VERSION ""

NS_ :

BS_:

BU_: ATCM_DMSM HCM_HS2 PAM_HS2 GSM TRCM GWM _delete SASM SCCM ATCM SUMA_RLM ATCM_FFSM PCU VDM_HS2 TBM OCS GENERIC TSTR RCM

BO_ 1114 TrailerAid_Data_HS2: 8 GWM
 SG_ TrlBrkInitOut_D_Rq : 60|2@0+ (1,0) [0|3] "SED"  TBM
 SG_ TrailCtlSwtch_B_Stat2 : 16|1@0+ (1,0) [0|1] "SED" Vector__XXX

BO_ 939 ParkAid_Aud_Warn_Stat2_HS2: 8 PAM_HS2
 SG_ PrkAidSnsRlSide_D_Stat : 23|4@0+ (1,0) [0|15] "SED"  GWM
 SG_ ApaBrk_D_Rq : 51|2@0+ (1,0) [0|3] "SED"  GWM,GENERIC
 SG_ SidePrkSnsR4_D_Stat : 55|4@0+ (1,0) [0|15] "SED"  GWM,GENERIC
 SG_ SidePrkSnsR3_D_Stat : 47|4@0+ (1,0) [0|15] "SED"  GWM,GENERIC
 SG_ SidePrkSnsL4_D_Stat : 43|4@0+ (1,0) [0|15] "SED"  GWM,GENERIC
 SG_ SidePrkSnsL3_D_Stat : 37|4@0+ (1,0) [0|15] "SED"  GWM,GENERIC
 SG_ PrkAidChime_D_Stat : 4|2@0+ (1,0) [0|3] "SED"  GWM,GENERIC
 SG_ PrkAidSnsRlCntr_D_Stat : 15|4@0+ (1,0) [0|15] "SED"  GWM
 SG_ PrkAidSnsRrCrnr_D_Stat : 31|4@0+ (1,0) [0|15] "SED"  GWM
 SG_ PrkAidSnsRrCntr_D_Stat : 19|4@0+ (1,0) [0|15] "SED"  GWM
 SG_ PrkAidSnsRlCrnr_D_Stat : 11|4@0+ (1,0) [0|15] "SED"  GWM
 SG_ PrkAidRear_D_Stat : 39|2@0+ (1,0) [0|3] "SED"  GWM,GENERIC
 SG_ PrkAidFront_D_Stat : 2|2@0+ (1,0) [0|3] "SED"  GWM,GENERIC
 SG_ PrkAid_D_Falt : 7|3@0+ (1,0) [0|7] "SED"  GWM,GENERIC
 SG_ PrkAidSnsRrSide_D_Stat : 27|4@0+ (1,0) [0|15] "SED"  GWM
 SG_ PrkAidLamp_D_Rq : 33|2@0+ (1,0) [0|3] "SED"  GWM,ATCM_DMSM,GENERIC
 SG_ ApaLongCtrlEnbl_D_Rq : 0|1@0+ (1,0) [0|1] "SED"  GWM
 SG_ ApaBrk_A_Rq : 63|8@0+ (0.05,-12.75) [-12.75|0] "m/sec^2"  GWM

BO_ 938 ParkAid_Aud_Warn_Stat_HS2: 8 PAM_HS2
 SG_ SidePrkSnsR2_D_Stat : 59|4@0+ (1,0) [0|15] "SED"  GWM
 SG_ SidePrkSnsR1_D_Stat : 63|4@0+ (1,0) [0|15] "SED"  GWM
 SG_ SidePrkSnsL2_D_Stat : 51|4@0+ (1,0) [0|15] "SED"  GWM
 SG_ SidePrkSnsL1_D_Stat : 55|4@0+ (1,0) [0|15] "SED"  GWM
 SG_ ApaMde_D_Stat : 23|3@0+ (1,0) [0|7] "SED"  GWM
 SG_ ApaActvSd_D_Actl : 14|2@0+ (1,0) [0|3] "SED"  GWM
 SG_ PrkAidSwtch_B_Stat : 8|1@0+ (1,0) [0|1] "SED"  GWM
 SG_ ApaMde_D_Avail : 12|4@0+ (1,0) [0|15] "SED"  GWM
 SG_ PrkAidSnsFrSide_D_Stat : 43|4@0+ (1,0) [0|15] "SED"  GWM
 SG_ PrkAidSnsFrCrnr_D_Stat : 47|4@0+ (1,0) [0|15] "SED"  GWM
 SG_ PrkAidSnsFrCntr_D_Stat : 35|4@0+ (1,0) [0|15] "SED"  GWM
 SG_ PrkAidSnsFlSide_D_Stat : 39|4@0+ (1,0) [0|15] "SED"  GWM
 SG_ PrkAidSnsFlCrnr_D_Stat : 27|4@0+ (1,0) [0|15] "SED"  GWM
 SG_ PrkAidSnsFlCntr_D_Stat : 31|4@0+ (1,0) [0|15] "SED"  GWM
 SG_ RpaChime_D_Rq : 7|4@0+ (1,0) [0|15] "SED"  GWM
 SG_ FpaChime_D_Rq : 3|4@0+ (1,0) [0|15] "SED"  GWM
 SG_ PrkAidMsgTxt_D_Rq : 19|4@0+ (1,0) [0|15] "SED"  GWM
 SG_ PrkAidAudioMute_B_Rq : 15|1@0+ (1,0) [0|1] "SED"  GWM
 SG_ PrkBrkEl_B_RqFap : 20|1@0+ (1,0) [0|1] "SED"  GWM

BO_ 863 Steering_Data2: 8 SASM
 SG_ SteWhlHeat_D_Stat : 7|4@0+ (1,0) [0|15] "SED"  GWM

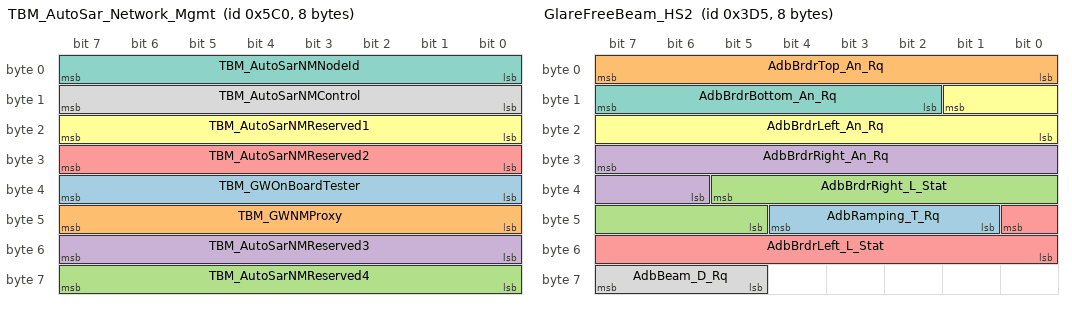
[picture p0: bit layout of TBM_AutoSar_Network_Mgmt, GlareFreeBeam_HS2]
BO_ 1472 TBM_AutoSar_Network_Mgmt: 8 TBM
 SG_ TBM_GWOnBoardTester : 39|8@0+ (1,0) [0|255] "unitless"  GWM
 SG_ TBM_GWNMProxy : 47|8@0+ (1,0) [0|255] "unitless"  GWM
 SG_ TBM_AutoSarNMReserved4 : 63|8@0+ (1,0) [0|255] "unitless"  GWM
 SG_ TBM_AutoSarNMReserved3 : 55|8@0+ (1,0) [0|255] "unitless"  GWM
 SG_ TBM_AutoSarNMReserved2 : 31|8@0+ (1,0) [0|255] "unitless"  GWM
 SG_ TBM_AutoSarNMReserved1 : 23|8@0+ (1,0) [0|255] "unitless"  GWM
 SG_ TBM_AutoSarNMNodeId : 7|8@0+ (1,0) [0|255] "unitless"  GWM
 SG_ TBM_AutoSarNMControl : 15|8@0+ (1,0) [0|255] "unitless"  GWM

BO_ 2612030680 PARSEDPushFcGWM_ECGtoGSM: 8 GWM
 SG_ PARSEDPushFcGWM_ECGtoGSM : 7|29@0+ (1,0) [0|536870911] "unitless"  GSM

BO_ 981 GlareFreeBeam_HS2: 8 GWM
 SG_ AdbRamping_T_Rq : 44|4@0+ (200,0) [0|3000] "millisecond"  HCM_HS2
 SG_ AdbBrdrTop_An_Rq : 7|8@0+ (0.04,-9.54) [-9.54|0.58] "degrees"  HCM_HS2
 SG_ AdbBrdrRight_L_Stat : 37|9@0+ (2,0) [0|1018] "meter"  HCM_HS2
 SG_ AdbBrdrRight_An_Rq : 31|10@0+ (0.04,-20.4) [-20.4|20.44] "degrees"  HCM_HS2
 SG_ AdbBrdrLeft_L_Stat : 40|9@0+ (2,0) [0|1018] "meter"  HCM_HS2
 SG_ AdbBrdrLeft_An_Rq : 9|10@0+ (0.04,-20.4) [-20.4|20.44] "degrees"  HCM_HS2
 SG_ AdbBrdrBottom_An_Rq : 15|6@0+ (0.04,-1.86) [-1.86|0.58] "degrees"  HCM_HS2
 SG_ AdbBeam_D_Rq : 63|3@0+ (1,0) [0|7] "SED"  HCM_HS2

BO_ 2611175451 PARSEDPhysGSMtoGWM_ECG: 8 GSM
 SG_ PARSEDPhysGSMtoGWM_ECG : 7|29@0+ (1,0) [0|536870911] "Unitless"  GWM

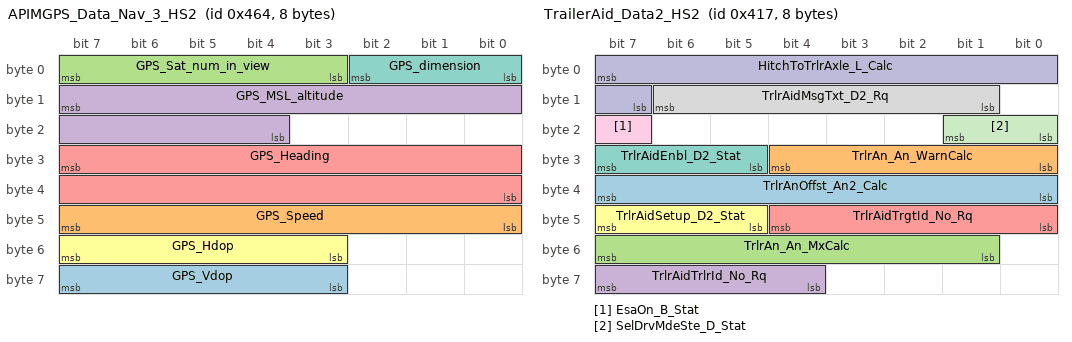
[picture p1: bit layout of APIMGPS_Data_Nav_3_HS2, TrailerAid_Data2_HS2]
BO_ 1124 APIMGPS_Data_Nav_3_HS2: 8 GWM
 SG_ GPS_Vdop : 63|5@0+ (0.2,0) [0|5.8] "unitless"  GENERIC
 SG_ GPS_Speed : 47|8@0+ (1,0) [0|253] "MPH"  GENERIC
 SG_ GPS_Sat_num_in_view : 7|5@0+ (1,0) [0|29] "unitless"  GENERIC
 SG_ GPS_MSL_altitude : 15|12@0+ (10,-20460) [-20460|20470] "feet"  GENERIC
 SG_ GPS_Heading : 31|16@0+ (0.01,0) [0|655.33] "Degrees" Vector__XXX
 SG_ GPS_Hdop : 55|5@0+ (0.2,0) [0|5.8] "unitless"  GENERIC
 SG_ GPS_dimension : 2|3@0+ (1,0) [0|7] "SED"  GENERIC

BO_ 1844 TesterPhysicalReqHCM_HS2: 8 TSTR
 SG_ TesterPhysicalReqHCM : 7|64@0+ (1,0) [0|1.84467E+019] "unitless"  HCM_HS2

BO_ 1852 TesterPhysicalResHCM_HS2: 8 HCM_HS2
 SG_ TesterPhysicalResHCM : 7|64@0+ (1,0) [0|1.84467E+019] "unitless"  TSTR

BO_ 989 Personality_HCM_Data_HS2: 8 HCM_HS2
 SG_ FeatNoHcm_No_Actl : 23|16@0+ (1,0) [0|65535] "Number"  GWM
 SG_ FeatConfigHcmActl : 7|16@0+ (1,0) [0|65535] "Undefined"  GWM

BO_ 2612002008 PARSEDFuncGWM_ECG_HS2: 8 GWM
 SG_ PARSEDFuncGWM_ECG : 7|29@0+ (1,0) [0|536870911] "unitless"  ATCM_DMSM,HCM_HS2,GSM

BO_ 2610953432 OTAFuncGWM_ECG_HS2: 8 GWM
 SG_ OTAFuncGWM_ECG : 7|29@0+ (1,0) [0|536870911] "unitless"  HCM_HS2,GSM,ATCM_DMSM

BO_ 2609933528 OTAPhysGWM_ECGtoGSM: 8 GWM
 SG_ OTAPhysGWM_ECGtoGSM : 7|29@0+ (1,0) [0|536870911] "unitless"  GSM

BO_ 2610126875 OTAPhysGSMtoGWM_ECG: 8 GSM
 SG_ OTAPhysGSMtoGWM_ECG : 7|29@0+ (1,0) [0|536870911] "unitless"  GWM

BO_ 1105 Image_Processing_Data_HS2: 8 GWM
 SG_ TrlrRvrseEnbl_D2_Stat : 18|3@0+ (1,0) [0|7] "SED"  GENERIC,PAM_HS2
 SG_ TrlrRvrseMsgTxt_D2_Rq : 31|6@0+ (1,0) [0|63] "SED"  GENERIC,PAM_HS2
 SG_ RbaMsg_D_Rq : 22|2@0+ (1,0) [0|3] "SED"  GENERIC
 SG_ BrkDecel_B_RqRba : 8|1@0+ (1,0) [0|1] "SED"  GENERIC
 SG_ BrkEnbl_B_RqRba : 23|1@0+ (1,0) [0|1] "SED"  GENERIC
 SG_ Rba_D_Stat : 14|2@0+ (1,0) [0|3] "SED"  GENERIC
 SG_ RbaAlrt_D_Dsply : 12|2@0+ (1,0) [0|3] "SED"  GENERIC
 SG_ RbaMnu_D_Rq : 10|2@0+ (1,0) [0|3] "SED"  GENERIC
 SG_ RbaSys_D_Stat : 20|2@0+ (1,0) [0|3] "SED"  GENERIC
 SG_ CamraFrntStat_D_Stat : 7|2@0+ (1,0) [0|3] "SED"  GENERIC
 SG_ TrlrHitchLamp_D_Rq2 : 15|1@0+ (1,0) [0|1] "SED"  GENERIC
 SG_ ClrExitAsstMsgTxt2_D_Rq : 55|4@0+ (1,0) [0|15] "SED"  GENERIC
 SG_ ClrExitAsstActv_B_Rq : 24|1@0+ (1,0) [0|1] "SED"  GENERIC
 SG_ CamraFrntOffRd_B_Stat : 25|1@0+ (1,0) [0|1] "SED"  GENERIC
 SG_ TrlrAidSwtchLamp_B_Rq : 32|1@0+ (1,0) [0|1] "SED"  ATCM,ATCM_DMSM,ATCM_FFSM
 SG_ TrlrAidEnbl_D_RqAdas : 5|3@0+ (1,0) [0|7] "SED"  GENERIC
 SG_ TrlrHitchMsgTxt_D_Rq : 47|6@0+ (1,0) [0|63] "SED"  GENERIC
 SG_ TrlrHitchIcon_D_Rq : 36|4@0+ (1,0) [0|15] "SED"  GENERIC
 SG_ TrlrHitchChime_D_Rq : 39|3@0+ (1,0) [0|7] "SED"  GENERIC

BO_ 1056 SelectDriveModeData_HS2: 8 GWM
 SG_ SelDrvMdePos12_B_Avail : 54|1@0+ (1,0) [0|1] "SED" Vector__XXX
 SG_ SelDrvMdePos11_B_Avail : 55|1@0+ (1,0) [0|1] "SED" Vector__XXX
 SG_ SelDrvMdePos10_B_Avail : 40|1@0+ (1,0) [0|1] "SED" Vector__XXX
 SG_ SelDrvMdePos09_B_Avail : 41|1@0+ (1,0) [0|1] "SED" Vector__XXX
 SG_ SelDrvMdePos08_B_Avail : 42|1@0+ (1,0) [0|1] "SED" Vector__XXX
 SG_ SelDrvMdePos07_B_Avail : 43|1@0+ (1,0) [0|1] "SED" Vector__XXX
 SG_ SelDrvMdePos06_B_Avail : 44|1@0+ (1,0) [0|1] "SED" Vector__XXX
 SG_ SelDrvMdePos05_B_Avail : 45|1@0+ (1,0) [0|1] "SED" Vector__XXX
 SG_ SelDrvMdePos04_B_Avail : 46|1@0+ (1,0) [0|1] "SED" Vector__XXX
 SG_ SelDrvMdePos03_B_Avail : 47|1@0+ (1,0) [0|1] "SED" Vector__XXX
 SG_ SelDrvMdePos02_B_Avail : 32|1@0+ (1,0) [0|1] "SED" Vector__XXX
 SG_ SelDrvMdePos01_B_Avail : 24|1@0+ (1,0) [0|1] "SED" Vector__XXX
 SG_ ActvDrvMde_D2_Stat : 53|5@0+ (1,0) [0|31] "SED" Vector__XXX
 SG_ SelDrvMde_D2_Rq : 63|5@0+ (1,0) [0|31] "SED"  ATCM_DMSM
 SG_ AwdMde_D_RqBrk : 35|3@0+ (1,0) [0|7] "SED" Vector__XXX
 SG_ SelDrvMdePt_D_Rq : 31|5@0+ (1,0) [0|31] "SED" Vector__XXX
 SG_ SelDrvMdeMsgTxt_D_Rq : 19|4@0+ (1,0) [0|15] "SED"  ATCM_DMSM
 SG_ SelDrvMde_D_Stat : 26|2@0+ (1,0) [0|3] "SED" Vector__XXX
 SG_ AutoEpbButtnOn_B_Stat : 48|1@0+ (1,0) [0|1] "SED"  GENERIC
 SG_ AutoEpbMsgTxt_D_Rq : 58|3@0+ (1,0) [0|7] "SED"  GENERIC
 SG_ AutoEpbDsply_D_Stat : 37|2@0+ (1,0) [0|3] "SED"  GENERIC
 SG_ SelDrvMdeHmi03_D_Rq : 12|5@0+ (1,0) [0|31] "SED"  GENERIC
 SG_ SelDrvMdeMsgTxt2_D_Rq : 23|4@0+ (1,0) [0|15] "SED"  GENERIC

BO_ 1047 TrailerAid_Data2_HS2: 8 GWM
 SG_ TrlrAnOffst_An2_Calc : 39|8@0+ (0.5,-64) [-64|63.5] "degrees" Vector__XXX
 SG_ TrlrAn_An_WarnCalc : 28|5@0+ (1,0) [0|31] "degrees" Vector__XXX
 SG_ TrlrAn_An_MxCalc : 55|7@0+ (1,0) [0|127] "degrees" Vector__XXX
 SG_ TrlrAidTrlrId_No_Rq : 63|4@0+ (1,0) [0|15] "unitless" Vector__XXX
 SG_ TrlrAidTrgtId_No_Rq : 44|5@0+ (1,0) [0|31] "unitless" Vector__XXX
 SG_ TrlrAidSetup_D2_Stat : 47|3@0+ (1,0) [0|7] "SED" Vector__XXX
 SG_ TrlrAidEnbl_D2_Stat : 31|3@0+ (1,0) [0|7] "SED"  ATCM_DMSM,PAM_HS2
 SG_ TrlrAidMsgTxt_D2_Rq : 14|6@0+ (1,0) [0|63] "SED"  ATCM_DMSM,PAM_HS2
 SG_ EsaOn_B_Stat : 23|1@0+ (1,0) [0|1] "SED" Vector__XXX
 SG_ HitchToTrlrAxle_L_Calc : 7|9@0+ (0.0254,0) [0|12.9794] "meter" Vector__XXX
 SG_ SelDrvMdeSte_D_Stat : 17|2@0+ (1,0) [0|3] "SED" Vector__XXX

BO_ 1892 TesterPhysicalReqCCM_HS2: 8 TSTR
 SG_ TesterPhysicalReqCCM : 7|64@0+ (1,0) [0|1.84467E+019] "unitless" Vector__XXX

BO_ 1969 TesterPhysicalReqIPMB_HS2: 8 TSTR
 SG_ TesterPhysicalReqIPMB : 7|64@0+ (1,0) [0|1.84467E+019] "unitless" Vector__XXX

BO_ 1798 TesterPhysicalReqIPMA_HS2: 8 TSTR
 SG_ TesterPhysicalReqIPMA : 7|64@0+ (1,0) [0|1.84467E+019] "unitless" Vector__XXX

BO_ 1900 TesterPhysicalResCCM_HS2: 8 Vector__XXX
 SG_ TesterPhysicalResCCM : 7|64@0+ (1,0) [0|1.84467E+019] "unitless"  TSTR

BO_ 1806 TesterPhysicalResIPMA_HS2: 8 Vector__XXX
 SG_ TesterPhysicalResIPMA : 7|64@0+ (1,0) [0|1.84467E+019] "unitless"  TSTR

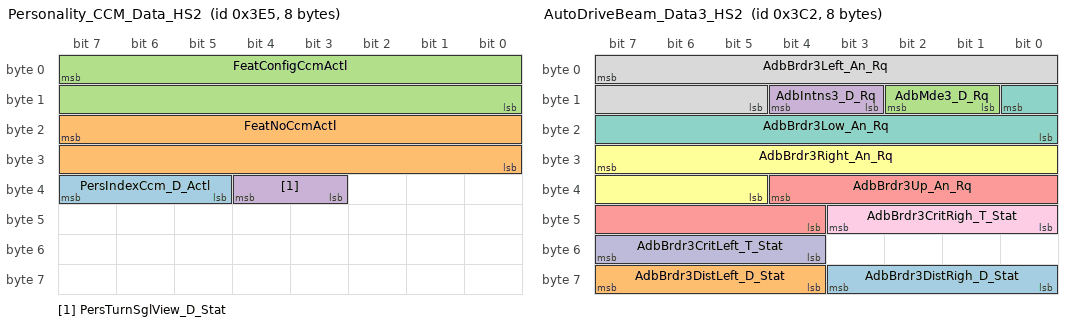
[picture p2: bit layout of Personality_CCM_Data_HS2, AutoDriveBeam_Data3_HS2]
BO_ 997 Personality_CCM_Data_HS2: 8 Vector__XXX
 SG_ PersIndexCcm_D_Actl : 39|3@0+ (1,0) [0|7] "SED"  GWM
 SG_ FeatNoCcmActl : 23|16@0+ (1,0) [0|65535] "Number"  GWM
 SG_ FeatConfigCcmActl : 7|16@0+ (1,0) [0|65535] "Undefined"  GWM
 SG_ PersTurnSglView_D_Stat : 36|2@0+ (1,0) [0|3] "SED"  GWM,GENERIC

BO_ 962 AutoDriveBeam_Data3_HS2: 8 GWM
 SG_ AdbBrdr3DistRigh_D_Stat : 59|4@0+ (1,0) [0|15] "SED"  GWM,HCM_HS2
 SG_ AdbBrdr3DistLeft_D_Stat : 63|4@0+ (1,0) [0|15] "SED"  GWM,HCM_HS2
 SG_ AdbMde3_D_Rq : 10|2@0+ (1,0) [0|3] "SED"  GWM,HCM_HS2
 SG_ AdbIntns3_D_Rq : 12|2@0+ (1,0) [0|3] "SED"  GWM,HCM_HS2
 SG_ AdbBrdr3Up_An_Rq : 36|9@0+ (0.02,-8) [-8|2.18] "degrees"  GWM,HCM_HS2
 SG_ AdbBrdr3Right_An_Rq : 31|11@0+ (0.02,-20) [-20|20.9] "degrees"  GWM,HCM_HS2
 SG_ AdbBrdr3Low_An_Rq : 8|9@0+ (0.02,-8) [-8|2.18] "degrees"  GWM,HCM_HS2
 SG_ AdbBrdr3Left_An_Rq : 7|11@0+ (0.02,-20) [-20|20.9] "degrees"  GWM,HCM_HS2
 SG_ AdbBrdr3CritRigh_T_Stat : 43|4@0+ (100,0) [0|1500] "millisecond"  GWM,HCM_HS2
 SG_ AdbBrdr3CritLeft_T_Stat : 55|4@0+ (100,0) [0|1500] "millisecond"  GWM,HCM_HS2

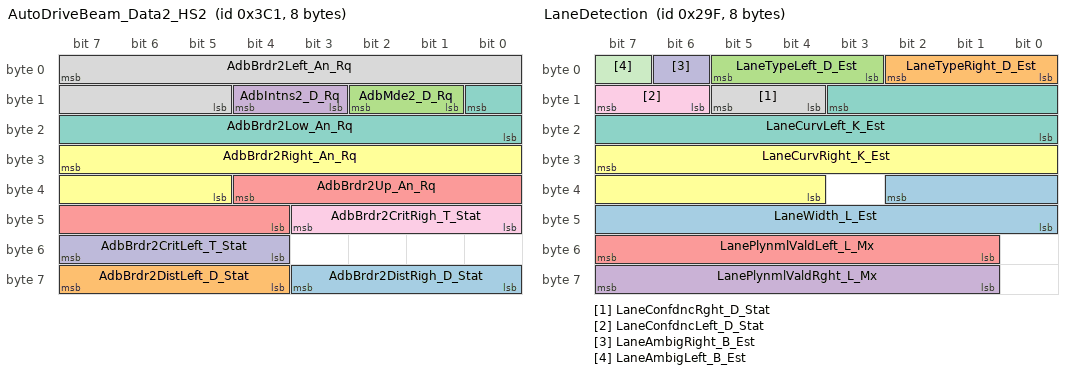
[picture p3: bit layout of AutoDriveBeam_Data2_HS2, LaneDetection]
BO_ 961 AutoDriveBeam_Data2_HS2: 8 GWM
 SG_ AdbBrdr2DistRigh_D_Stat : 59|4@0+ (1,0) [0|15] "SED"  GWM,HCM_HS2
 SG_ AdbBrdr2DistLeft_D_Stat : 63|4@0+ (1,0) [0|15] "SED"  GWM,HCM_HS2
 SG_ AdbMde2_D_Rq : 10|2@0+ (1,0) [0|3] "SED"  GWM,HCM_HS2
 SG_ AdbIntns2_D_Rq : 12|2@0+ (1,0) [0|3] "SED"  GWM,HCM_HS2
 SG_ AdbBrdr2Up_An_Rq : 36|9@0+ (0.02,-8) [-8|2.18] "degrees"  GWM,HCM_HS2
 SG_ AdbBrdr2Right_An_Rq : 31|11@0+ (0.02,-20) [-20|20.9] "degrees"  GWM,HCM_HS2
 SG_ AdbBrdr2Low_An_Rq : 8|9@0+ (0.02,-8) [-8|2.18] "degrees"  GWM,HCM_HS2
 SG_ AdbBrdr2Left_An_Rq : 7|11@0+ (0.02,-20) [-20|20.9] "degrees"  GWM,HCM_HS2
 SG_ AdbBrdr2CritRigh_T_Stat : 43|4@0+ (100,0) [0|1500] "millisecond"  GWM,HCM_HS2
 SG_ AdbBrdr2CritLeft_T_Stat : 55|4@0+ (100,0) [0|1500] "millisecond"  GWM,HCM_HS2

BO_ 394 ACCDATA_3_HS2: 8 Vector__XXX
 SG_ AccTrgDist2_D_Dsply : 27|4@0+ (1,0) [0|15] "SED"  GWM
 SG_ AccStopRes_B_Dsply : 54|1@0+ (1,0) [0|1] "SED"  GWM
 SG_ TjaWarn_D_Rq : 50|3@0+ (1,0) [0|7] "SED"  GWM
 SG_ Tja_D_Stat : 44|3@0+ (1,0) [0|7] "SED"  GWM
 SG_ IaccLamp_D_Rq : 46|2@0+ (1,0) [0|3] "SED"  GWM
 SG_ AccMsgTxt_D2_Rq : 31|4@0+ (1,0) [0|15] "SED"  GWM
 SG_ TjaMsgTxt_D_Dsply : 53|3@0+ (1,0) [0|7] "SED"  GWM
 SG_ FcwDeny_B_Dsply : 10|1@0+ (1,0) [0|1] "SED"  GWM
 SG_ FcwMemStat_B_Actl : 13|1@0+ (1,0) [0|1] "SED"  GWM
 SG_ AccTGap_B_Dsply : 35|1@0+ (1,0) [0|1] "SED"  GWM
 SG_ CadsAlignIncplt_B_Actl : 11|1@0+ (1,0) [0|1] "SED"  GWM
 SG_ AccFllwMde_B_Dsply : 17|1@0+ (1,0) [0|1] "SED"  GWM
 SG_ CadsRadrBlck_B_Actl : 22|1@0+ (1,0) [0|1] "SED"  GWM
 SG_ CmbbPostEvnt_B_Dsply : 15|1@0+ (1,0) [0|1] "SED"  GWM
 SG_ AccStopMde_B_Dsply : 0|1@0+ (1,0) [0|1] "SED"  GWM
 SG_ FcwMemSens_D_Actl : 20|2@0+ (1,0) [0|3] "SED"  GWM
 SG_ FcwMsgTxt_D_Rq : 7|3@0+ (1,0) [0|7] "SED"  GWM
 SG_ AccTGap_D_Dsply : 34|3@0+ (1,0) [0|7] "SED"  GWM
 SG_ AccMemEnbl_B_RqDrv : 36|1@0+ (1,0) [0|1] "SED"  GWM
 SG_ AccWarn_D_Dsply : 39|2@0+ (1,0) [0|3] "SED"  GWM
 SG_ FcwVisblWarn_B_Rq : 47|1@0+ (1,0) [0|1] "SED"  GWM
 SG_ FcwAudioWarn_B_Rq : 8|1@0+ (1,0) [0|1] "SED"  GWM
 SG_ AccStopStat_D_Dsply : 41|2@0+ (1,0) [0|3] "SED"  GENERIC,GWM

BO_ 671 LaneDetection: 8 Vector__XXX
 SG_ LaneWidth_L_Est : 34|11@0+ (0.005,0) [0|10.235] "meter"  GWM
 SG_ LaneTypeRight_D_Est : 2|3@0+ (1,0) [0|7] "SED"  GWM
 SG_ LaneTypeLeft_D_Est : 5|3@0+ (1,0) [0|7] "SED"  GWM
 SG_ LanePlynmlValdRght_L_Mx : 63|7@0+ (1,0) [0|127] "meter"  GWM
 SG_ LanePlynmlValdLeft_L_Mx : 55|7@0+ (1,0) [0|127] "meter"  GWM
 SG_ LaneCurvRight_K_Est : 31|12@0+ (5E-006,-0.01024) [-0.01024|0.01023] "1/meter"  GWM
 SG_ LaneCurvLeft_K_Est : 11|12@0+ (5E-006,-0.01024) [-0.01024|0.01023] "1/meter"  GWM
 SG_ LaneConfdncRght_D_Stat : 13|2@0+ (1,0) [0|3] "SED"  GWM
 SG_ LaneConfdncLeft_D_Stat : 15|2@0+ (1,0) [0|3] "SED"  GWM
 SG_ LaneAmbigRight_B_Est : 6|1@0+ (1,0) [0|1] "SED"  GWM
 SG_ LaneAmbigLeft_B_Est : 7|1@0+ (1,0) [0|1] "SED"  GWM

BO_ 1854 TesterPhysicalResPAM_HS2: 8 PAM_HS2
 SG_ TesterPhysicalResPAM : 7|64@0+ (1,0) [0|1.84467E+019] "unitless"  TSTR

BO_ 942 ParkAid_Data_3_HS2: 8 PAM_HS2
 SG_ PrkBrkElRleas_B_RqApa : 50|1@0+ (1,0) [0|1] "SED"  GWM
 SG_ PrkAidAcsyRear_D_Stat : 18|2@0+ (1,0) [0|3] "SED"  GWM
 SG_ PrkAidAcsyFront_D_Stat : 20|2@0+ (1,0) [0|3] "SED"  GWM
 SG_ ApaSys_D2_Stat : 35|4@0+ (1,0) [0|15] "SED"  GWM
 SG_ ApaSlotTrgt_D_Stat : 39|4@0+ (1,0) [0|15] "SED"  GWM
 SG_ ApaSlotOption_B_Avail : 43|1@0+ (1,0) [0|1] "SED"  GWM
 SG_ ApaSlotAlrtSet_B_Stat : 44|1@0+ (1,0) [0|1] "SED"  GWM
 SG_ ApaSlotAlrt_B_Rq : 45|1@0+ (1,0) [0|1] "SED"  GWM
 SG_ ApaRmtFeatSel_B_Avail : 46|1@0+ (1,0) [0|1] "SED"  GWM
 SG_ ApaParkOutSel_B_Avail : 47|1@0+ (1,0) [0|1] "SED"  GWM
 SG_ ApaParkInSel_B_Avail : 24|1@0+ (1,0) [0|1] "SED"  GWM
 SG_ ApaMsgTxt_D2_Stat : 28|4@0+ (1,0) [0|15] "SED"  GWM
 SG_ ApaDynmcSlot_B_Stat : 29|1@0+ (1,0) [0|1] "SED"  GWM
 SG_ ApaDisplayMode_D_Stat : 31|2@0+ (1,0) [0|3] "SED"  GWM
 SG_ ApaControlMode_D_Stat : 16|1@0+ (1,0) [0|1] "SED"  GWM
 SG_ PrkAidRdiusRight_L_Dsply : 15|8@0+ (1,0) [0|255] "unitless"  GWM
 SG_ PrkAidRdiusLeft_L_Dsply : 7|8@0+ (1,0) [0|255] "unitless"  GWM
 SG_ PrkAidDrvDir_D_Stat : 23|3@0+ (1,0) [0|7] "SED"  GWM

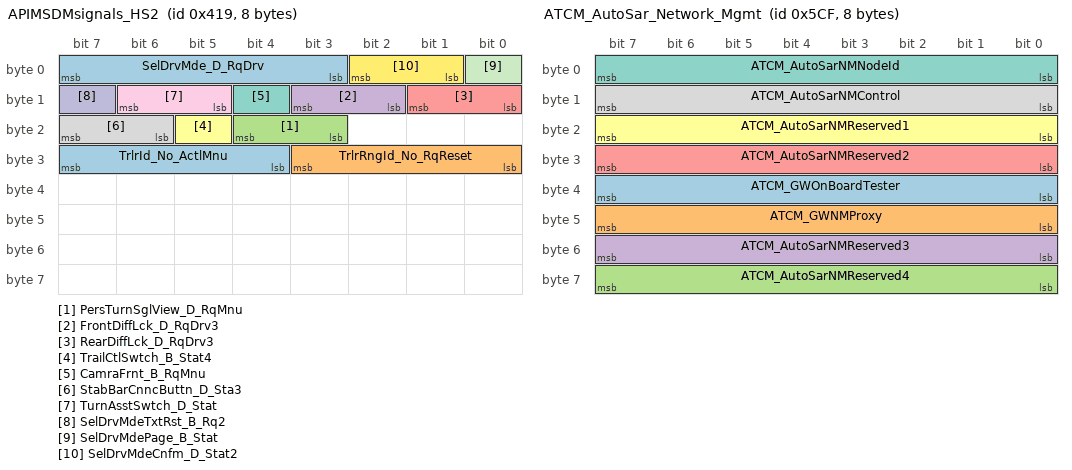
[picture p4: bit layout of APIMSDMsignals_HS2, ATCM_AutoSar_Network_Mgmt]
BO_ 1049 APIMSDMsignals_HS2: 8 GWM
 SG_ TrlrId_No_ActlMnu : 31|4@0+ (1,0) [0|15] "unitless"  GENERIC
 SG_ TrlrRngId_No_RqReset : 27|4@0+ (1,0) [0|15] "unitless"  GENERIC
 SG_ PersTurnSglView_D_RqMnu : 20|2@0+ (1,0) [0|3] "SED"  GENERIC
 SG_ FrontDiffLck_D_RqDrv3 : 11|2@0+ (1,0) [0|3] "SED"  ATCM_DMSM
 SG_ RearDiffLck_D_RqDrv3 : 9|2@0+ (1,0) [0|3] "SED"  ATCM_DMSM
 SG_ TrailCtlSwtch_B_Stat4 : 21|1@0+ (1,0) [0|1] "SED"  GENERIC
 SG_ CamraFrnt_B_RqMnu : 12|1@0+ (1,0) [0|1] "SED"  GENERIC
 SG_ StabBarCnncButtn_D_Sta3 : 23|2@0+ (1,0) [0|3] "SED"  ATCM_DMSM
 SG_ TurnAsstSwtch_D_Stat : 14|2@0+ (1,0) [0|3] "SED"  GENERIC
 SG_ SelDrvMdeTxtRst_B_Rq2 : 15|1@0+ (1,0) [0|1] "SED"  GENERIC
 SG_ SelDrvMdePage_B_Stat : 0|1@0+ (1,0) [0|1] "SED"  GENERIC
 SG_ SelDrvMdeCnfm_D_Stat2 : 2|2@0+ (1,0) [0|3] "SED" Vector__XXX
 SG_ SelDrvMde_D_RqDrv : 7|5@0+ (1,0) [0|31] "SED"  GENERIC

BO_ 1487 ATCM_AutoSar_Network_Mgmt: 8 ATCM_FFSM
 SG_ ATCM_GWOnBoardTester : 39|8@0+ (1,0) [0|255] "unitless"  GWM
 SG_ ATCM_GWNMProxy : 47|8@0+ (1,0) [0|255] "unitless"  GWM
 SG_ ATCM_AutoSarNMReserved4 : 63|8@0+ (1,0) [0|255] "unitless"  GWM
 SG_ ATCM_AutoSarNMReserved3 : 55|8@0+ (1,0) [0|255] "unitless"  GWM
 SG_ ATCM_AutoSarNMReserved2 : 31|8@0+ (1,0) [0|255] "unitless"  GWM
 SG_ ATCM_AutoSarNMReserved1 : 23|8@0+ (1,0) [0|255] "unitless"  GWM
 SG_ ATCM_AutoSarNMNodeId : 7|8@0+ (1,0) [0|255] "unitless"  GWM
 SG_ ATCM_AutoSarNMControl : 15|8@0+ (1,0) [0|255] "unitless"  GWM

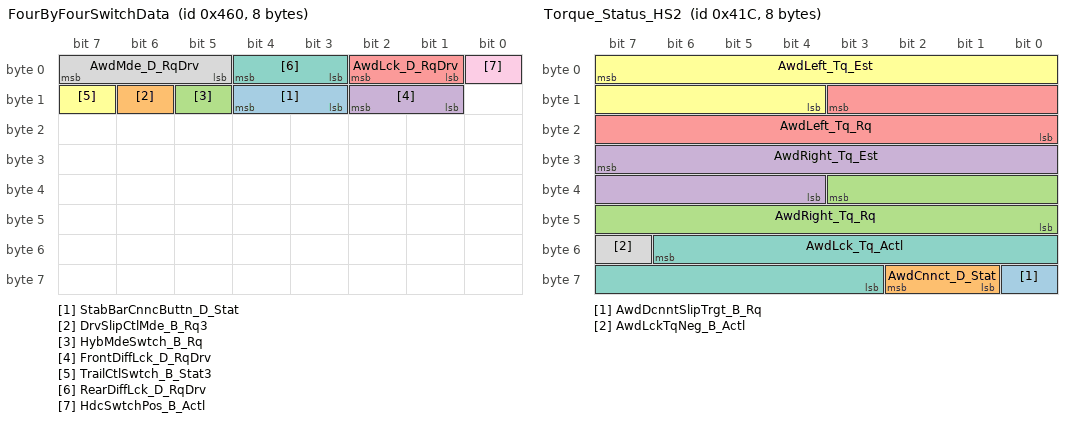
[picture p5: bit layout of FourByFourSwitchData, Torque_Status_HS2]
BO_ 1120 FourByFourSwitchData: 8 ATCM_DMSM
 SG_ StabBarCnncButtn_D_Stat : 12|2@0+ (1,0) [0|3] "SED"  GWM
 SG_ DrvSlipCtlMde_B_Rq3 : 14|1@0+ (1,0) [0|1] "SED"  GWM
 SG_ HybMdeSwtch_B_Rq : 13|1@0+ (1,0) [0|1] "SED"  GWM
 SG_ FrontDiffLck_D_RqDrv : 10|2@0+ (1,0) [0|3] "SED"  GWM
 SG_ AwdLck_D_RqDrv : 2|2@0+ (1,0) [0|3] "SED"  GWM
 SG_ TrailCtlSwtch_B_Stat3 : 15|1@0+ (1,0) [0|1] "SED"  GWM
 SG_ RearDiffLck_D_RqDrv : 4|2@0+ (1,0) [0|3] "SED"  GWM
 SG_ AwdMde_D_RqDrv : 7|3@0+ (1,0) [0|7] "SED"  GWM
 SG_ HdcSwtchPos_B_Actl : 0|1@0+ (1,0) [0|1] "SED" Vector__XXX

BO_ 1997 TesterPhysicalResSECM_AFSM: 8 SASM
 SG_ TesterPhysicalResSECM_AFSM : 7|64@0+ (1,0) [0|1.84467E+019] "unitless"  TSTR

BO_ 1989 TesterPhysicalReqSECM_AFSM: 8 TSTR
 SG_ TesterPhysicalReqSECM_AFSM : 7|64@0+ (1,0) [0|1.84467E+019] "unitless"  SASM

BO_ 1052 Torque_Status_HS2: 8 GWM
 SG_ AwdDcnntSlipTrgt_B_Rq : 56|1@0+ (1,0) [0|1] "SED" Vector__XXX
 SG_ AwdCnnct_D_Stat : 58|2@0+ (1,0) [0|3] "SED" Vector__XXX
 SG_ AwdRight_Tq_Rq : 35|12@0+ (1,0) [0|4093] "Nm" Vector__XXX
 SG_ AwdRight_Tq_Est : 31|12@0+ (1,0) [0|4093] "Nm" Vector__XXX
 SG_ AwdLeft_Tq_Rq : 11|12@0+ (1,0) [0|4093] "Nm" Vector__XXX
 SG_ AwdLeft_Tq_Est : 7|12@0+ (1,0) [0|4093] "Nm" Vector__XXX
 SG_ AwdLck_Tq_Actl : 54|12@0+ (1,0) [0|4093] "Nm"  GENERIC
 SG_ AwdLckTqNeg_B_Actl : 55|1@0+ (1,0) [0|1] "SED"  GENERIC

BO_ 139 CruiseCtrl_Steering_Data: 8 SASM
 SG_ AccButtnGpTogglePress2 : 25|1@0+ (1,0) [0|1] "SED"  GWM,SCCM
 SG_ TjaButtnOnOffPress2 : 26|1@0+ (1,0) [0|1] "SED"  GWM,SCCM
 SG_ ActvFrontSteMsgTxt_D_Rq : 31|3@0+ (1,0) [0|7] "SED"  GWM
 SG_ ActvFrontSteLck_D_Stat : 17|2@0+ (1,0) [0|3] "SED"  GWM
 SG_ SelDrvMdeAdptSte_D_Stat : 28|2@0+ (1,0) [0|3] "SED"  GWM
 SG_ AslButtnOnOffPress2 : 4|1@0+ (1,0) [0|1] "SED"  GWM,SCCM
 SG_ AslButtnOnOffCnclPres2 : 5|1@0+ (1,0) [0|1] "SED"  GWM,SCCM
 SG_ CcButtnOnPress2 : 18|1@0+ (1,0) [0|1] "SED"  GWM,SCCM
 SG_ CcButtnOnOffPress2 : 19|1@0+ (1,0) [0|1] "SED"  GWM,SCCM
 SG_ CcButtnOnOffCnclPress2 : 20|1@0+ (1,0) [0|1] "SED"  GWM,SCCM
 SG_ CcButtnOffPress2 : 21|1@0+ (1,0) [0|1] "SED"  GWM,SCCM
 SG_ CcAsllButtnResPress2 : 22|1@0+ (1,0) [0|1] "SED"  GWM,SCCM
 SG_ CcAslButtnSetPress2 : 23|1@0+ (1,0) [0|1] "SED"  GWM,SCCM
 SG_ CcAslButtnSetIncPress2 : 8|1@0+ (1,0) [0|1] "SED"  GWM,SCCM
 SG_ CcAslButtnSetDecPress2 : 9|1@0+ (1,0) [0|1] "SED"  GWM,SCCM
 SG_ CcAslButtnResIncPress2 : 10|1@0+ (1,0) [0|1] "SED"  GWM,SCCM
 SG_ CcAslButtnResDecPress2 : 11|1@0+ (1,0) [0|1] "SED"  GWM,SCCM
 SG_ CcAslButtnOnPress2 : 12|1@0+ (1,0) [0|1] "SED"  GWM,SCCM
 SG_ CcAslButtnOnOffCncl2 : 13|1@0+ (1,0) [0|1] "SED"  GWM,SCCM
 SG_ CcAslButtnOffCnclPres2 : 14|1@0+ (1,0) [0|1] "SED"  GWM,SCCM
 SG_ CcAslButtnIndxIncPres2 : 15|1@0+ (1,0) [0|1] "SED"  GWM,SCCM
 SG_ CcAslButtnIndxDecPres2 : 0|1@0+ (1,0) [0|1] "SED"  GWM,SCCM
 SG_ CcAslButtnDeny_B_Actl2 : 1|1@0+ (1,0) [0|1] "SED"  GWM,SCCM
 SG_ CcAslButtnCnclResPres2 : 2|1@0+ (1,0) [0|1] "SED"  GWM,SCCM
 SG_ CcAslButtnCnclPress2 : 3|1@0+ (1,0) [0|1] "SED"  GWM,SCCM
 SG_ AccButtnGapIncPress2 : 6|1@0+ (1,0) [0|1] "SED"  GWM,SCCM
 SG_ AccButtnGapDecPress2 : 7|1@0+ (1,0) [0|1] "SED"  GWM,SCCM
 SG_ AfsPw_B_Rq : 24|1@0+ (1,0) [0|1] "SED"  GWM

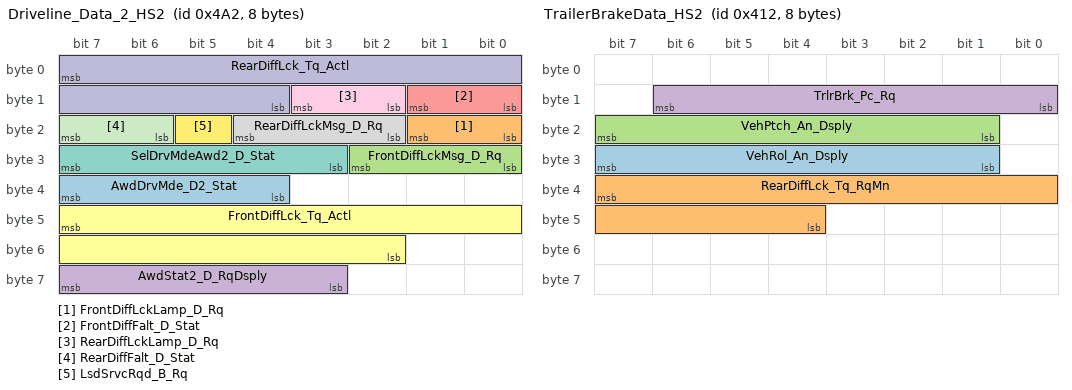
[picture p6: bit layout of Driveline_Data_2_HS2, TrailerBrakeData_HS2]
BO_ 1186 Driveline_Data_2_HS2: 8 GWM
 SG_ AwdDrvMde_D2_Stat : 39|4@0+ (1,0) [0|15] "SED" Vector__XXX
 SG_ FrontDiffLckLamp_D_Rq : 17|2@0+ (1,0) [0|3] "SED"  ATCM_DMSM
 SG_ FrontDiffLckMsg_D_Rq : 26|3@0+ (1,0) [0|7] "SED"  GENERIC
 SG_ AwdStat2_D_RqDsply : 63|5@0+ (1,0) [0|31] "SED"  GENERIC
 SG_ FrontDiffFalt_D_Stat : 9|2@0+ (1,0) [0|3] "SED"  GENERIC
 SG_ FrontDiffLck_Tq_Actl : 47|14@0+ (1,0) [0|16381] "Nm"  GENERIC
 SG_ SelDrvMdeAwd2_D_Stat : 31|5@0+ (1,0) [0|31] "SED"  GENERIC
 SG_ RearDiffLckMsg_D_Rq : 20|3@0+ (1,0) [0|7] "SED" Vector__XXX
 SG_ RearDiffLckLamp_D_Rq : 11|2@0+ (1,0) [0|3] "SED"  ATCM_FFSM,ATCM_DMSM
 SG_ RearDiffLck_Tq_Actl : 7|12@0+ (1,0) [0|4093] "Nm" Vector__XXX
 SG_ RearDiffFalt_D_Stat : 23|2@0+ (1,0) [0|3] "SED" Vector__XXX
 SG_ LsdSrvcRqd_B_Rq : 21|1@0+ (1,0) [0|1] "SED" Vector__XXX

BO_ 1042 TrailerBrakeData_HS2: 8 GWM
 SG_ VehRol_An_Dsply : 31|7@0+ (1,-64) [-64|61] "degrees" Vector__XXX
 SG_ RearDiffLck_Tq_RqMn : 39|12@0+ (4,0) [0|16376] "Nm" Vector__XXX
 SG_ VehPtch_An_Dsply : 23|7@0+ (1,-64) [-64|61] "degrees" Vector__XXX
 SG_ TrlrBrk_Pc_Rq : 14|7@0+ (1,0) [0|127] "percent"  TBM

BO_ 138 ActiveFrontSteering_Stat2: 8 SASM
 SG_ SteWhlRelCalib_T_Actl : 7|8@0+ (1,0) [0|255] "ms"  GWM
 SG_ SteWhlRelCalib_An_Sns : 15|15@0+ (0.1,-1600) [-1600|1676.5] "deg"  GWM,RCM

BO_ 1878 TesterPhysicalReqPBM: 8 TSTR
 SG_ TesterPhysicalReqPBM : 7|64@0+ (1,0) [0|1.84467E+019] "unitless" Vector__XXX

BO_ 1951 TesterPhysicalResSASM: 8 SASM
 SG_ TesterPhysicalResSASM : 7|64@0+ (1,0) [0|1.84467E+019] "unitless"  TSTR

BO_ 1943 TesterPhysicalReqSASM: 8 TSTR
 SG_ TesterPhysicalReqSASM : 7|64@0+ (1,0) [0|1.84467E+019] "unitless"  SASM

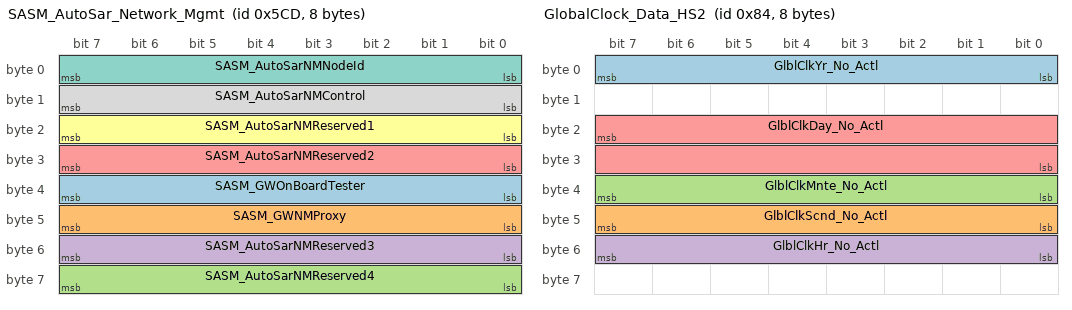
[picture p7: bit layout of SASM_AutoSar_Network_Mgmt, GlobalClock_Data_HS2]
BO_ 1485 SASM_AutoSar_Network_Mgmt: 8 SASM
 SG_ SASM_GWOnBoardTester : 39|8@0+ (1,0) [0|255] "unitless"  GWM
 SG_ SASM_GWNMProxy : 47|8@0+ (1,0) [0|255] "unitless"  GWM
 SG_ SASM_AutoSarNMReserved4 : 63|8@0+ (1,0) [0|255] "unitless"  GWM
 SG_ SASM_AutoSarNMReserved3 : 55|8@0+ (1,0) [0|255] "unitless"  GWM
 SG_ SASM_AutoSarNMReserved2 : 31|8@0+ (1,0) [0|255] "unitless"  GWM
 SG_ SASM_AutoSarNMReserved1 : 23|8@0+ (1,0) [0|255] "unitless"  GWM
 SG_ SASM_AutoSarNMNodeId : 7|8@0+ (1,0) [0|255] "unitless"  GWM
 SG_ SASM_AutoSarNMControl : 15|8@0+ (1,0) [0|255] "unitless"  GWM

BO_ 132 GlobalClock_Data_HS2: 8 GWM
 SG_ GlblClkYr_No_Actl : 7|8@0+ (1,2000) [2000|2255] "year"  RCM
 SG_ GlblClkScnd_No_Actl : 47|8@0+ (1,0) [0|255] "second"  RCM
 SG_ GlblClkMnte_No_Actl : 39|8@0+ (1,0) [0|255] "minute"  RCM
 SG_ GlblClkHr_No_Actl : 55|8@0+ (1,0) [0|255] "hour"  RCM
 SG_ GlblClkDay_No_Actl : 23|16@0+ (1,0) [0|65535] "julian day"  RCM

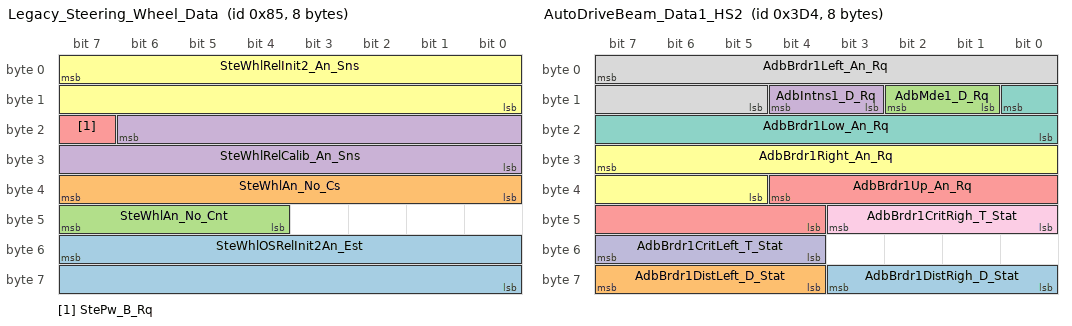
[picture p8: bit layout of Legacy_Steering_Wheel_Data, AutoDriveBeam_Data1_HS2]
BO_ 133 Legacy_Steering_Wheel_Data: 8 GENERIC
 SG_ SteWhlOSRelInit2An_Est : 55|16@0+ (0.1,-3200) [-3200|3353.3] "deg"  GENERIC
 SG_ SteWhlAn_No_Cs : 39|8@0+ (1,0) [0|255] "Unitless"  GENERIC
 SG_ SteWhlAn_No_Cnt : 47|4@0+ (1,0) [0|15] "Counts"  GENERIC
 SG_ SteWhlRelCalib_An_Sns : 22|15@0+ (0.1,-1600) [-1600|1676.5] "deg"  GENERIC
 SG_ StePw_B_Rq : 23|1@0+ (1,0) [0|1] "SED"  GENERIC
 SG_ SteWhlRelInit2_An_Sns : 7|16@0+ (0.1,-3200) [-3200|3353.3] "degrees"  GENERIC

BO_ 980 AutoDriveBeam_Data1_HS2: 8 Vector__XXX
 SG_ AdbBrdr1DistRigh_D_Stat : 59|4@0+ (1,0) [0|15] "SED"  GWM,HCM_HS2
 SG_ AdbBrdr1DistLeft_D_Stat : 63|4@0+ (1,0) [0|15] "SED"  HCM_HS2
 SG_ AdbMde1_D_Rq : 10|2@0+ (1,0) [0|3] "SED"  GWM,HCM_HS2
 SG_ AdbIntns1_D_Rq : 12|2@0+ (1,0) [0|3] "SED"  GWM,HCM_HS2
 SG_ AdbBrdr1Up_An_Rq : 36|9@0+ (0.02,-8) [-8|2.18] "degrees"  GWM,HCM_HS2
 SG_ AdbBrdr1Right_An_Rq : 31|11@0+ (0.02,-20) [-20|20.9] "degrees"  GWM,HCM_HS2
 SG_ AdbBrdr1Low_An_Rq : 8|9@0+ (0.02,-8) [-8|2.18] "degrees"  GWM,HCM_HS2
 SG_ AdbBrdr1Left_An_Rq : 7|11@0+ (0.02,-20) [-20|20.9] "degrees"  HCM_HS2
 SG_ AdbBrdr1CritRigh_T_Stat : 43|4@0+ (100,0) [0|1500] "millisecond"  GWM,HCM_HS2
 SG_ AdbBrdr1CritLeft_T_Stat : 55|4@0+ (100,0) [0|1500] "millisecond"  GWM,HCM_HS2

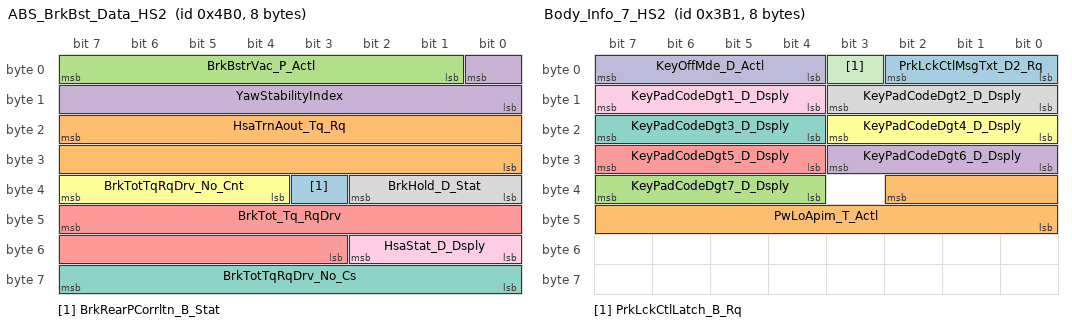
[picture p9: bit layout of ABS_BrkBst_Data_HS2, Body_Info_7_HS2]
BO_ 1200 ABS_BrkBst_Data_HS2: 8 GWM
 SG_ BrkRearPCorrltn_B_Stat : 35|1@0+ (1,0) [0|1] "SED" Vector__XXX
 SG_ HsaTrnAout_Tq_Rq : 23|16@0+ (4,-131072) [-131072|131060] "Nm" Vector__XXX
 SG_ BrkBstrVac_P_Actl : 7|7@0+ (8,0) [0|1008] "Millibar" Vector__XXX
 SG_ YawStabilityIndex : 0|9@0+ (1,-256) [-256|255] "%"  SASM,VDM_HS2
 SG_ BrkTot_Tq_RqDrv : 47|13@0+ (4,0) [0|32760] "Nm" Vector__XXX
 SG_ BrkTotTqRqDrv_No_Cnt : 39|4@0+ (1,0) [0|15] "unitless" Vector__XXX
 SG_ BrkTotTqRqDrv_No_Cs : 63|8@0+ (1,0) [0|255] "unitless" Vector__XXX
 SG_ BrkHold_D_Stat : 34|3@0+ (1,0) [0|7] "SED"  PAM_HS2
 SG_ HsaStat_D_Dsply : 50|3@0+ (1,0) [0|7] "SED" Vector__XXX

BO_ 1106 TrailerAid_Stat1: 8 RCM
 SG_ TrlrSnsId_No_Actl : 7|48@0+ (1,0) [0|281474976710653] "unitless"  GWM

BO_ 945 Body_Info_7_HS2: 8 GWM
 SG_ PrkLckCtlMsgTxt_D2_Rq : 2|3@0+ (1,0) [0|7] "SED"  GENERIC
 SG_ PwLoApim_T_Actl : 34|11@0+ (1,0) [0|2047] "minute"  GENERIC
 SG_ KeyPadCodeDgt7_D_Dsply : 39|4@0+ (1,0) [0|15] "SED"  GENERIC
 SG_ KeyPadCodeDgt6_D_Dsply : 27|4@0+ (1,0) [0|15] "SED"  GENERIC
 SG_ KeyPadCodeDgt5_D_Dsply : 31|4@0+ (1,0) [0|15] "SED"  GENERIC
 SG_ KeyPadCodeDgt4_D_Dsply : 19|4@0+ (1,0) [0|15] "SED"  GENERIC
 SG_ KeyPadCodeDgt3_D_Dsply : 23|4@0+ (1,0) [0|15] "SED"  GENERIC
 SG_ KeyPadCodeDgt2_D_Dsply : 11|4@0+ (1,0) [0|15] "SED"  GENERIC
 SG_ KeyPadCodeDgt1_D_Dsply : 15|4@0+ (1,0) [0|15] "SED"  GENERIC
 SG_ KeyOffMde_D_Actl : 7|4@0+ (1,0) [0|15] "SED"  VDM_HS2
 SG_ PrkLckCtlLatch_B_Rq : 3|1@0+ (1,0) [0|1] "SED"  GENERIC

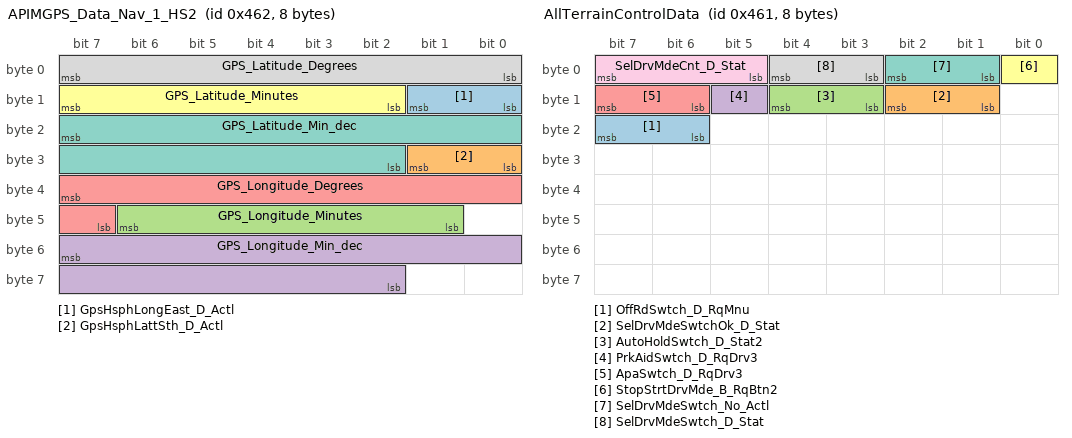
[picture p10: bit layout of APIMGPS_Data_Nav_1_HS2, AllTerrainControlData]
BO_ 1122 APIMGPS_Data_Nav_1_HS2: 8 GWM
 SG_ GpsHsphLongEast_D_Actl : 9|2@0+ (1,0) [0|3] "SED" Vector__XXX
 SG_ GpsHsphLattSth_D_Actl : 25|2@0+ (1,0) [0|3] "SED" Vector__XXX
 SG_ GPS_Longitude_Minutes : 46|6@0+ (1,0) [0|61] "Minutes" Vector__XXX
 SG_ GPS_Longitude_Min_dec : 55|14@0+ (0.0001,0) [0|1.6381] "Minutes" Vector__XXX
 SG_ GPS_Longitude_Degrees : 39|9@0+ (1,-179) [-179|330] "Degrees" Vector__XXX
 SG_ GPS_Latitude_Minutes : 15|6@0+ (1,0) [0|61] "Minutes" Vector__XXX
 SG_ GPS_Latitude_Min_dec : 23|14@0+ (0.0001,0) [0|1.6381] "Minutes" Vector__XXX
 SG_ GPS_Latitude_Degrees : 7|8@0+ (1,-89) [-89|164] "Degrees" Vector__XXX

BO_ 1080 GatewayData3_HS2: 8 GWM
 SG_ TrlrAidMde_D_Rq_UB : 56|1@0+ (1,0) [0|1] "SED" Vector__XXX
 SG_ TrlrAidMde_D_Rq : 58|2@0+ (1,0) [0|3] "SED" Vector__XXX
 SG_ Rba_D_Rq_UB : 59|1@0+ (1,0) [0|1] "SED" Vector__XXX
 SG_ Rba_D_Rq : 61|2@0+ (1,0) [0|3] "SED" Vector__XXX
 SG_ TrailCtlSwtch_B_Stat_UB : 62|1@0+ (1,0) [0|1] "SED" Vector__XXX
 SG_ TrailCtlSwtch_B_Stat : 63|1@0+ (1,0) [0|1] "SED" Vector__XXX
 SG_ TrailCtlPt_B_Falt_UB : 0|1@0+ (1,0) [0|1] "SED" Vector__XXX
 SG_ TrailCtlPt_B_Falt : 49|2@0+ (1,0) [0|3] "SED" Vector__XXX
 SG_ AutoTowActv_B_Stat_UB : 50|1@0+ (1,0) [0|1] "SED" Vector__XXX
 SG_ AutoTowActv_B_Stat : 51|1@0+ (1,0) [0|1] "SED" Vector__XXX
 SG_ DrLatchLckRr_B_Stat_UB : 44|1@0+ (1,0) [0|1] "SED"  GSM
 SG_ DrLatchLckRl_B_Stat_UB : 46|1@0+ (1,0) [0|1] "SED"  GSM
 SG_ DrLatchLckFr_B_Stat_UB : 32|1@0+ (1,0) [0|1] "SED"  GSM
 SG_ DrLatchLckFl_B_Stat_UB : 34|1@0+ (1,0) [0|1] "SED"  GSM
 SG_ DrLatchRr_B_Falt_UB : 40|1@0+ (1,0) [0|1] "SED"  GSM
 SG_ DrLatchRl_B_Falt_UB : 42|1@0+ (1,0) [0|1] "SED"  GSM
 SG_ DrLatchFr_B_Falt_UB : 36|1@0+ (1,0) [0|1] "SED"  GSM
 SG_ DrLatchFl_B_Falt_UB : 38|1@0+ (1,0) [0|1] "SED"  GSM
 SG_ DrLatchCntRr_No_Actl_UB : 24|1@0+ (1,0) [0|1] "SED"  GSM
 SG_ DrLatchCntRl_No_Actl_UB : 25|1@0+ (1,0) [0|1] "SED"  GSM
 SG_ DrLatchCntFr_No_Actl_UB : 26|1@0+ (1,0) [0|1] "SED"  GSM
 SG_ DrLatchCntFl_No_Actl_UB : 27|1@0+ (1,0) [0|1] "SED"  GSM
 SG_ DrLatchRr_B_Falt : 41|1@0+ (1,0) [0|1] "SED"  GSM
 SG_ DrLatchRl_B_Falt : 43|1@0+ (1,0) [0|1] "SED"  GSM
 SG_ DrLatchLckRr_B_Stat : 45|1@0+ (1,0) [0|1] "SED"  GSM
 SG_ DrLatchLckRl_B_Stat : 47|1@0+ (1,0) [0|1] "SED"  GSM
 SG_ DrLatchLckFr_B_Stat : 33|1@0+ (1,0) [0|1] "SED"  GSM
 SG_ DrLatchLckFl_B_Stat : 35|1@0+ (1,0) [0|1] "SED"  GSM
 SG_ DrLatchFr_B_Falt : 37|1@0+ (1,0) [0|1] "SED"  GSM
 SG_ DrLatchFl_B_Falt : 39|1@0+ (1,0) [0|1] "SED"  GSM
 SG_ DrLatchCntRr_No_Actl : 31|4@0+ (1,0) [0|15] "unitless"  GSM
 SG_ DrLatchCntRl_No_Actl : 19|4@0+ (1,0) [0|15] "unitless"  GSM
 SG_ DrLatchCntFr_No_Actl : 23|4@0+ (1,0) [0|15] "unitless"  GSM
 SG_ DrLatchCntFl_No_Actl : 55|4@0+ (1,0) [0|15] "unitless"  GSM
 SG_ TurnLghtSwtch_D_Stat2_UB : 1|1@0+ (1,0) [0|1] "SED"  RCM,PAM_HS2
 SG_ TurnLghtSwtch_D_Stat2 : 3|2@0+ (1,0) [0|3] "SED"  RCM,PAM_HS2
 SG_ CabnAmb_Te_Actl_UB : 4|1@0+ (1,0) [0|1] "SED"  SCCM
 SG_ CabnAmb_Te_Actl : 15|8@0+ (0.5,-57) [-57|70] "degreesC"  SCCM
 SG_ HeadLghtHiPrmsn_D_Stat_UB : 5|1@0+ (1,0) [0|1] "SED"  HCM_HS2,SCCM
 SG_ HeadLghtHiPrmsn_D_Stat : 7|2@0+ (1,0) [0|3] "SED"  HCM_HS2,SCCM

BO_ 1121 AllTerrainControlData: 8 ATCM_DMSM
 SG_ OffRdSwtch_D_RqMnu : 23|2@0+ (1,0) [0|3] "SED"  GWM
 SG_ SelDrvMdeSwtchOk_D_Stat : 10|2@0+ (1,0) [0|3] "SED"  GWM
 SG_ AutoHoldSwtch_D_Stat2 : 12|2@0+ (1,0) [0|3] "SED"  GWM
 SG_ PrkAidSwtch_D_RqDrv3 : 13|1@0+ (1,0) [0|1] "SED"  PAM_HS2,GWM
 SG_ ApaSwtch_D_RqDrv3 : 15|2@0+ (1,0) [0|3] "SED"  PAM_HS2,GWM
 SG_ StopStrtDrvMde_B_RqBtn2 : 0|1@0+ (1,0) [0|1] "SED"  GWM
 SG_ SelDrvMdeSwtch_No_Actl : 2|2@0+ (1,0) [0|3] "unitless"  GWM
 SG_ SelDrvMdeSwtch_D_Stat : 4|2@0+ (1,0) [0|3] "SED"  GWM
 SG_ SelDrvMdeCnt_D_Stat : 7|3@0+ (1,0) [0|7] "Counts"  GWM

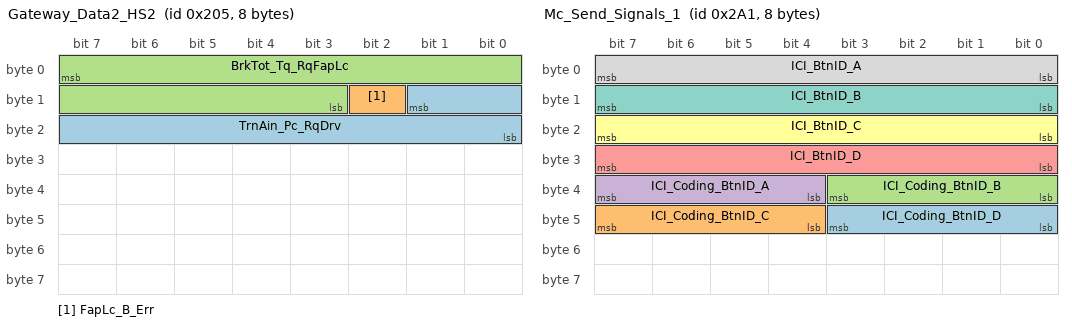
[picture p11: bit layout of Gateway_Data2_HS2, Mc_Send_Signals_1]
BO_ 517 Gateway_Data2_HS2: 8 GWM
 SG_ TrnAin_Pc_RqDrv : 9|10@0+ (0.1,0) [0|102.3] "percent" Vector__XXX
 SG_ FapLc_B_Err : 10|1@0+ (1,0) [0|1] "SED"  PAM_HS2
 SG_ BrkTot_Tq_RqFapLc : 7|13@0+ (4,0) [0|32764] "Nm" Vector__XXX

BO_ 1215 ElecHorizon_Data2_HS2: 8 GWM
 SG_ EhData2_No_Actl : 7|64@0+ (1,0) [0|1.84467440737096E+019] "unitless"  HCM_HS2

BO_ 1214 ElecHorizon_Data1_HS2: 8 GWM
 SG_ EhData1_No_Actl : 7|64@0+ (1,0) [0|1.84467440737096E+019] "unitless"  HCM_HS2

BO_ 673 Mc_Send_Signals_1: 8 SCCM
 SG_ ICI_Coding_BtnID_D : 43|4@0+ (1,0) [0|15] "SED"  GWM
 SG_ ICI_Coding_BtnID_C : 47|4@0+ (1,0) [0|15] "SED"  GWM
 SG_ ICI_Coding_BtnID_B : 35|4@0+ (1,0) [0|15] "SED"  GWM
 SG_ ICI_Coding_BtnID_A : 39|4@0+ (1,0) [0|15] "SED"  GWM
 SG_ ICI_BtnID_D : 31|8@0+ (1,0) [0|255] "unitless"  GWM
 SG_ ICI_BtnID_C : 23|8@0+ (1,0) [0|255] "unitless"  GWM
 SG_ ICI_BtnID_B : 15|8@0+ (1,0) [0|255] "unitless"  GWM
 SG_ ICI_BtnID_A : 7|8@0+ (1,0) [0|255] "unitless"  GWM

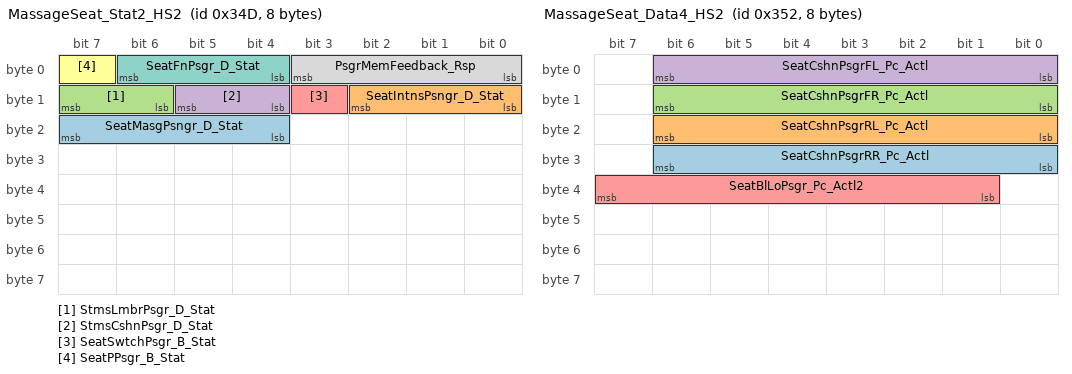
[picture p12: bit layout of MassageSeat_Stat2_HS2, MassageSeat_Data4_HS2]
BO_ 845 MassageSeat_Stat2_HS2: 8 GWM
 SG_ SeatMasgPsngr_D_Stat : 23|4@0+ (1,0) [0|15] "SED"  OCS,GENERIC
 SG_ SeatIntnsPsngr_D_Stat : 10|3@0+ (1,0) [0|7] "SED"  OCS,GENERIC
 SG_ StmsLmbrPsgr_D_Stat : 15|2@0+ (1,0) [0|3] "SED"  OCS
 SG_ StmsCshnPsgr_D_Stat : 13|2@0+ (1,0) [0|3] "SED"  OCS
 SG_ SeatSwtchPsgr_B_Stat : 11|1@0+ (1,0) [0|1] "SED"  OCS
 SG_ SeatPPsgr_B_Stat : 7|1@0+ (1,0) [0|1] "SED"  OCS
 SG_ SeatFnPsgr_D_Stat : 6|3@0+ (1,0) [0|7] "SED"  OCS
 SG_ PsgrMemFeedback_Rsp : 3|4@0+ (1,0) [0|15] "SED"  GENERIC

BO_ 850 MassageSeat_Data4_HS2: 8 GWM
 SG_ SeatCshnPsgrRR_Pc_Actl : 30|7@0+ (1,0) [0|126] "Percent"  OCS
 SG_ SeatCshnPsgrRL_Pc_Actl : 22|7@0+ (1,0) [0|126] "Percent"  OCS
 SG_ SeatCshnPsgrFR_Pc_Actl : 14|7@0+ (1,0) [0|126] "Percent"  OCS
 SG_ SeatCshnPsgrFL_Pc_Actl : 6|7@0+ (1,0) [0|126] "Percent"  OCS
 SG_ SeatBlLoPsgr_Pc_Actl2 : 39|7@0+ (1,0) [0|126] "Percent"  OCS

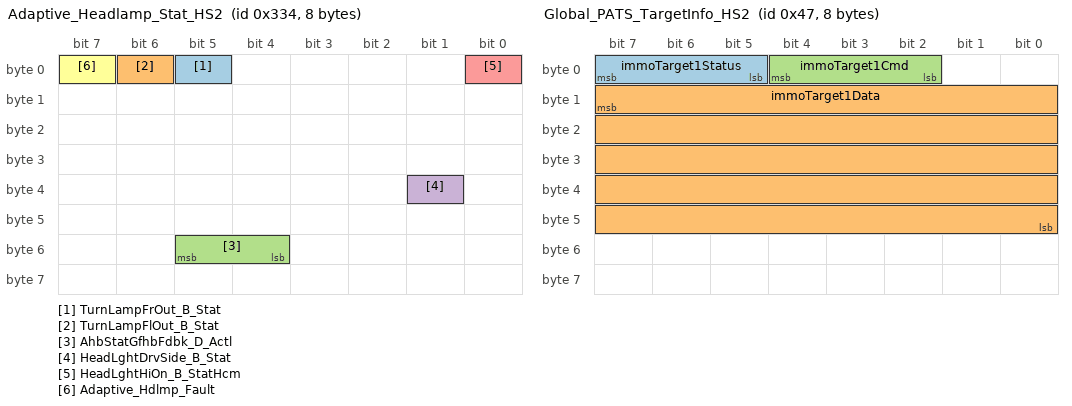
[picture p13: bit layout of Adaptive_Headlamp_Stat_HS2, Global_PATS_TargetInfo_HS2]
BO_ 820 Adaptive_Headlamp_Stat_HS2: 8 GWM
 SG_ TurnLampFrOut_B_Stat : 5|1@0+ (1,0) [0|1] "SED"  GWM
 SG_ TurnLampFlOut_B_Stat : 6|1@0+ (1,0) [0|1] "SED"  GWM
 SG_ AhbStatGfhbFdbk_D_Actl : 53|2@0+ (1,0) [0|3] "SED"  GWM,SCCM
 SG_ HeadLghtDrvSide_B_Stat : 33|1@0+ (1,0) [0|1] "SED"  GWM
 SG_ HeadLghtHiOn_B_StatHcm : 0|1@0+ (1,0) [0|1] "SED"  GWM,GENERIC
 SG_ Adaptive_Hdlmp_Fault : 7|1@0+ (1,0) [0|1] "SED"  GWM,GENERIC

BO_ 935 Side_Detect_R_Stat_HS2: 8 GWM
 SG_ SodInnrRight_D_Stat : 20|2@0+ (1,0) [0|3] "SED"  GENERIC
 SG_ RbaCtaRight_D_Stat : 55|3@0+ (1,0) [0|7] "SED" Vector__XXX
 SG_ LcwaRight_D_Stat : 52|3@0+ (1,0) [0|7] "SED" Vector__XXX
 SG_ LcwaDetctRight2_B_Stat : 40|1@0+ (1,0) [0|1] "SED" Vector__XXX
 SG_ LcwaDetctRight1_B_Stat : 41|1@0+ (1,0) [0|1] "SED" Vector__XXX
 SG_ CtaInnrRight_D_Stat : 27|2@0+ (1,0) [0|3] "SED"  GENERIC
 SG_ CtaAlrtRight2_D_Stat : 30|3@0+ (1,0) [0|7] "SED"  GENERIC
 SG_ BttRight_D_Stat : 45|3@0+ (1,0) [0|7] "SED"  GENERIC
 SG_ BttRight_D_RqDrv : 47|2@0+ (1,0) [0|3] "SED"  GENERIC
 SG_ CtaBrkRightMsgTxt_B_Rq : 42|1@0+ (1,0) [0|1] "SED"  GENERIC
 SG_ CtaRightBrkEnbl_B_Rq : 31|1@0+ (1,0) [0|1] "SED" Vector__XXX
 SG_ Side_Detect_R_Illum : 39|8@0+ (1,0) [0|255] "Percent"  GENERIC
 SG_ CtaSnsRight_D_Stat : 25|2@0+ (1,0) [0|3] "SED"  GENERIC
 SG_ CtaAlrtRight_D_Stat : 8|1@0+ (1,0) [0|1] "SED"  GENERIC
 SG_ CtaRight_D_Stat : 18|3@0+ (1,0) [0|7] "SED"  PAM_HS2
 SG_ SodRight_D_Stat : 15|3@0+ (1,0) [0|7] "SED"  GENERIC
 SG_ SodSnsRight_D_Stat : 12|2@0+ (1,0) [0|3] "SED"  PAM_HS2
 SG_ SodAlrtRight_D_Stat : 10|2@0+ (1,0) [0|3] "SED"  GENERIC
 SG_ SodDetctRight_D_Stat : 23|3@0+ (1,0) [0|7] "SED" Vector__XXX
 SG_ SodWarnRight_Prd_Rq : 6|7@0+ (1,0) [0|127] "millisecond"  GENERIC
 SG_ CtaRightBrkDecel_B_Rq : 7|1@0+ (1,0) [0|1] "SED" Vector__XXX

BO_ 934 Side_Detect_L_Stat_HS2: 8 GWM
 SG_ SodInnrLeft_D_Stat : 20|2@0+ (1,0) [0|3] "SED"  GENERIC
 SG_ RbaCtaLeft_D_Stat : 55|3@0+ (1,0) [0|7] "SED" Vector__XXX
 SG_ LcwaLeft_D_Stat : 52|3@0+ (1,0) [0|7] "SED" Vector__XXX
 SG_ LcwaDetctLeft2_B_Stat : 40|1@0+ (1,0) [0|1] "SED" Vector__XXX
 SG_ LcwaDetctLeft1_B_Stat : 41|1@0+ (1,0) [0|1] "SED" Vector__XXX
 SG_ CtaInnrLeft_D_Stat : 27|2@0+ (1,0) [0|3] "SED"  GENERIC
 SG_ CtaAlrtLeft2_D_Stat : 30|3@0+ (1,0) [0|7] "SED"  GENERIC
 SG_ BttLeft_D_Stat : 45|3@0+ (1,0) [0|7] "SED"  GENERIC
 SG_ BttLeft_D_RqDrv : 47|2@0+ (1,0) [0|3] "SED"  GENERIC
 SG_ CtaBrkLeftMsgTxt_B_Rq : 42|1@0+ (1,0) [0|1] "SED"  GENERIC
 SG_ CtaLeftBrkDecel_B_Rq : 7|1@0+ (1,0) [0|1] "SED" Vector__XXX
 SG_ CtaLeftBrkEnbl_B_Rq : 31|1@0+ (1,0) [0|1] "SED" Vector__XXX
 SG_ Side_Detect_L_Illum : 39|8@0+ (1,0) [0|255] "Percent"  GENERIC
 SG_ CtaSnsLeft_D_Stat : 25|2@0+ (1,0) [0|3] "SED"  GENERIC
 SG_ SodDetctLeft_D_Stat : 23|3@0+ (1,0) [0|7] "SED" Vector__XXX
 SG_ CtaLeft_D_Stat : 18|3@0+ (1,0) [0|7] "SED"  PAM_HS2
 SG_ CtaAlrtLeft_D_Stat : 8|1@0+ (1,0) [0|1] "SED"  GENERIC
 SG_ SodLeft_D_Stat : 15|3@0+ (1,0) [0|7] "SED"  GENERIC
 SG_ SodSnsLeft_D_Stat : 12|2@0+ (1,0) [0|3] "SED"  PAM_HS2
 SG_ SodAlrtLeft_D_Stat : 10|2@0+ (1,0) [0|3] "SED"  GENERIC
 SG_ SodWarnLeft_Prd_Rq : 6|7@0+ (1,0) [0|127] "millisecond"  GENERIC

BO_ 1073 BodyEngGateway_2_HS2: 8 GWM
 SG_ CamraFrntBttn_D_Stat : 48|1@0+ (1,0) [0|1] "SED" Vector__XXX
 SG_ CamraFrntBttn_D_Stat_UB : 60|1@0+ (1,0) [0|1] "SED" Vector__XXX
 SG_ BrkDrvMde_D_Rq_UB : 49|1@0+ (1,0) [0|1] "SED" Vector__XXX
 SG_ BrkDrvMde_D_Rq : 63|3@0+ (1,0) [0|7] "SED" Vector__XXX
 SG_ SteEffort_D_Rq : 52|3@0+ (1,0) [0|7] "SED" Vector__XXX
 SG_ SteEffort_D_Rq_UB : 40|1@0+ (1,0) [0|1] "SED" Vector__XXX
 SG_ AutoHoldSwtch_D_Stat_UB : 57|1@0+ (1,0) [0|1] "SED" Vector__XXX
 SG_ AutoHoldSwtch_D_Stat : 59|2@0+ (1,0) [0|3] "SED" Vector__XXX
 SG_ HMI_HMIMode_St_UB : 41|1@0+ (1,0) [0|1] "SED"  SASM,SCCM
 SG_ HMI_HMIMode_St : 55|3@0+ (1,0) [0|7] "SED"  SASM,SCCM
 SG_ Veh_Lock_Requestor_UB : 47|1@0+ (1,0) [0|1] "SED"  GSM
 SG_ Veh_Lock_EvNum_UB : 32|1@0+ (1,0) [0|1] "SED"  SUMA_RLM,GSM
 SG_ Veh_Lock_Sub_Id_UB : 33|1@0+ (1,0) [0|1] "SED" Vector__XXX
 SG_ Tire_Press_System_Stat_UB : 34|1@0+ (1,0) [0|1] "SED" Vector__XXX
 SG_ Veh_Lock_Status_UB : 8|1@0+ (1,0) [0|1] "SED"  GSM
 SG_ Veh_Lock_Sub_Id : 19|4@0+ (1,0) [0|15] "SED" Vector__XXX
 SG_ Veh_Lock_Status : 10|2@0+ (1,0) [0|3] "SED"  GSM
 SG_ Veh_Lock_Requestor : 39|5@0+ (1,0) [0|31] "SED"  GSM
 SG_ Veh_Lock_EvNum : 31|8@0+ (1,0) [0|255] "unitless"  SUMA_RLM,GSM
 SG_ Tire_Press_System_Stat : 23|4@0+ (1,0) [0|15] "SED" Vector__XXX
 SG_ DISPLAY_SPEED_OFFSET_UB : 0|1@0+ (1,0) [0|1] "SED" Vector__XXX
 SG_ DISPLAY_SPEED_OFFSET : 3|3@0+ (0.5,0) [0|3.5] "kph" Vector__XXX
 SG_ DISPLAY_SPEED_SCALING_UB : 11|1@0+ (1,0) [0|1] "SED" Vector__XXX
 SG_ DISPLAY_SPEED_SCALING : 15|4@0+ (0.5,100) [100|107.5] "%" Vector__XXX
 SG_ Foh_D_Stat : 7|3@0+ (1,0) [0|7] "SED"  SASM,SCCM
 SG_ Foh_D_Stat_UB : 4|1@0+ (1,0) [0|1] "SED"  SASM,SCCM
 SG_ SteWhlHeat_D_Rq_UB : 42|1@0+ (1,0) [0|1] "SED"  SCCM,SASM
 SG_ SteWhlHeat_D_Rq : 46|4@0+ (1,0) [0|15] "SED"  SCCM,SASM

BO_ 1876 TesterPhysicalReqTCU_TBS: 8 TSTR
 SG_ TesterPhysicalReqTCU : 7|64@0+ (1,0) [0|1.84467E+019] "unitless" Vector__XXX

BO_ 71 Global_PATS_TargetInfo_HS2: 8 GWM
 SG_ immoTarget1Status : 7|3@0+ (1,0) [0|7] "SED" Vector__XXX
 SG_ immoTarget1Data : 15|40@0+ (1,0) [0|1099511627775] "Encrypted" Vector__XXX
 SG_ immoTarget1Cmd : 4|3@0+ (1,0) [0|7] "SED" Vector__XXX

BO_ 973 Traffic_RecognitionData: 8 Vector__XXX
 SG_ PersCtaSplitView_D_Stat : 12|2@0+ (1,0) [0|3] "SED"  GWM
 SG_ LaSysOffStat_D_Dsply : 58|2@0+ (1,0) [0|3] "SED"  GWM
 SG_ TsrVl2PrmntMsgTxt_D_Rq : 60|2@0+ (1,0) [0|3] "SED"  GWM
 SG_ TsrVl1PrmntMsgTxt_D_Rq : 41|2@0+ (1,0) [0|3] "SED"  GWM
 SG_ TsrVl2RstrcMsgTxt2_D_Rq : 63|3@0+ (1,0) [0|7] "SED"  GWM
 SG_ TsrVl1RstrcMsgTxt2_D_Rq : 51|3@0+ (1,0) [0|7] "SED"  GWM
 SG_ TsrOvtkMsgTxt2_D_Rq : 55|4@0+ (1,0) [0|15] "SED"  GWM
 SG_ WwaWarn_B_Rq : 48|1@0+ (1,0) [0|1] "SED"  GWM
 SG_ TsrVlUnitMsgTxt_D_Rq : 43|2@0+ (1,0) [0|3] "SED"  GWM
 SG_ TsrVLim2MsgTxt_D_Rq : 39|8@0+ (1,0) [0|255] "SED"  GWM
 SG_ TsrVLim1MsgTxt_D_Rq : 31|8@0+ (1,0) [0|255] "SED"  GWM
 SG_ TsrVl2StatMsgTxt_D_Rq : 47|2@0+ (1,0) [0|3] "SED"  GWM
 SG_ TsrVl2RstrcMsgTxt_D_Rq : 17|2@0+ (1,0) [0|3] "SED"  GWM
 SG_ TsrVl1StatMsgTxt_D_Rq : 21|2@0+ (1,0) [0|3] "SED"  GWM
 SG_ TsrVl1RstrcMsgTxt_D_Rq : 23|2@0+ (1,0) [0|3] "SED"  GWM
 SG_ TsrStatMsgTxt_D_Rq : 10|3@0+ (1,0) [0|7] "SED"  GWM
 SG_ TsrOvtkStatMsgTxt_D_Rq : 1|2@0+ (1,0) [0|3] "SED"  GWM
 SG_ TsrOvtkMsgTxt_D_Rq : 15|3@0+ (1,0) [0|7] "SED"  GWM
 SG_ TsrOswWarnMsgTxt_D_Rq : 3|2@0+ (1,0) [0|3] "SED"  GWM
 SG_ TsrMsgTxt_D_Rq : 7|4@0+ (1,0) [0|15] "SED"  GWM

BO_ 837 VeyDynamics_Data_HS2: 8 VDM_HS2
 SG_ SuspVLimBRq_No_Cs : 39|8@0+ (1,0) [0|255] "Unitless"  GENERIC
 SG_ SuspVLimBRq_No_Cnt : 47|4@0+ (1,0) [0|15] "Unitless"  GENERIC
 SG_ VdmSustnActv_B_Rq : 12|1@0+ (1,0) [0|1] "SED"  GWM
 SG_ VehCurb_M_Actl : 43|10@0+ (5,0) [0|5105] "kilogram"  GWM
 SG_ Ccd_B_Falt : 24|1@0+ (1,0) [0|1] "SED"  GWM
 SG_ SuspVLim_B_Rq : 18|1@0+ (1,0) [0|1] "SED"  GWM
 SG_ SelDrvMdeSusp_D_Stat : 20|2@0+ (1,0) [0|3] "SED" Vector__XXX
 SG_ AdptDrvMdePt_D_Rq : 23|3@0+ (1,0) [0|7] "SED" Vector__XXX
 SG_ AdptDrvMdeChassis_D_Rq : 10|3@0+ (1,0) [0|7] "SED" Vector__XXX
 SG_ AirSprngRateRr_D_Rq : 27|2@0+ (1,0) [0|3] "SED"  SUMA_RLM
 SG_ AirSprngRateRl_D_Rq : 29|2@0+ (1,0) [0|3] "SED"  SUMA_RLM
 SG_ SuspType_B_Stat : 25|1@0+ (1,0) [0|1] "SED"  GWM
 SG_ AirSprngRateFr_D_Rq : 31|2@0+ (1,0) [0|3] "SED"  SUMA_RLM
 SG_ AirSprngRateFl_D_Rq : 17|2@0+ (1,0) [0|3] "SED"  SUMA_RLM
 SG_ VehGvwr_M_Actl : 49|10@0+ (10,0) [0|10210] "kilogram"  GWM
 SG_ AirSusp_D_Stat : 1|2@0+ (1,0) [0|3] "SED"  GWM
 SG_ AirSuspMsgTxt_D_Rq : 3|2@0+ (1,0) [0|3] "SED"  GWM
 SG_ SuspDrvMde_D_Stat : 15|3@0+ (1,0) [0|7] "SED"  GWM
 SG_ CcdMsgTxt_D_RqDsply : 7|4@0+ (1,0) [0|15] "SED"  SASM,GWM

CM_ BO_ 1124 "HS3 APIM Sync Gen3 Tx 0x464.  FrameGateway to 0x467 on HS1, HS2, HS3 and MS1.";
CM_ SG_ 942 PrkAidRdiusRight_L_Dsply "MSGDCR 679, set all signals to OnChange";
CM_ SG_ 942 PrkAidRdiusLeft_L_Dsply "MSGDCR 679, set all signals to OnChange";
CM_ SG_ 942 PrkAidDrvDir_D_Stat "MSGDCR 679, set all signals to OnChange";
CM_ SG_ 138 SteWhlRelCalib_An_Sns "Signal is not transmitted on vehicles where PSCM is transmitting the message that contains this signal.
Signal data set to 0x0 for ABS only vehicle option content";
CM_ SG_ 133 SteWhlOSRelInit2An_Est "Legacy signal not supported, reserving bit location for commodity IPMA dbc file.  No valid data. ";
CM_ SG_ 133 SteWhlAn_No_Cs "Legacy signal not supported, reserving bit location for commodity IPMA dbc file.  No valid data. ";
CM_ SG_ 133 SteWhlAn_No_Cnt "Legacy signal not supported, reserving bit location for commodity IPMA dbc file.  No valid data. ";
CM_ SG_ 133 SteWhlRelCalib_An_Sns "Signal is not transmitted on vehicles where PSCM is transmitting the message that contains this signal.
Signal data set to 0x0 for ABS only vehicle option content";
CM_ SG_ 133 SteWhlRelInit2_An_Sns "Legacy signal not supported, reserving bit location for commodity IPMA dbc file.  No valid data. ";
CM_ SG_ 1200 BrkTot_Tq_RqDrv "DCR 1836 to update Tx from GWM to EP100ms rejected due MPS6 TCM requires BrkTot_Tq_RqDrv at 20ms (bshu1).";
CM_ BO_ 1106 " new RCM Serial Trailer Aid (TrailerAid_Stat1) 48 bits";
CM_ BO_ 1122 "HS3 APIM Sync Gen3 Tx 0x462.  FrameGateway to 0x465 on HS1, HS2, HS3 and MS1.";
CM_ SG_ 1080 DrLatchCntRr_No_Actl "Rolling counts indicate fresh data (DrLatchCntxx) are updated each time new data is sent from a latch to BCM thru the GW. UBs not required.";
CM_ SG_ 1080 DrLatchCntRl_No_Actl "Rolling counts indicate fresh data (DrLatchCntxx) are updated each time new data is sent from a latch to BCM thru the GW. UBs not required.";
CM_ SG_ 1080 DrLatchCntFr_No_Actl "Rolling counts indicate fresh data (DrLatchCntxx) are updated each time new data is sent from a latch to BCM thru the GW. UBs not required.";
CM_ SG_ 1080 DrLatchCntFl_No_Actl "Rolling counts indicate fresh data (DrLatchCntxx) are updated each time new data is sent from a latch to BCM thru the GW. UBs not required.";
CM_ BO_ 673 "Do not use this Frame for other Cluster Interaction";
CM_ SG_ 673 ICI_Coding_BtnID_D "Object InputControlInterface ICI ButtonCoding_D
(Parameter2)";
CM_ SG_ 673 ICI_Coding_BtnID_C "Object InputControlInterface ICI ButtonCoding_C
(Parameter2)";
CM_ SG_ 673 ICI_Coding_BtnID_B "Object InputControlInterface ICI ButtonCoding_B
(Parameter2)";
CM_ SG_ 673 ICI_Coding_BtnID_A "Object InputControlInterface ICI ButtonCoding_A
(Parameter2)";
CM_ SG_ 673 ICI_BtnID_D "Object InputControlInterface ICI ButtonID_D
(Parameter1)
for detailed Information refer to ICI Reference document";
CM_ SG_ 673 ICI_BtnID_C "Object InputControlInterface ICI ButtonID_C
(Parameter1)
for detailed Information refer to ICI Reference document";
CM_ SG_ 673 ICI_BtnID_B "Object InputControlInterface ICI ButtonID_B
(Parameter1)
for detailed Information refer to ICI Reference document";
CM_ SG_ 673 ICI_BtnID_A "Object InputControlInterface ICI ButtonID_A
(Parameter1)
for detailed Information refer to ICI Reference document";
CM_ SG_ 1073 HMI_HMIMode_St "Object ACU System Master.HMIMode
OR
Object NAV System Master.HMIMode

Refer Method HMIAudioMode in the SPSS";
CM_ SG_ 1073 Foh_D_Stat "Signal not transmitted on vehicles that do not have the Fuel operated heater feature.";
CM_ BO_ 71 "Provide target function info. to control function of PATS";
BA_DEF_ BO_  "FrameRouting" STRING ;
BA_DEF_ BO_  "FrameGatewayNetwork" STRING ;
BA_DEF_ BO_  "NetworkInitialization" ENUM  "No","Yes";
BA_DEF_ BO_  "FrameGatewayId" HEX 0 1407;
BA_DEF_ BO_  "EventRateOfChange" INT 10 10000;
BA_DEF_ BO_  "GenMsgNrOfRepetition" INT 0 100;
BA_DEF_ BO_  "GenMsgDelayTime" INT 0 1000;
BA_DEF_ BO_  "GenMsgCycleTime" INT 0 100000;
BA_DEF_ BO_  "GenMsgSendType" ENUM  "FixedPeriodic","Event","EnabledPeriodic","NotUsed","NotUsed","EventPeriodic","NotUsed","NotUsed","NoMsgSendType";
BA_DEF_ SG_  "U_CD764_MY2022_Tx" ENUM  "No","Yes";
BA_DEF_ SG_  "U_U55X_MY2022_Tx" ENUM  "No","Yes";
BA_DEF_ SG_  "U_CD542_MY2021_Tx" ENUM  "No","Yes";
BA_DEF_ SG_  "ECGUsedTxSignal" ENUM  "No","Yes";
BA_DEF_ SG_  "U_T6_MCA_MY2020_Tx" ENUM  "No","Yes";
BA_DEF_ SG_  "U_P702_MY2021_Tx" ENUM  "No","Yes";
BA_DEF_ SG_  "U_CX727_MY2021_Tx" ENUM  "No","Yes";
BA_DEF_ SG_  "U_CD764_MY2022_Rx" ENUM  "No","Yes";
BA_DEF_ SG_  "U_U55X_MY2022_Rx" ENUM  "No","Yes";
BA_DEF_ SG_  "U_CD542_MY2021_Rx" ENUM  "No","Yes";
BA_DEF_ SG_  "ECGUsedRxSignal" ENUM  "No","Yes";
BA_DEF_ SG_  "U_T6_MCA_MY2020_Rx" ENUM  "No","Yes";
BA_DEF_ SG_  "U_P702_MY2021_Rx" ENUM  "No","Yes";
BA_DEF_ SG_  "U_CX727_MY2021_Rx" ENUM  "No","Yes";
BA_DEF_ SG_  "GenSigStartValue" HEX 0 268435455;
BA_DEF_ SG_  "MetaData" ENUM  "No","Yes";
BA_DEF_ SG_  "ContentDependant" ENUM  "No","Yes";
BA_DEF_ SG_  "GenSigStartValueInteger" INT 0 1000000000;
BA_DEF_ SG_  "UsedOnPgmDBC" ENUM  "No","Yes";
BA_DEF_ SG_  "WakeupSignal" ENUM  "No","Yes";
BA_DEF_ SG_  "GenSigInactiveValue" INT 0 100000;
BA_DEF_ SG_  "GenSigSendType" ENUM  "Cyclic","OnWrite","vector_leerstring","OnChange","vector_leerstring","IfActive","vector_leerstring","NoSigSendType";
BA_DEF_ BO_  "OvtpPushApplication" ENUM  "FALSE","TRUE";
BA_DEF_ BO_  "SCP_FreshnessValueLength" INT 0 512;
BA_DEF_ BO_  "SCP_FreshnessValueTxLength" INT 0 512;
BA_DEF_ BO_  "SCP_AuthInfoTxLength" INT 0 512;
BA_DEF_ BO_  "GenMsgRoutingTimeoutTime" INT 0 5000;
BA_DEF_ BO_  "MessageGateway" ENUM  "No","Yes";
BA_DEF_ BO_  "NmAsrMessage" ENUM  "No","Yes";
BA_DEF_ BO_  "TpApplType" STRING ;
BA_DEF_ BO_  "DiagState" ENUM  "No","Yes";
BA_DEF_ BO_  "TpTxIndex" INT 0 536870911;
BA_DEF_ BO_  "DiagRequest" ENUM  "No","Yes";
BA_DEF_ BO_  "DiagResponse" ENUM  "No","Yes";
BA_DEF_ BO_  "GenMsgILSupport" ENUM  "No","Yes";
BA_DEF_DEF_  "FrameRouting" "";
BA_DEF_DEF_  "FrameGatewayNetwork" "NONE";
BA_DEF_DEF_  "NetworkInitialization" "Yes";
BA_DEF_DEF_  "FrameGatewayId" 0;
BA_DEF_DEF_  "EventRateOfChange" 10000;
BA_DEF_DEF_  "GenMsgNrOfRepetition" 1;
BA_DEF_DEF_  "GenMsgDelayTime" 20;
BA_DEF_DEF_  "GenMsgCycleTime" 0;
BA_DEF_DEF_  "GenMsgSendType" "NoMsgSendType";
BA_DEF_DEF_  "U_CD764_MY2022_Tx" "No";
BA_DEF_DEF_  "U_U55X_MY2022_Tx" "No";
BA_DEF_DEF_  "U_CD542_MY2021_Tx" "No";
BA_DEF_DEF_  "ECGUsedTxSignal" "No";
BA_DEF_DEF_  "U_T6_MCA_MY2020_Tx" "No";
BA_DEF_DEF_  "U_P702_MY2021_Tx" "No";
BA_DEF_DEF_  "U_CX727_MY2021_Tx" "No";
BA_DEF_DEF_  "U_CD764_MY2022_Rx" "No";
BA_DEF_DEF_  "U_U55X_MY2022_Rx" "No";
BA_DEF_DEF_  "U_CD542_MY2021_Rx" "No";
BA_DEF_DEF_  "ECGUsedRxSignal" "No";
BA_DEF_DEF_  "U_T6_MCA_MY2020_Rx" "No";
BA_DEF_DEF_  "U_P702_MY2021_Rx" "No";
BA_DEF_DEF_  "U_CX727_MY2021_Rx" "No";
BA_DEF_DEF_  "GenSigStartValue" 0;
BA_DEF_DEF_  "MetaData" "No";
BA_DEF_DEF_  "ContentDependant" "No";
BA_DEF_DEF_  "GenSigStartValueInteger" 0;
BA_DEF_DEF_  "UsedOnPgmDBC" "Yes";
BA_DEF_DEF_  "WakeupSignal" "No";
BA_DEF_DEF_  "GenSigInactiveValue" 0;
BA_DEF_DEF_  "GenSigSendType" "NoSigSendType";
BA_DEF_DEF_  "OvtpPushApplication" "FALSE";
BA_DEF_DEF_  "SCP_FreshnessValueLength" 64;
BA_DEF_DEF_  "SCP_FreshnessValueTxLength" 11;
BA_DEF_DEF_  "SCP_AuthInfoTxLength" 53;
BA_DEF_DEF_  "GenMsgRoutingTimeoutTime" 0;
BA_DEF_DEF_  "MessageGateway" "No";
BA_DEF_DEF_  "NmAsrMessage" "No";
BA_DEF_DEF_  "TpApplType" "";
BA_DEF_DEF_  "DiagState" "No";
BA_DEF_DEF_  "TpTxIndex" 0;
BA_DEF_DEF_  "DiagRequest" "No";
BA_DEF_DEF_  "DiagResponse" "No";
BA_DEF_DEF_  "GenMsgILSupport" "Yes";
BA_ "FrameRouting" BO_ 1114 "HS3_CAN,0x45A;";
BA_ "FrameGatewayNetwork" BO_ 1114 "HS3_CAN";
BA_ "FrameGatewayId" BO_ 1114 1114;
BA_ "GenMsgCycleTime" BO_ 939 200;
BA_ "GenMsgSendType" BO_ 939 5;
BA_ "GenMsgCycleTime" BO_ 938 200;
BA_ "GenMsgSendType" BO_ 938 5;
BA_ "GenMsgCycleTime" BO_ 863 1000;
BA_ "GenMsgSendType" BO_ 863 5;
BA_ "NetworkInitialization" BO_ 1472 0;
BA_ "GenMsgCycleTime" BO_ 1472 1000;
BA_ "GenMsgSendType" BO_ 1472 0;
BA_ "NmAsrMessage" BO_ 1472 1;
BA_ "GenMsgILSupport" BO_ 1472 0;
BA_ "NetworkInitialization" BO_ 2612030680 0;
BA_ "GenMsgDelayTime" BO_ 2612030680 0;
BA_ "GenMsgSendType" BO_ 2612030680 1;
BA_ "OvtpPushApplication" BO_ 2612030680 1;
BA_ "TpTxIndex" BO_ 2612030680 464547032;
BA_ "FrameRouting" BO_ 981 "FD1_CAN,0x3D5;";
BA_ "FrameGatewayNetwork" BO_ 981 "FD1_CAN";
BA_ "FrameGatewayId" BO_ 981 981;
BA_ "NetworkInitialization" BO_ 2611175451 0;
BA_ "TpTxIndex" BO_ 2611175451 463498456;
BA_ "FrameRouting" BO_ 1124 "HS3_CAN,0x464;";
BA_ "FrameGatewayNetwork" BO_ 1124 "HS3_CAN";
BA_ "FrameGatewayId" BO_ 1124 1124;
BA_ "NetworkInitialization" BO_ 1844 0;
BA_ "GenMsgDelayTime" BO_ 1844 0;
BA_ "GenMsgSendType" BO_ 1844 1;
BA_ "DiagRequest" BO_ 1844 1;
BA_ "GenMsgILSupport" BO_ 1844 0;
BA_ "NetworkInitialization" BO_ 1852 0;
BA_ "GenMsgDelayTime" BO_ 1852 0;
BA_ "GenMsgSendType" BO_ 1852 1;
BA_ "DiagResponse" BO_ 1852 1;
BA_ "GenMsgILSupport" BO_ 1852 0;
BA_ "FrameRouting" BO_ 989 "FD1_CAN,0x3DD;HS2_CAN,0x3DD";
BA_ "GenMsgCycleTime" BO_ 989 1000;
BA_ "GenMsgSendType" BO_ 989 5;
BA_ "NetworkInitialization" BO_ 2612002008 0;
BA_ "GenMsgDelayTime" BO_ 2612002008 0;
BA_ "GenMsgSendType" BO_ 2612002008 1;
BA_ "TpTxIndex" BO_ 2612002008 464518360;
BA_ "NetworkInitialization" BO_ 2610953432 0;
BA_ "GenMsgDelayTime" BO_ 2610953432 0;
BA_ "GenMsgSendType" BO_ 2610953432 1;
BA_ "TpTxIndex" BO_ 2610953432 463469784;
BA_ "NetworkInitialization" BO_ 2609933528 0;
BA_ "GenMsgDelayTime" BO_ 2609933528 0;
BA_ "GenMsgSendType" BO_ 2609933528 1;
BA_ "TpTxIndex" BO_ 2609933528 462449880;
BA_ "NetworkInitialization" BO_ 2610126875 0;
BA_ "GenMsgDelayTime" BO_ 2610126875 0;
BA_ "GenMsgSendType" BO_ 2610126875 1;
BA_ "TpTxIndex" BO_ 2610126875 462449880;
BA_ "FrameRouting" BO_ 1105 "FD1_CAN,0x451;";
BA_ "FrameGatewayNetwork" BO_ 1105 "FD1_CAN";
BA_ "FrameGatewayId" BO_ 1105 1105;
BA_ "FrameRouting" BO_ 1056 "FD1_CAN,0x420;";
BA_ "FrameGatewayNetwork" BO_ 1056 "FD1_CAN";
BA_ "FrameGatewayId" BO_ 1056 1056;
BA_ "FrameRouting" BO_ 1047 "FD1_CAN,0x417;";
BA_ "FrameGatewayNetwork" BO_ 1047 "FD1_CAN";
BA_ "FrameGatewayId" BO_ 1047 1047;
BA_ "NetworkInitialization" BO_ 1892 0;
BA_ "GenMsgDelayTime" BO_ 1892 0;
BA_ "GenMsgSendType" BO_ 1892 1;
BA_ "DiagRequest" BO_ 1892 1;
BA_ "GenMsgILSupport" BO_ 1892 0;
BA_ "NetworkInitialization" BO_ 1969 0;
BA_ "GenMsgDelayTime" BO_ 1969 0;
BA_ "GenMsgSendType" BO_ 1969 1;
BA_ "DiagRequest" BO_ 1969 1;
BA_ "GenMsgILSupport" BO_ 1969 0;
BA_ "NetworkInitialization" BO_ 1798 0;
BA_ "GenMsgDelayTime" BO_ 1798 0;
BA_ "GenMsgSendType" BO_ 1798 1;
BA_ "DiagRequest" BO_ 1798 1;
BA_ "GenMsgILSupport" BO_ 1798 0;
BA_ "DiagResponse" BO_ 1900 1;
BA_ "GenMsgILSupport" BO_ 1900 0;
BA_ "DiagResponse" BO_ 1806 1;
BA_ "GenMsgILSupport" BO_ 1806 0;
BA_ "FrameRouting" BO_ 962 "FD1_CAN,0x3C2;";
BA_ "FrameGatewayNetwork" BO_ 962 "FD1_CAN";
BA_ "FrameGatewayId" BO_ 962 962;
BA_ "FrameRouting" BO_ 961 "FD1_CAN,0x3C1;";
BA_ "FrameGatewayNetwork" BO_ 961 "FD1_CAN";
BA_ "FrameGatewayId" BO_ 961 961;
BA_ "NetworkInitialization" BO_ 1854 0;
BA_ "GenMsgDelayTime" BO_ 1854 0;
BA_ "GenMsgSendType" BO_ 1854 1;
BA_ "DiagResponse" BO_ 1854 1;
BA_ "GenMsgILSupport" BO_ 1854 0;
BA_ "GenMsgCycleTime" BO_ 942 1000;
BA_ "GenMsgSendType" BO_ 942 5;
BA_ "FrameRouting" BO_ 1049 "HS3_CAN,0x419;";
BA_ "FrameGatewayNetwork" BO_ 1049 "HS3_CAN";
BA_ "FrameGatewayId" BO_ 1049 1049;
BA_ "NetworkInitialization" BO_ 1487 0;
BA_ "GenMsgCycleTime" BO_ 1487 1000;
BA_ "GenMsgSendType" BO_ 1487 0;
BA_ "NmAsrMessage" BO_ 1487 1;
BA_ "GenMsgILSupport" BO_ 1487 0;
BA_ "GenMsgCycleTime" BO_ 1120 1000;
BA_ "GenMsgSendType" BO_ 1120 5;
BA_ "NetworkInitialization" BO_ 1997 0;
BA_ "GenMsgSendType" BO_ 1997 1;
BA_ "DiagResponse" BO_ 1997 1;
BA_ "GenMsgILSupport" BO_ 1997 0;
BA_ "NetworkInitialization" BO_ 1989 0;
BA_ "GenMsgDelayTime" BO_ 1989 0;
BA_ "GenMsgSendType" BO_ 1989 1;
BA_ "DiagRequest" BO_ 1989 1;
BA_ "GenMsgILSupport" BO_ 1989 0;
BA_ "FrameRouting" BO_ 1052 "HS1_CAN,0x41C;";
BA_ "FrameGatewayNetwork" BO_ 1052 "HS1_CAN";
BA_ "FrameGatewayId" BO_ 1052 1052;
BA_ "GenMsgCycleTime" BO_ 139 100;
BA_ "GenMsgSendType" BO_ 139 5;
BA_ "FrameRouting" BO_ 1186 "FD1_CAN,0x4A2;";
BA_ "FrameGatewayNetwork" BO_ 1186 "FD1_CAN";
BA_ "FrameGatewayId" BO_ 1186 1186;
BA_ "FrameRouting" BO_ 1042 "FD1_CAN,0x412;";
BA_ "FrameGatewayNetwork" BO_ 1042 "FD1_CAN";
BA_ "FrameGatewayId" BO_ 1042 1042;
BA_ "GenMsgDelayTime" BO_ 138 0;
BA_ "GenMsgCycleTime" BO_ 138 10;
BA_ "GenMsgSendType" BO_ 138 0;
BA_ "NetworkInitialization" BO_ 1878 0;
BA_ "GenMsgDelayTime" BO_ 1878 0;
BA_ "GenMsgSendType" BO_ 1878 1;
BA_ "DiagRequest" BO_ 1878 1;
BA_ "GenMsgILSupport" BO_ 1878 0;
BA_ "NetworkInitialization" BO_ 1951 0;
BA_ "GenMsgDelayTime" BO_ 1951 0;
BA_ "GenMsgSendType" BO_ 1951 1;
BA_ "DiagResponse" BO_ 1951 1;
BA_ "GenMsgILSupport" BO_ 1951 0;
BA_ "NetworkInitialization" BO_ 1943 0;
BA_ "GenMsgDelayTime" BO_ 1943 0;
BA_ "GenMsgSendType" BO_ 1943 1;
BA_ "DiagRequest" BO_ 1943 1;
BA_ "GenMsgILSupport" BO_ 1943 0;
BA_ "NetworkInitialization" BO_ 1485 0;
BA_ "GenMsgCycleTime" BO_ 1485 1000;
BA_ "GenMsgSendType" BO_ 1485 0;
BA_ "NmAsrMessage" BO_ 1485 1;
BA_ "GenMsgILSupport" BO_ 1485 0;
BA_ "FrameRouting" BO_ 132 "HS1_CAN,0x84;";
BA_ "FrameGatewayNetwork" BO_ 132 "HS1_CAN";
BA_ "FrameGatewayId" BO_ 132 132;
BA_ "GenMsgDelayTime" BO_ 133 0;
BA_ "GenMsgCycleTime" BO_ 133 10;
BA_ "GenMsgSendType" BO_ 133 0;
BA_ "FrameRouting" BO_ 1200 "FD1_CAN,0x4B0;";
BA_ "FrameGatewayNetwork" BO_ 1200 "FD1_CAN";
BA_ "FrameGatewayId" BO_ 1200 1200;
BA_ "GenMsgCycleTime" BO_ 1106 1000;
BA_ "GenMsgSendType" BO_ 1106 5;
BA_ "FrameRouting" BO_ 945 "HS1_CAN,0x3B1;";
BA_ "FrameGatewayNetwork" BO_ 945 "HS1_CAN";
BA_ "FrameGatewayId" BO_ 945 945;
BA_ "FrameRouting" BO_ 1122 "HS3_CAN,0x462;";
BA_ "FrameGatewayNetwork" BO_ 1122 "HS3_CAN";
BA_ "FrameGatewayId" BO_ 1122 1122;
BA_ "GenMsgCycleTime" BO_ 1080 1000;
BA_ "GenMsgSendType" BO_ 1080 5;
BA_ "GenMsgCycleTime" BO_ 1121 1000;
BA_ "GenMsgSendType" BO_ 1121 5;
BA_ "FrameRouting" BO_ 517 "FD1_CAN,0x205;";
BA_ "FrameGatewayNetwork" BO_ 517 "FD1_CAN";
BA_ "FrameGatewayId" BO_ 517 517;
BA_ "GenMsgDelayTime" BO_ 517 10;
BA_ "FrameRouting" BO_ 1215 "HS3_CAN,0x22F;";
BA_ "FrameGatewayNetwork" BO_ 1215 "HS3_CAN";
BA_ "FrameGatewayId" BO_ 1215 559;
BA_ "FrameRouting" BO_ 1214 "HS3_CAN,0x22E;";
BA_ "FrameGatewayNetwork" BO_ 1214 "HS3_CAN";
BA_ "FrameGatewayId" BO_ 1214 558;
BA_ "GenMsgCycleTime" BO_ 673 100;
BA_ "GenMsgSendType" BO_ 673 5;
BA_ "FrameRouting" BO_ 845 "MS1_CAN,0x34D;";
BA_ "FrameGatewayNetwork" BO_ 845 "MS1_CAN";
BA_ "FrameGatewayId" BO_ 845 845;
BA_ "FrameRouting" BO_ 850 "MS1_CAN,0x352;";
BA_ "FrameGatewayNetwork" BO_ 850 "MS1_CAN";
BA_ "FrameGatewayId" BO_ 850 850;
BA_ "FrameRouting" BO_ 820 "FD1_CAN,0x334;";
BA_ "FrameGatewayNetwork" BO_ 820 "FD1_CAN";
BA_ "FrameGatewayId" BO_ 820 820;
BA_ "FrameRouting" BO_ 935 "FD1_CAN,0x3A7;MS1_CAN,0x3A7";
BA_ "FrameRouting" BO_ 934 "FD1_CAN,0x3A6;MS1_CAN,0x3A6";
BA_ "GenMsgCycleTime" BO_ 1073 1000;
BA_ "GenMsgSendType" BO_ 1073 5;
BA_ "NetworkInitialization" BO_ 1876 0;
BA_ "GenMsgDelayTime" BO_ 1876 0;
BA_ "GenMsgSendType" BO_ 1876 1;
BA_ "DiagRequest" BO_ 1876 1;
BA_ "GenMsgILSupport" BO_ 1876 0;
BA_ "FrameRouting" BO_ 71 "FD1_CAN,0x47;";
BA_ "FrameGatewayNetwork" BO_ 71 "FD1_CAN";
BA_ "FrameGatewayId" BO_ 71 71;
BA_ "GenMsgDelayTime" BO_ 71 10;
BA_ "GenMsgCycleTime" BO_ 837 1000;
BA_ "GenMsgSendType" BO_ 837 5;
BA_ "U_P702_MY2021_Rx" SG_ 1114 TrlBrkInitOut_D_Rq 1;
BA_ "U_T6_MCA_MY2020_Tx" SG_ 939 PrkAidSnsRlSide_D_Stat 1;
BA_ "U_T6_MCA_MY2020_Tx" SG_ 939 SidePrkSnsR4_D_Stat 1;
BA_ "GenSigSendType" SG_ 939 SidePrkSnsR4_D_Stat 3;
BA_ "U_T6_MCA_MY2020_Tx" SG_ 939 SidePrkSnsR3_D_Stat 1;
BA_ "GenSigSendType" SG_ 939 SidePrkSnsR3_D_Stat 3;
BA_ "U_T6_MCA_MY2020_Tx" SG_ 939 SidePrkSnsL4_D_Stat 1;
BA_ "GenSigSendType" SG_ 939 SidePrkSnsL4_D_Stat 3;
BA_ "U_T6_MCA_MY2020_Tx" SG_ 939 SidePrkSnsL3_D_Stat 1;
BA_ "GenSigSendType" SG_ 939 SidePrkSnsL3_D_Stat 3;
BA_ "U_CD764_MY2022_Tx" SG_ 939 PrkAidChime_D_Stat 1;
BA_ "U_T6_MCA_MY2020_Tx" SG_ 939 PrkAidChime_D_Stat 1;
BA_ "GenSigSendType" SG_ 939 PrkAidChime_D_Stat 3;
BA_ "U_CD764_MY2022_Tx" SG_ 939 PrkAidSnsRlCntr_D_Stat 1;
BA_ "U_T6_MCA_MY2020_Tx" SG_ 939 PrkAidSnsRlCntr_D_Stat 1;
BA_ "GenSigSendType" SG_ 939 PrkAidSnsRlCntr_D_Stat 3;
BA_ "U_CD764_MY2022_Tx" SG_ 939 PrkAidSnsRrCrnr_D_Stat 1;
BA_ "U_T6_MCA_MY2020_Tx" SG_ 939 PrkAidSnsRrCrnr_D_Stat 1;
BA_ "GenSigSendType" SG_ 939 PrkAidSnsRrCrnr_D_Stat 3;
BA_ "U_CD764_MY2022_Tx" SG_ 939 PrkAidSnsRrCntr_D_Stat 1;
BA_ "U_T6_MCA_MY2020_Tx" SG_ 939 PrkAidSnsRrCntr_D_Stat 1;
BA_ "GenSigSendType" SG_ 939 PrkAidSnsRrCntr_D_Stat 3;
BA_ "U_CD764_MY2022_Tx" SG_ 939 PrkAidSnsRlCrnr_D_Stat 1;
BA_ "U_T6_MCA_MY2020_Tx" SG_ 939 PrkAidSnsRlCrnr_D_Stat 1;
BA_ "GenSigSendType" SG_ 939 PrkAidSnsRlCrnr_D_Stat 3;
BA_ "U_CD764_MY2022_Tx" SG_ 939 PrkAidRear_D_Stat 1;
BA_ "U_T6_MCA_MY2020_Tx" SG_ 939 PrkAidRear_D_Stat 1;
BA_ "GenSigSendType" SG_ 939 PrkAidRear_D_Stat 3;
BA_ "U_CD764_MY2022_Tx" SG_ 939 PrkAidFront_D_Stat 1;
BA_ "U_T6_MCA_MY2020_Tx" SG_ 939 PrkAidFront_D_Stat 1;
BA_ "GenSigSendType" SG_ 939 PrkAidFront_D_Stat 3;
BA_ "U_CD764_MY2022_Tx" SG_ 939 PrkAid_D_Falt 1;
BA_ "U_T6_MCA_MY2020_Tx" SG_ 939 PrkAid_D_Falt 1;
BA_ "GenSigSendType" SG_ 939 PrkAid_D_Falt 3;
BA_ "U_T6_MCA_MY2020_Tx" SG_ 939 PrkAidSnsRrSide_D_Stat 1;
BA_ "U_CD764_MY2022_Tx" SG_ 939 PrkAidLamp_D_Rq 1;
BA_ "U_T6_MCA_MY2020_Tx" SG_ 939 PrkAidLamp_D_Rq 1;
BA_ "U_U55X_MY2022_Rx" SG_ 939 PrkAidLamp_D_Rq 1;
BA_ "U_T6_MCA_MY2020_Rx" SG_ 939 PrkAidLamp_D_Rq 1;
BA_ "GenSigSendType" SG_ 939 PrkAidLamp_D_Rq 3;
BA_ "U_T6_MCA_MY2020_Tx" SG_ 939 ApaLongCtrlEnbl_D_Rq 1;
BA_ "GenSigSendType" SG_ 939 ApaLongCtrlEnbl_D_Rq 3;
BA_ "U_T6_MCA_MY2020_Tx" SG_ 939 ApaBrk_A_Rq 1;
BA_ "GenSigStartValue" SG_ 939 ApaBrk_A_Rq 255;
BA_ "GenSigStartValueInteger" SG_ 939 ApaBrk_A_Rq 255;
BA_ "U_T6_MCA_MY2020_Tx" SG_ 938 SidePrkSnsR2_D_Stat 1;
BA_ "GenSigSendType" SG_ 938 SidePrkSnsR2_D_Stat 3;
BA_ "U_T6_MCA_MY2020_Tx" SG_ 938 SidePrkSnsR1_D_Stat 1;
BA_ "GenSigSendType" SG_ 938 SidePrkSnsR1_D_Stat 3;
BA_ "U_T6_MCA_MY2020_Tx" SG_ 938 SidePrkSnsL2_D_Stat 1;
BA_ "GenSigSendType" SG_ 938 SidePrkSnsL2_D_Stat 3;
BA_ "U_T6_MCA_MY2020_Tx" SG_ 938 SidePrkSnsL1_D_Stat 1;
BA_ "GenSigSendType" SG_ 938 SidePrkSnsL1_D_Stat 3;
BA_ "U_T6_MCA_MY2020_Tx" SG_ 938 ApaMde_D_Stat 1;
BA_ "GenSigSendType" SG_ 938 ApaMde_D_Stat 3;
BA_ "U_T6_MCA_MY2020_Tx" SG_ 938 ApaActvSd_D_Actl 1;
BA_ "GenSigSendType" SG_ 938 ApaActvSd_D_Actl 3;
BA_ "GenSigStartValue" SG_ 938 ApaActvSd_D_Actl 1;
BA_ "GenSigStartValueInteger" SG_ 938 ApaActvSd_D_Actl 1;
BA_ "U_CD764_MY2022_Tx" SG_ 938 PrkAidSwtch_B_Stat 1;
BA_ "U_T6_MCA_MY2020_Tx" SG_ 938 PrkAidSwtch_B_Stat 1;
BA_ "GenSigSendType" SG_ 938 PrkAidSwtch_B_Stat 3;
BA_ "U_T6_MCA_MY2020_Tx" SG_ 938 ApaMde_D_Avail 1;
BA_ "GenSigSendType" SG_ 938 ApaMde_D_Avail 3;
BA_ "U_CD764_MY2022_Tx" SG_ 938 PrkAidSnsFrSide_D_Stat 1;
BA_ "U_T6_MCA_MY2020_Tx" SG_ 938 PrkAidSnsFrSide_D_Stat 1;
BA_ "GenSigSendType" SG_ 938 PrkAidSnsFrSide_D_Stat 3;
BA_ "U_CD764_MY2022_Tx" SG_ 938 PrkAidSnsFrCrnr_D_Stat 1;
BA_ "U_T6_MCA_MY2020_Tx" SG_ 938 PrkAidSnsFrCrnr_D_Stat 1;
BA_ "GenSigSendType" SG_ 938 PrkAidSnsFrCrnr_D_Stat 3;
BA_ "U_CD764_MY2022_Tx" SG_ 938 PrkAidSnsFrCntr_D_Stat 1;
BA_ "U_T6_MCA_MY2020_Tx" SG_ 938 PrkAidSnsFrCntr_D_Stat 1;
BA_ "GenSigSendType" SG_ 938 PrkAidSnsFrCntr_D_Stat 3;
BA_ "U_CD764_MY2022_Tx" SG_ 938 PrkAidSnsFlSide_D_Stat 1;
BA_ "U_T6_MCA_MY2020_Tx" SG_ 938 PrkAidSnsFlSide_D_Stat 1;
BA_ "GenSigSendType" SG_ 938 PrkAidSnsFlSide_D_Stat 3;
BA_ "U_CD764_MY2022_Tx" SG_ 938 PrkAidSnsFlCrnr_D_Stat 1;
BA_ "U_T6_MCA_MY2020_Tx" SG_ 938 PrkAidSnsFlCrnr_D_Stat 1;
BA_ "GenSigSendType" SG_ 938 PrkAidSnsFlCrnr_D_Stat 3;
BA_ "U_CD764_MY2022_Tx" SG_ 938 PrkAidSnsFlCntr_D_Stat 1;
BA_ "U_T6_MCA_MY2020_Tx" SG_ 938 PrkAidSnsFlCntr_D_Stat 1;
BA_ "GenSigSendType" SG_ 938 PrkAidSnsFlCntr_D_Stat 3;
BA_ "U_CD764_MY2022_Tx" SG_ 938 RpaChime_D_Rq 1;
BA_ "U_T6_MCA_MY2020_Tx" SG_ 938 RpaChime_D_Rq 1;
BA_ "GenSigSendType" SG_ 938 RpaChime_D_Rq 3;
BA_ "U_CD764_MY2022_Tx" SG_ 938 FpaChime_D_Rq 1;
BA_ "U_T6_MCA_MY2020_Tx" SG_ 938 FpaChime_D_Rq 1;
BA_ "GenSigSendType" SG_ 938 FpaChime_D_Rq 3;
BA_ "U_CD764_MY2022_Tx" SG_ 938 PrkAidMsgTxt_D_Rq 1;
BA_ "U_T6_MCA_MY2020_Tx" SG_ 938 PrkAidMsgTxt_D_Rq 1;
BA_ "GenSigSendType" SG_ 938 PrkAidMsgTxt_D_Rq 3;
BA_ "U_CD764_MY2022_Tx" SG_ 938 PrkAidAudioMute_B_Rq 1;
BA_ "U_T6_MCA_MY2020_Tx" SG_ 938 PrkAidAudioMute_B_Rq 1;
BA_ "GenSigSendType" SG_ 938 PrkAidAudioMute_B_Rq 3;
BA_ "U_T6_MCA_MY2020_Tx" SG_ 938 PrkBrkEl_B_RqFap 1;
BA_ "GenSigSendType" SG_ 938 PrkBrkEl_B_RqFap 3;
BA_ "U_CD764_MY2022_Tx" SG_ 863 SteWhlHeat_D_Stat 1;
BA_ "U_U55X_MY2022_Tx" SG_ 863 SteWhlHeat_D_Stat 1;
BA_ "U_CD542_MY2021_Tx" SG_ 863 SteWhlHeat_D_Stat 1;
BA_ "U_T6_MCA_MY2020_Tx" SG_ 863 SteWhlHeat_D_Stat 1;
BA_ "U_P702_MY2021_Tx" SG_ 863 SteWhlHeat_D_Stat 1;
BA_ "U_CX727_MY2021_Tx" SG_ 863 SteWhlHeat_D_Stat 1;
BA_ "GenSigSendType" SG_ 863 SteWhlHeat_D_Stat 3;
BA_ "GenSigStartValue" SG_ 1472 TBM_GWOnBoardTester 255;
BA_ "ContentDependant" SG_ 1472 TBM_GWOnBoardTester 1;
BA_ "GenSigStartValueInteger" SG_ 1472 TBM_GWOnBoardTester 255;
BA_ "GenSigStartValue" SG_ 1472 TBM_GWNMProxy 255;
BA_ "ContentDependant" SG_ 1472 TBM_GWNMProxy 1;
BA_ "GenSigStartValueInteger" SG_ 1472 TBM_GWNMProxy 255;
BA_ "GenSigStartValue" SG_ 1472 TBM_AutoSarNMReserved4 255;
BA_ "ContentDependant" SG_ 1472 TBM_AutoSarNMReserved4 1;
BA_ "GenSigStartValueInteger" SG_ 1472 TBM_AutoSarNMReserved4 255;
BA_ "GenSigStartValue" SG_ 1472 TBM_AutoSarNMReserved3 255;
BA_ "ContentDependant" SG_ 1472 TBM_AutoSarNMReserved3 1;
BA_ "GenSigStartValueInteger" SG_ 1472 TBM_AutoSarNMReserved3 255;
BA_ "GenSigStartValue" SG_ 1472 TBM_AutoSarNMReserved2 255;
BA_ "ContentDependant" SG_ 1472 TBM_AutoSarNMReserved2 1;
BA_ "GenSigStartValueInteger" SG_ 1472 TBM_AutoSarNMReserved2 255;
BA_ "GenSigStartValue" SG_ 1472 TBM_AutoSarNMReserved1 255;
BA_ "ContentDependant" SG_ 1472 TBM_AutoSarNMReserved1 1;
BA_ "GenSigStartValueInteger" SG_ 1472 TBM_AutoSarNMReserved1 255;
BA_ "GenSigStartValue" SG_ 1472 TBM_AutoSarNMNodeId 192;
BA_ "ContentDependant" SG_ 1472 TBM_AutoSarNMNodeId 1;
BA_ "GenSigStartValueInteger" SG_ 1472 TBM_AutoSarNMNodeId 192;
BA_ "U_P702_MY2021_Tx" SG_ 1472 TBM_AutoSarNMControl 1;
BA_ "ContentDependant" SG_ 1472 TBM_AutoSarNMControl 1;
BA_ "U_CD764_MY2022_Tx" SG_ 2612030680 PARSEDPushFcGWM_ECGtoGSM 1;
BA_ "U_U55X_MY2022_Tx" SG_ 2612030680 PARSEDPushFcGWM_ECGtoGSM 1;
BA_ "U_CD542_MY2021_Tx" SG_ 2612030680 PARSEDPushFcGWM_ECGtoGSM 1;
BA_ "ECGUsedTxSignal" SG_ 2612030680 PARSEDPushFcGWM_ECGtoGSM 1;
BA_ "GenSigSendType" SG_ 2612030680 PARSEDPushFcGWM_ECGtoGSM 3;
BA_ "U_CD542_MY2021_Rx" SG_ 981 AdbRamping_T_Rq 1;
BA_ "U_T6_MCA_MY2020_Rx" SG_ 981 AdbRamping_T_Rq 1;
BA_ "U_CD542_MY2021_Rx" SG_ 981 AdbBrdrTop_An_Rq 1;
BA_ "U_T6_MCA_MY2020_Rx" SG_ 981 AdbBrdrTop_An_Rq 1;
BA_ "GenSigStartValue" SG_ 981 AdbBrdrTop_An_Rq 254;
BA_ "U_CD542_MY2021_Rx" SG_ 981 AdbBrdrRight_L_Stat 1;
BA_ "U_T6_MCA_MY2020_Rx" SG_ 981 AdbBrdrRight_L_Stat 1;
BA_ "GenSigStartValue" SG_ 981 AdbBrdrRight_L_Stat 510;
BA_ "U_CD542_MY2021_Rx" SG_ 981 AdbBrdrRight_An_Rq 1;
BA_ "U_T6_MCA_MY2020_Rx" SG_ 981 AdbBrdrRight_An_Rq 1;
BA_ "GenSigStartValue" SG_ 981 AdbBrdrRight_An_Rq 1022;
BA_ "U_CD542_MY2021_Rx" SG_ 981 AdbBrdrLeft_L_Stat 1;
BA_ "U_T6_MCA_MY2020_Rx" SG_ 981 AdbBrdrLeft_L_Stat 1;
BA_ "GenSigStartValue" SG_ 981 AdbBrdrLeft_L_Stat 510;
BA_ "U_CD542_MY2021_Rx" SG_ 981 AdbBrdrLeft_An_Rq 1;
BA_ "U_T6_MCA_MY2020_Rx" SG_ 981 AdbBrdrLeft_An_Rq 1;
BA_ "GenSigStartValue" SG_ 981 AdbBrdrLeft_An_Rq 1022;
BA_ "U_CD542_MY2021_Rx" SG_ 981 AdbBrdrBottom_An_Rq 1;
BA_ "U_T6_MCA_MY2020_Rx" SG_ 981 AdbBrdrBottom_An_Rq 1;
BA_ "GenSigStartValue" SG_ 981 AdbBrdrBottom_An_Rq 62;
BA_ "U_CD542_MY2021_Rx" SG_ 981 AdbBeam_D_Rq 1;
BA_ "U_T6_MCA_MY2020_Rx" SG_ 981 AdbBeam_D_Rq 1;
BA_ "U_CD764_MY2022_Rx" SG_ 2611175451 PARSEDPhysGSMtoGWM_ECG 1;
BA_ "U_U55X_MY2022_Rx" SG_ 2611175451 PARSEDPhysGSMtoGWM_ECG 1;
BA_ "U_CD542_MY2021_Rx" SG_ 2611175451 PARSEDPhysGSMtoGWM_ECG 1;
BA_ "ECGUsedRxSignal" SG_ 2611175451 PARSEDPhysGSMtoGWM_ECG 1;
BA_ "GenSigSendType" SG_ 2611175451 PARSEDPhysGSMtoGWM_ECG 3;
BA_ "U_CD542_MY2021_Rx" SG_ 1844 TesterPhysicalReqHCM 1;
BA_ "U_T6_MCA_MY2020_Rx" SG_ 1844 TesterPhysicalReqHCM 1;
BA_ "U_P702_MY2021_Rx" SG_ 1844 TesterPhysicalReqHCM 1;
BA_ "U_CX727_MY2021_Rx" SG_ 1844 TesterPhysicalReqHCM 1;
BA_ "GenSigSendType" SG_ 1844 TesterPhysicalReqHCM 3;
BA_ "U_CD542_MY2021_Tx" SG_ 1852 TesterPhysicalResHCM 1;
BA_ "U_T6_MCA_MY2020_Tx" SG_ 1852 TesterPhysicalResHCM 1;
BA_ "U_P702_MY2021_Tx" SG_ 1852 TesterPhysicalResHCM 1;
BA_ "U_CX727_MY2021_Tx" SG_ 1852 TesterPhysicalResHCM 1;
BA_ "GenSigSendType" SG_ 1852 TesterPhysicalResHCM 3;
BA_ "U_CD542_MY2021_Tx" SG_ 989 FeatNoHcm_No_Actl 1;
BA_ "U_T6_MCA_MY2020_Tx" SG_ 989 FeatNoHcm_No_Actl 1;
BA_ "U_P702_MY2021_Tx" SG_ 989 FeatNoHcm_No_Actl 1;
BA_ "U_CX727_MY2021_Tx" SG_ 989 FeatNoHcm_No_Actl 1;
BA_ "GenSigSendType" SG_ 989 FeatNoHcm_No_Actl 3;
BA_ "U_CD542_MY2021_Tx" SG_ 989 FeatConfigHcmActl 1;
BA_ "U_T6_MCA_MY2020_Tx" SG_ 989 FeatConfigHcmActl 1;
BA_ "U_P702_MY2021_Tx" SG_ 989 FeatConfigHcmActl 1;
BA_ "U_CX727_MY2021_Tx" SG_ 989 FeatConfigHcmActl 1;
BA_ "GenSigSendType" SG_ 989 FeatConfigHcmActl 3;
BA_ "U_CD764_MY2022_Tx" SG_ 2612002008 PARSEDFuncGWM_ECG 1;
BA_ "U_U55X_MY2022_Tx" SG_ 2612002008 PARSEDFuncGWM_ECG 1;
BA_ "U_CD542_MY2021_Tx" SG_ 2612002008 PARSEDFuncGWM_ECG 1;
BA_ "ECGUsedTxSignal" SG_ 2612002008 PARSEDFuncGWM_ECG 1;
BA_ "U_T6_MCA_MY2020_Tx" SG_ 2612002008 PARSEDFuncGWM_ECG 1;
BA_ "GenSigSendType" SG_ 2612002008 PARSEDFuncGWM_ECG 3;
BA_ "U_CD764_MY2022_Tx" SG_ 2610953432 OTAFuncGWM_ECG 1;
BA_ "U_U55X_MY2022_Tx" SG_ 2610953432 OTAFuncGWM_ECG 1;
BA_ "U_CD542_MY2021_Tx" SG_ 2610953432 OTAFuncGWM_ECG 1;
BA_ "ECGUsedTxSignal" SG_ 2610953432 OTAFuncGWM_ECG 1;
BA_ "U_T6_MCA_MY2020_Tx" SG_ 2610953432 OTAFuncGWM_ECG 1;
BA_ "U_P702_MY2021_Rx" SG_ 2610953432 OTAFuncGWM_ECG 1;
BA_ "U_CX727_MY2021_Rx" SG_ 2610953432 OTAFuncGWM_ECG 1;
BA_ "U_CD764_MY2022_Rx" SG_ 2610953432 OTAFuncGWM_ECG 1;
BA_ "U_CD542_MY2021_Rx" SG_ 2610953432 OTAFuncGWM_ECG 1;
BA_ "U_T6_MCA_MY2020_Rx" SG_ 2610953432 OTAFuncGWM_ECG 1;
BA_ "GenSigSendType" SG_ 2610953432 OTAFuncGWM_ECG 3;
BA_ "U_CD764_MY2022_Tx" SG_ 2609933528 OTAPhysGWM_ECGtoGSM 1;
BA_ "U_U55X_MY2022_Tx" SG_ 2609933528 OTAPhysGWM_ECGtoGSM 1;
BA_ "U_CD542_MY2021_Tx" SG_ 2609933528 OTAPhysGWM_ECGtoGSM 1;
BA_ "ECGUsedTxSignal" SG_ 2609933528 OTAPhysGWM_ECGtoGSM 1;
BA_ "U_T6_MCA_MY2020_Tx" SG_ 2609933528 OTAPhysGWM_ECGtoGSM 1;
BA_ "U_CD764_MY2022_Rx" SG_ 2609933528 OTAPhysGWM_ECGtoGSM 1;
BA_ "U_CD542_MY2021_Rx" SG_ 2609933528 OTAPhysGWM_ECGtoGSM 1;
BA_ "U_T6_MCA_MY2020_Rx" SG_ 2609933528 OTAPhysGWM_ECGtoGSM 1;
BA_ "GenSigSendType" SG_ 2609933528 OTAPhysGWM_ECGtoGSM 3;
BA_ "U_CD764_MY2022_Tx" SG_ 2610126875 OTAPhysGSMtoGWM_ECG 1;
BA_ "U_CD542_MY2021_Tx" SG_ 2610126875 OTAPhysGSMtoGWM_ECG 1;
BA_ "U_T6_MCA_MY2020_Tx" SG_ 2610126875 OTAPhysGSMtoGWM_ECG 1;
BA_ "U_CD764_MY2022_Rx" SG_ 2610126875 OTAPhysGSMtoGWM_ECG 1;
BA_ "U_U55X_MY2022_Rx" SG_ 2610126875 OTAPhysGSMtoGWM_ECG 1;
BA_ "U_CD542_MY2021_Rx" SG_ 2610126875 OTAPhysGSMtoGWM_ECG 1;
BA_ "ECGUsedRxSignal" SG_ 2610126875 OTAPhysGSMtoGWM_ECG 1;
BA_ "U_T6_MCA_MY2020_Rx" SG_ 2610126875 OTAPhysGSMtoGWM_ECG 1;
BA_ "GenSigSendType" SG_ 2610126875 OTAPhysGSMtoGWM_ECG 3;
BA_ "GenSigSendType" SG_ 1105 TrlrRvrseEnbl_D2_Stat 3;
BA_ "GenSigSendType" SG_ 1105 TrlrRvrseMsgTxt_D2_Rq 3;
BA_ "GenSigSendType" SG_ 1105 RbaMsg_D_Rq 3;
BA_ "GenSigSendType" SG_ 1105 BrkDecel_B_RqRba 3;
BA_ "WakeupSignal" SG_ 1105 BrkDecel_B_RqRba 1;
BA_ "GenSigSendType" SG_ 1105 BrkEnbl_B_RqRba 3;
BA_ "WakeupSignal" SG_ 1105 BrkEnbl_B_RqRba 1;
BA_ "GenSigSendType" SG_ 1105 Rba_D_Stat 3;
BA_ "GenSigStartValue" SG_ 1105 Rba_D_Stat 1;
BA_ "GenSigStartValueInteger" SG_ 1105 Rba_D_Stat 1;
BA_ "GenSigSendType" SG_ 1105 RbaAlrt_D_Dsply 3;
BA_ "GenSigSendType" SG_ 1105 RbaMnu_D_Rq 3;
BA_ "GenSigSendType" SG_ 1105 RbaSys_D_Stat 3;
BA_ "GenSigStartValue" SG_ 1105 RbaSys_D_Stat 2;
BA_ "GenSigStartValueInteger" SG_ 1105 RbaSys_D_Stat 2;
BA_ "GenSigSendType" SG_ 1105 CamraFrntStat_D_Stat 3;
BA_ "GenSigSendType" SG_ 1105 TrlrHitchLamp_D_Rq2 3;
BA_ "GenSigSendType" SG_ 1105 ClrExitAsstMsgTxt2_D_Rq 3;
BA_ "GenSigSendType" SG_ 1105 ClrExitAsstActv_B_Rq 3;
BA_ "GenSigSendType" SG_ 1105 CamraFrntOffRd_B_Stat 3;
BA_ "GenSigSendType" SG_ 1105 TrlrAidSwtchLamp_B_Rq 3;
BA_ "GenSigSendType" SG_ 1105 TrlrAidEnbl_D_RqAdas 3;
BA_ "GenSigSendType" SG_ 1105 TrlrHitchMsgTxt_D_Rq 3;
BA_ "GenSigSendType" SG_ 1105 TrlrHitchIcon_D_Rq 3;
BA_ "GenSigSendType" SG_ 1105 TrlrHitchChime_D_Rq 3;
BA_ "GenSigStartValue" SG_ 1056 ActvDrvMde_D2_Stat 31;
BA_ "GenSigStartValueInteger" SG_ 1056 ActvDrvMde_D2_Stat 31;
BA_ "GenSigStartValue" SG_ 1056 SelDrvMde_D2_Rq 31;
BA_ "GenSigStartValueInteger" SG_ 1056 SelDrvMde_D2_Rq 31;
BA_ "GenSigStartValue" SG_ 1056 AwdMde_D_RqBrk 5;
BA_ "GenSigStartValueInteger" SG_ 1056 AwdMde_D_RqBrk 5;
BA_ "GenSigStartValueInteger" SG_ 1047 TrlrAnOffst_An2_Calc 128;
BA_ "GenSigStartValue" SG_ 1047 EsaOn_B_Stat 1;
BA_ "GenSigStartValueInteger" SG_ 1047 EsaOn_B_Stat 1;
BA_ "GenSigSendType" SG_ 1892 TesterPhysicalReqCCM 3;
BA_ "GenSigSendType" SG_ 1969 TesterPhysicalReqIPMB 3;
BA_ "GenSigSendType" SG_ 1798 TesterPhysicalReqIPMA 3;
BA_ "GenSigSendType" SG_ 1900 TesterPhysicalResCCM 3;
BA_ "GenSigSendType" SG_ 1806 TesterPhysicalResIPMA 3;
BA_ "GenSigSendType" SG_ 997 PersIndexCcm_D_Actl 3;
BA_ "GenSigStartValue" SG_ 997 PersIndexCcm_D_Actl 4;
BA_ "GenSigStartValueInteger" SG_ 997 PersIndexCcm_D_Actl 4;
BA_ "GenSigSendType" SG_ 997 FeatNoCcmActl 3;
BA_ "GenSigSendType" SG_ 997 FeatConfigCcmActl 3;
BA_ "GenSigSendType" SG_ 997 PersTurnSglView_D_Stat 3;
BA_ "GenSigStartValue" SG_ 997 PersTurnSglView_D_Stat 3;
BA_ "U_P702_MY2021_Rx" SG_ 962 AdbBrdr3DistRigh_D_Stat 1;
BA_ "U_CX727_MY2021_Rx" SG_ 962 AdbBrdr3DistRigh_D_Stat 1;
BA_ "GenSigSendType" SG_ 962 AdbBrdr3DistRigh_D_Stat 3;
BA_ "U_P702_MY2021_Rx" SG_ 962 AdbBrdr3DistLeft_D_Stat 1;
BA_ "U_CX727_MY2021_Rx" SG_ 962 AdbBrdr3DistLeft_D_Stat 1;
BA_ "GenSigSendType" SG_ 962 AdbBrdr3DistLeft_D_Stat 3;
BA_ "U_P702_MY2021_Rx" SG_ 962 AdbMde3_D_Rq 1;
BA_ "U_CX727_MY2021_Rx" SG_ 962 AdbMde3_D_Rq 1;
BA_ "GenSigSendType" SG_ 962 AdbMde3_D_Rq 3;
BA_ "U_P702_MY2021_Rx" SG_ 962 AdbIntns3_D_Rq 1;
BA_ "U_CX727_MY2021_Rx" SG_ 962 AdbIntns3_D_Rq 1;
BA_ "GenSigSendType" SG_ 962 AdbIntns3_D_Rq 3;
BA_ "U_P702_MY2021_Rx" SG_ 962 AdbBrdr3Up_An_Rq 1;
BA_ "U_CX727_MY2021_Rx" SG_ 962 AdbBrdr3Up_An_Rq 1;
BA_ "GenSigStartValue" SG_ 962 AdbBrdr3Up_An_Rq 509;
BA_ "GenSigStartValueInteger" SG_ 962 AdbBrdr3Up_An_Rq 510;
BA_ "U_P702_MY2021_Rx" SG_ 962 AdbBrdr3Right_An_Rq 1;
BA_ "U_CX727_MY2021_Rx" SG_ 962 AdbBrdr3Right_An_Rq 1;
BA_ "GenSigStartValue" SG_ 962 AdbBrdr3Right_An_Rq 2046;
BA_ "GenSigStartValueInteger" SG_ 962 AdbBrdr3Right_An_Rq 2046;
BA_ "U_P702_MY2021_Rx" SG_ 962 AdbBrdr3Low_An_Rq 1;
BA_ "U_CX727_MY2021_Rx" SG_ 962 AdbBrdr3Low_An_Rq 1;
BA_ "GenSigStartValue" SG_ 962 AdbBrdr3Low_An_Rq 509;
BA_ "GenSigStartValueInteger" SG_ 962 AdbBrdr3Low_An_Rq 510;
BA_ "U_P702_MY2021_Rx" SG_ 962 AdbBrdr3Left_An_Rq 1;
BA_ "U_CX727_MY2021_Rx" SG_ 962 AdbBrdr3Left_An_Rq 1;
BA_ "GenSigStartValue" SG_ 962 AdbBrdr3Left_An_Rq 2046;
BA_ "GenSigStartValueInteger" SG_ 962 AdbBrdr3Left_An_Rq 2046;
BA_ "U_P702_MY2021_Rx" SG_ 962 AdbBrdr3CritRigh_T_Stat 1;
BA_ "U_CX727_MY2021_Rx" SG_ 962 AdbBrdr3CritRigh_T_Stat 1;
BA_ "U_P702_MY2021_Rx" SG_ 962 AdbBrdr3CritLeft_T_Stat 1;
BA_ "U_CX727_MY2021_Rx" SG_ 962 AdbBrdr3CritLeft_T_Stat 1;
BA_ "U_P702_MY2021_Rx" SG_ 961 AdbBrdr2DistRigh_D_Stat 1;
BA_ "U_CX727_MY2021_Rx" SG_ 961 AdbBrdr2DistRigh_D_Stat 1;
BA_ "GenSigSendType" SG_ 961 AdbBrdr2DistRigh_D_Stat 3;
BA_ "U_P702_MY2021_Rx" SG_ 961 AdbBrdr2DistLeft_D_Stat 1;
BA_ "U_CX727_MY2021_Rx" SG_ 961 AdbBrdr2DistLeft_D_Stat 1;
BA_ "GenSigSendType" SG_ 961 AdbBrdr2DistLeft_D_Stat 3;
BA_ "U_P702_MY2021_Rx" SG_ 961 AdbMde2_D_Rq 1;
BA_ "U_CX727_MY2021_Rx" SG_ 961 AdbMde2_D_Rq 1;
BA_ "GenSigSendType" SG_ 961 AdbMde2_D_Rq 3;
BA_ "U_P702_MY2021_Rx" SG_ 961 AdbIntns2_D_Rq 1;
BA_ "U_CX727_MY2021_Rx" SG_ 961 AdbIntns2_D_Rq 1;
BA_ "GenSigSendType" SG_ 961 AdbIntns2_D_Rq 3;
BA_ "U_P702_MY2021_Rx" SG_ 961 AdbBrdr2Up_An_Rq 1;
BA_ "U_CX727_MY2021_Rx" SG_ 961 AdbBrdr2Up_An_Rq 1;
BA_ "GenSigStartValue" SG_ 961 AdbBrdr2Up_An_Rq 509;
BA_ "GenSigStartValueInteger" SG_ 961 AdbBrdr2Up_An_Rq 510;
BA_ "U_P702_MY2021_Rx" SG_ 961 AdbBrdr2Right_An_Rq 1;
BA_ "U_CX727_MY2021_Rx" SG_ 961 AdbBrdr2Right_An_Rq 1;
BA_ "GenSigStartValue" SG_ 961 AdbBrdr2Right_An_Rq 2046;
BA_ "GenSigStartValueInteger" SG_ 961 AdbBrdr2Right_An_Rq 2046;
BA_ "U_CD542_MY2021_Rx" SG_ 961 AdbBrdr2Low_An_Rq 1;
BA_ "U_P702_MY2021_Rx" SG_ 961 AdbBrdr2Low_An_Rq 1;
BA_ "U_CX727_MY2021_Rx" SG_ 961 AdbBrdr2Low_An_Rq 1;
BA_ "GenSigStartValue" SG_ 961 AdbBrdr2Low_An_Rq 509;
BA_ "GenSigStartValueInteger" SG_ 961 AdbBrdr2Low_An_Rq 510;
BA_ "U_P702_MY2021_Rx" SG_ 961 AdbBrdr2Left_An_Rq 1;
BA_ "U_CX727_MY2021_Rx" SG_ 961 AdbBrdr2Left_An_Rq 1;
BA_ "GenSigStartValue" SG_ 961 AdbBrdr2Left_An_Rq 2046;
BA_ "GenSigStartValueInteger" SG_ 961 AdbBrdr2Left_An_Rq 2046;
BA_ "U_P702_MY2021_Rx" SG_ 961 AdbBrdr2CritRigh_T_Stat 1;
BA_ "U_CX727_MY2021_Rx" SG_ 961 AdbBrdr2CritRigh_T_Stat 1;
BA_ "U_P702_MY2021_Rx" SG_ 961 AdbBrdr2CritLeft_T_Stat 1;
BA_ "U_CX727_MY2021_Rx" SG_ 961 AdbBrdr2CritLeft_T_Stat 1;
BA_ "GenSigSendType" SG_ 394 AccTrgDist2_D_Dsply 3;
BA_ "GenSigSendType" SG_ 394 AccStopRes_B_Dsply 3;
BA_ "GenSigSendType" SG_ 394 TjaWarn_D_Rq 3;
BA_ "GenSigSendType" SG_ 394 Tja_D_Stat 3;
BA_ "GenSigSendType" SG_ 394 IaccLamp_D_Rq 3;
BA_ "GenSigSendType" SG_ 394 AccMsgTxt_D2_Rq 3;
BA_ "GenSigSendType" SG_ 394 TjaMsgTxt_D_Dsply 3;
BA_ "GenSigSendType" SG_ 394 FcwDeny_B_Dsply 3;
BA_ "GenSigSendType" SG_ 394 FcwMemStat_B_Actl 3;
BA_ "GenSigSendType" SG_ 394 AccTGap_B_Dsply 3;
BA_ "GenSigSendType" SG_ 394 CadsAlignIncplt_B_Actl 3;
BA_ "GenSigSendType" SG_ 394 AccFllwMde_B_Dsply 3;
BA_ "GenSigSendType" SG_ 394 CadsRadrBlck_B_Actl 3;
BA_ "GenSigSendType" SG_ 394 CmbbPostEvnt_B_Dsply 3;
BA_ "GenSigSendType" SG_ 394 AccStopMde_B_Dsply 3;
BA_ "GenSigSendType" SG_ 394 FcwMemSens_D_Actl 3;
BA_ "GenSigSendType" SG_ 394 FcwMsgTxt_D_Rq 3;
BA_ "GenSigSendType" SG_ 394 AccTGap_D_Dsply 3;
BA_ "GenSigStartValue" SG_ 394 AccTGap_D_Dsply 3;
BA_ "GenSigStartValueInteger" SG_ 394 AccTGap_D_Dsply 3;
BA_ "GenSigSendType" SG_ 394 AccMemEnbl_B_RqDrv 3;
BA_ "GenSigStartValue" SG_ 394 AccMemEnbl_B_RqDrv 1;
BA_ "GenSigStartValueInteger" SG_ 394 AccMemEnbl_B_RqDrv 1;
BA_ "GenSigSendType" SG_ 394 AccWarn_D_Dsply 3;
BA_ "GenSigSendType" SG_ 394 FcwVisblWarn_B_Rq 3;
BA_ "GenSigSendType" SG_ 394 FcwAudioWarn_B_Rq 3;
BA_ "GenSigSendType" SG_ 394 AccStopStat_D_Dsply 3;
BA_ "GenSigStartValue" SG_ 671 LaneTypeRight_D_Est 1;
BA_ "GenSigStartValueInteger" SG_ 671 LaneTypeRight_D_Est 1;
BA_ "GenSigStartValue" SG_ 671 LaneTypeLeft_D_Est 1;
BA_ "GenSigStartValueInteger" SG_ 671 LaneTypeLeft_D_Est 1;
BA_ "GenSigStartValue" SG_ 671 LaneCurvRight_K_Est 4095;
BA_ "GenSigStartValue" SG_ 671 LaneCurvLeft_K_Est 4095;
BA_ "U_CD764_MY2022_Tx" SG_ 1854 TesterPhysicalResPAM 1;
BA_ "U_T6_MCA_MY2020_Tx" SG_ 1854 TesterPhysicalResPAM 1;
BA_ "GenSigSendType" SG_ 1854 TesterPhysicalResPAM 3;
BA_ "U_CD764_MY2022_Tx" SG_ 942 PrkAidAcsyRear_D_Stat 1;
BA_ "U_CD764_MY2022_Tx" SG_ 942 PrkAidAcsyFront_D_Stat 1;
BA_ "GenSigSendType" SG_ 942 ApaSys_D2_Stat 3;
BA_ "GenSigSendType" SG_ 942 ApaSlotTrgt_D_Stat 3;
BA_ "GenSigSendType" SG_ 942 ApaSlotOption_B_Avail 3;
BA_ "GenSigSendType" SG_ 942 ApaSlotAlrtSet_B_Stat 3;
BA_ "GenSigSendType" SG_ 942 ApaSlotAlrt_B_Rq 3;
BA_ "GenSigSendType" SG_ 942 ApaRmtFeatSel_B_Avail 3;
BA_ "GenSigSendType" SG_ 942 ApaParkOutSel_B_Avail 3;
BA_ "GenSigSendType" SG_ 942 ApaParkInSel_B_Avail 3;
BA_ "GenSigSendType" SG_ 942 ApaMsgTxt_D2_Stat 3;
BA_ "GenSigSendType" SG_ 942 ApaDynmcSlot_B_Stat 3;
BA_ "GenSigSendType" SG_ 942 ApaDisplayMode_D_Stat 3;
BA_ "GenSigSendType" SG_ 942 ApaControlMode_D_Stat 3;
BA_ "U_CD764_MY2022_Tx" SG_ 942 PrkAidRdiusRight_L_Dsply 1;
BA_ "U_T6_MCA_MY2020_Tx" SG_ 942 PrkAidRdiusRight_L_Dsply 1;
BA_ "U_CD764_MY2022_Tx" SG_ 942 PrkAidRdiusLeft_L_Dsply 1;
BA_ "U_T6_MCA_MY2020_Tx" SG_ 942 PrkAidRdiusLeft_L_Dsply 1;
BA_ "U_CD764_MY2022_Tx" SG_ 942 PrkAidDrvDir_D_Stat 1;
BA_ "U_T6_MCA_MY2020_Tx" SG_ 942 PrkAidDrvDir_D_Stat 1;
BA_ "GenSigSendType" SG_ 942 PrkAidDrvDir_D_Stat 3;
BA_ "GenSigStartValue" SG_ 1049 FrontDiffLck_D_RqDrv3 2;
BA_ "GenSigStartValueInteger" SG_ 1049 FrontDiffLck_D_RqDrv3 2;
BA_ "GenSigStartValue" SG_ 1049 RearDiffLck_D_RqDrv3 2;
BA_ "GenSigStartValueInteger" SG_ 1049 RearDiffLck_D_RqDrv3 2;
BA_ "GenSigStartValue" SG_ 1049 SelDrvMde_D_RqDrv 31;
BA_ "U_T6_MCA_MY2020_Tx" SG_ 1487 ATCM_GWOnBoardTester 1;
BA_ "U_U55X_MY2022_Tx" SG_ 1487 ATCM_GWOnBoardTester 1;
BA_ "U_P702_MY2021_Tx" SG_ 1487 ATCM_GWOnBoardTester 1;
BA_ "GenSigStartValue" SG_ 1487 ATCM_GWOnBoardTester 255;
BA_ "ContentDependant" SG_ 1487 ATCM_GWOnBoardTester 1;
BA_ "GenSigStartValueInteger" SG_ 1487 ATCM_GWOnBoardTester 255;
BA_ "U_T6_MCA_MY2020_Tx" SG_ 1487 ATCM_GWNMProxy 1;
BA_ "U_U55X_MY2022_Tx" SG_ 1487 ATCM_GWNMProxy 1;
BA_ "U_P702_MY2021_Tx" SG_ 1487 ATCM_GWNMProxy 1;
BA_ "GenSigStartValue" SG_ 1487 ATCM_GWNMProxy 255;
BA_ "ContentDependant" SG_ 1487 ATCM_GWNMProxy 1;
BA_ "GenSigStartValueInteger" SG_ 1487 ATCM_GWNMProxy 255;
BA_ "U_T6_MCA_MY2020_Tx" SG_ 1487 ATCM_AutoSarNMReserved4 1;
BA_ "U_U55X_MY2022_Tx" SG_ 1487 ATCM_AutoSarNMReserved4 1;
BA_ "U_P702_MY2021_Tx" SG_ 1487 ATCM_AutoSarNMReserved4 1;
BA_ "GenSigStartValue" SG_ 1487 ATCM_AutoSarNMReserved4 255;
BA_ "ContentDependant" SG_ 1487 ATCM_AutoSarNMReserved4 1;
BA_ "GenSigStartValueInteger" SG_ 1487 ATCM_AutoSarNMReserved4 255;
BA_ "U_T6_MCA_MY2020_Tx" SG_ 1487 ATCM_AutoSarNMReserved3 1;
BA_ "U_U55X_MY2022_Tx" SG_ 1487 ATCM_AutoSarNMReserved3 1;
BA_ "U_P702_MY2021_Tx" SG_ 1487 ATCM_AutoSarNMReserved3 1;
BA_ "GenSigStartValue" SG_ 1487 ATCM_AutoSarNMReserved3 255;
BA_ "ContentDependant" SG_ 1487 ATCM_AutoSarNMReserved3 1;
BA_ "GenSigStartValueInteger" SG_ 1487 ATCM_AutoSarNMReserved3 255;
BA_ "U_T6_MCA_MY2020_Tx" SG_ 1487 ATCM_AutoSarNMReserved2 1;
BA_ "U_U55X_MY2022_Tx" SG_ 1487 ATCM_AutoSarNMReserved2 1;
BA_ "U_P702_MY2021_Tx" SG_ 1487 ATCM_AutoSarNMReserved2 1;
BA_ "GenSigStartValue" SG_ 1487 ATCM_AutoSarNMReserved2 255;
BA_ "ContentDependant" SG_ 1487 ATCM_AutoSarNMReserved2 1;
BA_ "GenSigStartValueInteger" SG_ 1487 ATCM_AutoSarNMReserved2 255;
BA_ "U_T6_MCA_MY2020_Tx" SG_ 1487 ATCM_AutoSarNMReserved1 1;
BA_ "U_U55X_MY2022_Tx" SG_ 1487 ATCM_AutoSarNMReserved1 1;
BA_ "U_P702_MY2021_Tx" SG_ 1487 ATCM_AutoSarNMReserved1 1;
BA_ "GenSigStartValue" SG_ 1487 ATCM_AutoSarNMReserved1 255;
BA_ "ContentDependant" SG_ 1487 ATCM_AutoSarNMReserved1 1;
BA_ "GenSigStartValueInteger" SG_ 1487 ATCM_AutoSarNMReserved1 255;
BA_ "U_T6_MCA_MY2020_Tx" SG_ 1487 ATCM_AutoSarNMNodeId 1;
BA_ "U_U55X_MY2022_Tx" SG_ 1487 ATCM_AutoSarNMNodeId 1;
BA_ "U_P702_MY2021_Tx" SG_ 1487 ATCM_AutoSarNMNodeId 1;
BA_ "GenSigStartValue" SG_ 1487 ATCM_AutoSarNMNodeId 207;
BA_ "ContentDependant" SG_ 1487 ATCM_AutoSarNMNodeId 1;
BA_ "GenSigStartValueInteger" SG_ 1487 ATCM_AutoSarNMNodeId 207;
BA_ "U_T6_MCA_MY2020_Tx" SG_ 1487 ATCM_AutoSarNMControl 1;
BA_ "U_U55X_MY2022_Tx" SG_ 1487 ATCM_AutoSarNMControl 1;
BA_ "U_P702_MY2021_Tx" SG_ 1487 ATCM_AutoSarNMControl 1;
BA_ "ContentDependant" SG_ 1487 ATCM_AutoSarNMControl 1;
BA_ "GenSigSendType" SG_ 1120 StabBarCnncButtn_D_Stat 3;
BA_ "GenSigSendType" SG_ 1120 DrvSlipCtlMde_B_Rq3 3;
BA_ "GenSigSendType" SG_ 1120 HybMdeSwtch_B_Rq 3;
BA_ "GenSigSendType" SG_ 1120 FrontDiffLck_D_RqDrv 3;
BA_ "GenSigStartValue" SG_ 1120 FrontDiffLck_D_RqDrv 2;
BA_ "GenSigStartValueInteger" SG_ 1120 FrontDiffLck_D_RqDrv 2;
BA_ "GenSigSendType" SG_ 1120 AwdLck_D_RqDrv 3;
BA_ "GenSigStartValue" SG_ 1120 AwdLck_D_RqDrv 2;
BA_ "GenSigStartValueInteger" SG_ 1120 AwdLck_D_RqDrv 2;
BA_ "GenSigSendType" SG_ 1120 TrailCtlSwtch_B_Stat3 3;
BA_ "U_T6_MCA_MY2020_Tx" SG_ 1120 RearDiffLck_D_RqDrv 1;
BA_ "U_U55X_MY2022_Tx" SG_ 1120 RearDiffLck_D_RqDrv 1;
BA_ "U_P702_MY2021_Tx" SG_ 1120 RearDiffLck_D_RqDrv 1;
BA_ "GenSigSendType" SG_ 1120 RearDiffLck_D_RqDrv 3;
BA_ "GenSigStartValue" SG_ 1120 RearDiffLck_D_RqDrv 2;
BA_ "GenSigStartValueInteger" SG_ 1120 RearDiffLck_D_RqDrv 2;
BA_ "U_T6_MCA_MY2020_Tx" SG_ 1120 AwdMde_D_RqDrv 1;
BA_ "U_U55X_MY2022_Tx" SG_ 1120 AwdMde_D_RqDrv 1;
BA_ "U_P702_MY2021_Tx" SG_ 1120 AwdMde_D_RqDrv 1;
BA_ "GenSigSendType" SG_ 1120 AwdMde_D_RqDrv 3;
BA_ "GenSigStartValue" SG_ 1120 AwdMde_D_RqDrv 5;
BA_ "GenSigStartValueInteger" SG_ 1120 AwdMde_D_RqDrv 5;
BA_ "GenSigSendType" SG_ 1120 HdcSwtchPos_B_Actl 3;
BA_ "U_P702_MY2021_Tx" SG_ 1997 TesterPhysicalResSECM_AFSM 1;
BA_ "GenSigSendType" SG_ 1997 TesterPhysicalResSECM_AFSM 3;
BA_ "U_P702_MY2021_Rx" SG_ 1989 TesterPhysicalReqSECM_AFSM 1;
BA_ "GenSigSendType" SG_ 1989 TesterPhysicalReqSECM_AFSM 3;
BA_ "GenSigStartValue" SG_ 1052 AwdCnnct_D_Stat 1;
BA_ "GenSigStartValueInteger" SG_ 1052 AwdCnnct_D_Stat 1;
BA_ "U_P702_MY2021_Tx" SG_ 139 AccButtnGpTogglePress2 1;
BA_ "U_CD764_MY2022_Rx" SG_ 139 AccButtnGpTogglePress2 1;
BA_ "U_U55X_MY2022_Rx" SG_ 139 AccButtnGpTogglePress2 1;
BA_ "U_CD542_MY2021_Rx" SG_ 139 AccButtnGpTogglePress2 1;
BA_ "U_T6_MCA_MY2020_Rx" SG_ 139 AccButtnGpTogglePress2 1;
BA_ "U_P702_MY2021_Rx" SG_ 139 AccButtnGpTogglePress2 1;
BA_ "GenSigSendType" SG_ 139 AccButtnGpTogglePress2 3;
BA_ "U_P702_MY2021_Tx" SG_ 139 TjaButtnOnOffPress2 1;
BA_ "U_CD764_MY2022_Rx" SG_ 139 TjaButtnOnOffPress2 1;
BA_ "U_U55X_MY2022_Rx" SG_ 139 TjaButtnOnOffPress2 1;
BA_ "U_CD542_MY2021_Rx" SG_ 139 TjaButtnOnOffPress2 1;
BA_ "U_T6_MCA_MY2020_Rx" SG_ 139 TjaButtnOnOffPress2 1;
BA_ "U_P702_MY2021_Rx" SG_ 139 TjaButtnOnOffPress2 1;
BA_ "GenSigSendType" SG_ 139 TjaButtnOnOffPress2 3;
BA_ "U_P702_MY2021_Tx" SG_ 139 ActvFrontSteMsgTxt_D_Rq 1;
BA_ "GenSigSendType" SG_ 139 ActvFrontSteMsgTxt_D_Rq 3;
BA_ "U_P702_MY2021_Tx" SG_ 139 ActvFrontSteLck_D_Stat 1;
BA_ "GenSigSendType" SG_ 139 ActvFrontSteLck_D_Stat 3;
BA_ "U_P702_MY2021_Tx" SG_ 139 SelDrvMdeAdptSte_D_Stat 1;
BA_ "GenSigSendType" SG_ 139 SelDrvMdeAdptSte_D_Stat 3;
BA_ "U_P702_MY2021_Tx" SG_ 139 AslButtnOnOffPress2 1;
BA_ "U_CD764_MY2022_Rx" SG_ 139 AslButtnOnOffPress2 1;
BA_ "U_U55X_MY2022_Rx" SG_ 139 AslButtnOnOffPress2 1;
BA_ "U_CD542_MY2021_Rx" SG_ 139 AslButtnOnOffPress2 1;
BA_ "U_T6_MCA_MY2020_Rx" SG_ 139 AslButtnOnOffPress2 1;
BA_ "U_P702_MY2021_Rx" SG_ 139 AslButtnOnOffPress2 1;
BA_ "GenSigSendType" SG_ 139 AslButtnOnOffPress2 3;
BA_ "U_P702_MY2021_Tx" SG_ 139 AslButtnOnOffCnclPres2 1;
BA_ "U_CD764_MY2022_Rx" SG_ 139 AslButtnOnOffCnclPres2 1;
BA_ "U_U55X_MY2022_Rx" SG_ 139 AslButtnOnOffCnclPres2 1;
BA_ "U_CD542_MY2021_Rx" SG_ 139 AslButtnOnOffCnclPres2 1;
BA_ "U_T6_MCA_MY2020_Rx" SG_ 139 AslButtnOnOffCnclPres2 1;
BA_ "U_P702_MY2021_Rx" SG_ 139 AslButtnOnOffCnclPres2 1;
BA_ "GenSigSendType" SG_ 139 AslButtnOnOffCnclPres2 3;
BA_ "U_P702_MY2021_Tx" SG_ 139 CcButtnOnPress2 1;
BA_ "U_CD764_MY2022_Rx" SG_ 139 CcButtnOnPress2 1;
BA_ "U_U55X_MY2022_Rx" SG_ 139 CcButtnOnPress2 1;
BA_ "U_CD542_MY2021_Rx" SG_ 139 CcButtnOnPress2 1;
BA_ "U_T6_MCA_MY2020_Rx" SG_ 139 CcButtnOnPress2 1;
BA_ "U_P702_MY2021_Rx" SG_ 139 CcButtnOnPress2 1;
BA_ "GenSigSendType" SG_ 139 CcButtnOnPress2 3;
BA_ "U_P702_MY2021_Tx" SG_ 139 CcButtnOnOffPress2 1;
BA_ "U_CD764_MY2022_Rx" SG_ 139 CcButtnOnOffPress2 1;
BA_ "U_U55X_MY2022_Rx" SG_ 139 CcButtnOnOffPress2 1;
BA_ "U_CD542_MY2021_Rx" SG_ 139 CcButtnOnOffPress2 1;
BA_ "U_T6_MCA_MY2020_Rx" SG_ 139 CcButtnOnOffPress2 1;
BA_ "U_P702_MY2021_Rx" SG_ 139 CcButtnOnOffPress2 1;
BA_ "GenSigSendType" SG_ 139 CcButtnOnOffPress2 3;
BA_ "U_P702_MY2021_Tx" SG_ 139 CcButtnOnOffCnclPress2 1;
BA_ "U_CD764_MY2022_Rx" SG_ 139 CcButtnOnOffCnclPress2 1;
BA_ "U_U55X_MY2022_Rx" SG_ 139 CcButtnOnOffCnclPress2 1;
BA_ "U_CD542_MY2021_Rx" SG_ 139 CcButtnOnOffCnclPress2 1;
BA_ "U_T6_MCA_MY2020_Rx" SG_ 139 CcButtnOnOffCnclPress2 1;
BA_ "U_P702_MY2021_Rx" SG_ 139 CcButtnOnOffCnclPress2 1;
BA_ "GenSigSendType" SG_ 139 CcButtnOnOffCnclPress2 3;
BA_ "U_P702_MY2021_Tx" SG_ 139 CcButtnOffPress2 1;
BA_ "U_CD764_MY2022_Rx" SG_ 139 CcButtnOffPress2 1;
BA_ "U_U55X_MY2022_Rx" SG_ 139 CcButtnOffPress2 1;
BA_ "U_CD542_MY2021_Rx" SG_ 139 CcButtnOffPress2 1;
BA_ "U_T6_MCA_MY2020_Rx" SG_ 139 CcButtnOffPress2 1;
BA_ "U_P702_MY2021_Rx" SG_ 139 CcButtnOffPress2 1;
BA_ "GenSigSendType" SG_ 139 CcButtnOffPress2 3;
BA_ "U_P702_MY2021_Tx" SG_ 139 CcAsllButtnResPress2 1;
BA_ "U_CD764_MY2022_Rx" SG_ 139 CcAsllButtnResPress2 1;
BA_ "U_U55X_MY2022_Rx" SG_ 139 CcAsllButtnResPress2 1;
BA_ "U_CD542_MY2021_Rx" SG_ 139 CcAsllButtnResPress2 1;
BA_ "U_T6_MCA_MY2020_Rx" SG_ 139 CcAsllButtnResPress2 1;
BA_ "U_P702_MY2021_Rx" SG_ 139 CcAsllButtnResPress2 1;
BA_ "GenSigSendType" SG_ 139 CcAsllButtnResPress2 3;
BA_ "U_P702_MY2021_Tx" SG_ 139 CcAslButtnSetPress2 1;
BA_ "U_CD764_MY2022_Rx" SG_ 139 CcAslButtnSetPress2 1;
BA_ "U_U55X_MY2022_Rx" SG_ 139 CcAslButtnSetPress2 1;
BA_ "U_CD542_MY2021_Rx" SG_ 139 CcAslButtnSetPress2 1;
BA_ "U_T6_MCA_MY2020_Rx" SG_ 139 CcAslButtnSetPress2 1;
BA_ "U_P702_MY2021_Rx" SG_ 139 CcAslButtnSetPress2 1;
BA_ "GenSigSendType" SG_ 139 CcAslButtnSetPress2 3;
BA_ "U_P702_MY2021_Tx" SG_ 139 CcAslButtnSetIncPress2 1;
BA_ "U_CD764_MY2022_Rx" SG_ 139 CcAslButtnSetIncPress2 1;
BA_ "U_U55X_MY2022_Rx" SG_ 139 CcAslButtnSetIncPress2 1;
BA_ "U_CD542_MY2021_Rx" SG_ 139 CcAslButtnSetIncPress2 1;
BA_ "U_T6_MCA_MY2020_Rx" SG_ 139 CcAslButtnSetIncPress2 1;
BA_ "U_P702_MY2021_Rx" SG_ 139 CcAslButtnSetIncPress2 1;
BA_ "GenSigSendType" SG_ 139 CcAslButtnSetIncPress2 3;
BA_ "U_P702_MY2021_Tx" SG_ 139 CcAslButtnSetDecPress2 1;
BA_ "U_CD764_MY2022_Rx" SG_ 139 CcAslButtnSetDecPress2 1;
BA_ "U_U55X_MY2022_Rx" SG_ 139 CcAslButtnSetDecPress2 1;
BA_ "U_CD542_MY2021_Rx" SG_ 139 CcAslButtnSetDecPress2 1;
BA_ "U_T6_MCA_MY2020_Rx" SG_ 139 CcAslButtnSetDecPress2 1;
BA_ "U_P702_MY2021_Rx" SG_ 139 CcAslButtnSetDecPress2 1;
BA_ "GenSigSendType" SG_ 139 CcAslButtnSetDecPress2 3;
BA_ "U_P702_MY2021_Tx" SG_ 139 CcAslButtnResIncPress2 1;
BA_ "U_CD764_MY2022_Rx" SG_ 139 CcAslButtnResIncPress2 1;
BA_ "U_U55X_MY2022_Rx" SG_ 139 CcAslButtnResIncPress2 1;
BA_ "U_CD542_MY2021_Rx" SG_ 139 CcAslButtnResIncPress2 1;
BA_ "U_T6_MCA_MY2020_Rx" SG_ 139 CcAslButtnResIncPress2 1;
BA_ "U_P702_MY2021_Rx" SG_ 139 CcAslButtnResIncPress2 1;
BA_ "GenSigSendType" SG_ 139 CcAslButtnResIncPress2 3;
BA_ "U_P702_MY2021_Tx" SG_ 139 CcAslButtnResDecPress2 1;
BA_ "U_CD764_MY2022_Rx" SG_ 139 CcAslButtnResDecPress2 1;
BA_ "U_U55X_MY2022_Rx" SG_ 139 CcAslButtnResDecPress2 1;
BA_ "U_CD542_MY2021_Rx" SG_ 139 CcAslButtnResDecPress2 1;
BA_ "U_T6_MCA_MY2020_Rx" SG_ 139 CcAslButtnResDecPress2 1;
BA_ "U_P702_MY2021_Rx" SG_ 139 CcAslButtnResDecPress2 1;
BA_ "GenSigSendType" SG_ 139 CcAslButtnResDecPress2 3;
BA_ "U_P702_MY2021_Tx" SG_ 139 CcAslButtnOnPress2 1;
BA_ "U_CD764_MY2022_Rx" SG_ 139 CcAslButtnOnPress2 1;
BA_ "U_U55X_MY2022_Rx" SG_ 139 CcAslButtnOnPress2 1;
BA_ "U_CD542_MY2021_Rx" SG_ 139 CcAslButtnOnPress2 1;
BA_ "U_T6_MCA_MY2020_Rx" SG_ 139 CcAslButtnOnPress2 1;
BA_ "U_P702_MY2021_Rx" SG_ 139 CcAslButtnOnPress2 1;
BA_ "GenSigSendType" SG_ 139 CcAslButtnOnPress2 3;
BA_ "U_P702_MY2021_Tx" SG_ 139 CcAslButtnOnOffCncl2 1;
BA_ "U_CD764_MY2022_Rx" SG_ 139 CcAslButtnOnOffCncl2 1;
BA_ "U_U55X_MY2022_Rx" SG_ 139 CcAslButtnOnOffCncl2 1;
BA_ "U_CD542_MY2021_Rx" SG_ 139 CcAslButtnOnOffCncl2 1;
BA_ "U_T6_MCA_MY2020_Rx" SG_ 139 CcAslButtnOnOffCncl2 1;
BA_ "U_P702_MY2021_Rx" SG_ 139 CcAslButtnOnOffCncl2 1;
BA_ "GenSigSendType" SG_ 139 CcAslButtnOnOffCncl2 3;
BA_ "U_P702_MY2021_Tx" SG_ 139 CcAslButtnOffCnclPres2 1;
BA_ "U_CD764_MY2022_Rx" SG_ 139 CcAslButtnOffCnclPres2 1;
BA_ "U_U55X_MY2022_Rx" SG_ 139 CcAslButtnOffCnclPres2 1;
BA_ "U_CD542_MY2021_Rx" SG_ 139 CcAslButtnOffCnclPres2 1;
BA_ "U_T6_MCA_MY2020_Rx" SG_ 139 CcAslButtnOffCnclPres2 1;
BA_ "U_P702_MY2021_Rx" SG_ 139 CcAslButtnOffCnclPres2 1;
BA_ "GenSigSendType" SG_ 139 CcAslButtnOffCnclPres2 3;
BA_ "U_P702_MY2021_Tx" SG_ 139 CcAslButtnIndxIncPres2 1;
BA_ "U_CD764_MY2022_Rx" SG_ 139 CcAslButtnIndxIncPres2 1;
BA_ "U_U55X_MY2022_Rx" SG_ 139 CcAslButtnIndxIncPres2 1;
BA_ "U_CD542_MY2021_Rx" SG_ 139 CcAslButtnIndxIncPres2 1;
BA_ "U_T6_MCA_MY2020_Rx" SG_ 139 CcAslButtnIndxIncPres2 1;
BA_ "U_P702_MY2021_Rx" SG_ 139 CcAslButtnIndxIncPres2 1;
BA_ "GenSigSendType" SG_ 139 CcAslButtnIndxIncPres2 3;
BA_ "U_P702_MY2021_Tx" SG_ 139 CcAslButtnIndxDecPres2 1;
BA_ "U_CD764_MY2022_Rx" SG_ 139 CcAslButtnIndxDecPres2 1;
BA_ "U_U55X_MY2022_Rx" SG_ 139 CcAslButtnIndxDecPres2 1;
BA_ "U_CD542_MY2021_Rx" SG_ 139 CcAslButtnIndxDecPres2 1;
BA_ "U_T6_MCA_MY2020_Rx" SG_ 139 CcAslButtnIndxDecPres2 1;
BA_ "U_P702_MY2021_Rx" SG_ 139 CcAslButtnIndxDecPres2 1;
BA_ "GenSigSendType" SG_ 139 CcAslButtnIndxDecPres2 3;
BA_ "U_P702_MY2021_Tx" SG_ 139 CcAslButtnDeny_B_Actl2 1;
BA_ "U_CD764_MY2022_Rx" SG_ 139 CcAslButtnDeny_B_Actl2 1;
BA_ "U_U55X_MY2022_Rx" SG_ 139 CcAslButtnDeny_B_Actl2 1;
BA_ "U_CD542_MY2021_Rx" SG_ 139 CcAslButtnDeny_B_Actl2 1;
BA_ "U_T6_MCA_MY2020_Rx" SG_ 139 CcAslButtnDeny_B_Actl2 1;
BA_ "U_P702_MY2021_Rx" SG_ 139 CcAslButtnDeny_B_Actl2 1;
BA_ "GenSigSendType" SG_ 139 CcAslButtnDeny_B_Actl2 3;
BA_ "U_P702_MY2021_Tx" SG_ 139 CcAslButtnCnclResPres2 1;
BA_ "U_CD764_MY2022_Rx" SG_ 139 CcAslButtnCnclResPres2 1;
BA_ "U_U55X_MY2022_Rx" SG_ 139 CcAslButtnCnclResPres2 1;
BA_ "U_CD542_MY2021_Rx" SG_ 139 CcAslButtnCnclResPres2 1;
BA_ "U_T6_MCA_MY2020_Rx" SG_ 139 CcAslButtnCnclResPres2 1;
BA_ "U_P702_MY2021_Rx" SG_ 139 CcAslButtnCnclResPres2 1;
BA_ "GenSigSendType" SG_ 139 CcAslButtnCnclResPres2 3;
BA_ "U_P702_MY2021_Tx" SG_ 139 CcAslButtnCnclPress2 1;
BA_ "U_CD764_MY2022_Rx" SG_ 139 CcAslButtnCnclPress2 1;
BA_ "U_U55X_MY2022_Rx" SG_ 139 CcAslButtnCnclPress2 1;
BA_ "U_CD542_MY2021_Rx" SG_ 139 CcAslButtnCnclPress2 1;
BA_ "U_T6_MCA_MY2020_Rx" SG_ 139 CcAslButtnCnclPress2 1;
BA_ "U_P702_MY2021_Rx" SG_ 139 CcAslButtnCnclPress2 1;
BA_ "GenSigSendType" SG_ 139 CcAslButtnCnclPress2 3;
BA_ "U_P702_MY2021_Tx" SG_ 139 AccButtnGapIncPress2 1;
BA_ "U_CD764_MY2022_Rx" SG_ 139 AccButtnGapIncPress2 1;
BA_ "U_U55X_MY2022_Rx" SG_ 139 AccButtnGapIncPress2 1;
BA_ "U_CD542_MY2021_Rx" SG_ 139 AccButtnGapIncPress2 1;
BA_ "U_T6_MCA_MY2020_Rx" SG_ 139 AccButtnGapIncPress2 1;
BA_ "U_P702_MY2021_Rx" SG_ 139 AccButtnGapIncPress2 1;
BA_ "GenSigSendType" SG_ 139 AccButtnGapIncPress2 3;
BA_ "U_P702_MY2021_Tx" SG_ 139 AccButtnGapDecPress2 1;
BA_ "U_CD764_MY2022_Rx" SG_ 139 AccButtnGapDecPress2 1;
BA_ "U_U55X_MY2022_Rx" SG_ 139 AccButtnGapDecPress2 1;
BA_ "U_CD542_MY2021_Rx" SG_ 139 AccButtnGapDecPress2 1;
BA_ "U_T6_MCA_MY2020_Rx" SG_ 139 AccButtnGapDecPress2 1;
BA_ "U_P702_MY2021_Rx" SG_ 139 AccButtnGapDecPress2 1;
BA_ "GenSigSendType" SG_ 139 AccButtnGapDecPress2 3;
BA_ "U_P702_MY2021_Tx" SG_ 139 AfsPw_B_Rq 1;
BA_ "GenSigSendType" SG_ 139 AfsPw_B_Rq 3;
BA_ "GenSigStartValue" SG_ 1186 FrontDiffLck_Tq_Actl 16382;
BA_ "GenSigStartValue" SG_ 1186 SelDrvMdeAwd2_D_Stat 31;
BA_ "GenSigStartValueInteger" SG_ 1186 SelDrvMdeAwd2_D_Stat 31;
BA_ "U_U55X_MY2022_Rx" SG_ 1186 RearDiffLckLamp_D_Rq 1;
BA_ "U_P702_MY2021_Rx" SG_ 1186 RearDiffLckLamp_D_Rq 1;
BA_ "GenSigStartValueInteger" SG_ 1042 VehRol_An_Dsply 64;
BA_ "GenSigStartValueInteger" SG_ 1042 VehPtch_An_Dsply 64;
BA_ "U_P702_MY2021_Rx" SG_ 1042 TrlrBrk_Pc_Rq 1;
BA_ "U_P702_MY2021_Tx" SG_ 138 SteWhlRelCalib_T_Actl 1;
BA_ "U_P702_MY2021_Tx" SG_ 138 SteWhlRelCalib_An_Sns 1;
BA_ "U_CD764_MY2022_Rx" SG_ 138 SteWhlRelCalib_An_Sns 1;
BA_ "U_T6_MCA_MY2020_Rx" SG_ 138 SteWhlRelCalib_An_Sns 1;
BA_ "U_P702_MY2021_Rx" SG_ 138 SteWhlRelCalib_An_Sns 1;
BA_ "ContentDependant" SG_ 138 SteWhlRelCalib_An_Sns 1;
BA_ "GenSigSendType" SG_ 1878 TesterPhysicalReqPBM 3;
BA_ "U_P702_MY2021_Tx" SG_ 1951 TesterPhysicalResSASM 1;
BA_ "GenSigSendType" SG_ 1951 TesterPhysicalResSASM 3;
BA_ "U_P702_MY2021_Rx" SG_ 1943 TesterPhysicalReqSASM 1;
BA_ "GenSigSendType" SG_ 1943 TesterPhysicalReqSASM 3;
BA_ "U_P702_MY2021_Tx" SG_ 1485 SASM_GWOnBoardTester 1;
BA_ "GenSigStartValue" SG_ 1485 SASM_GWOnBoardTester 255;
BA_ "ContentDependant" SG_ 1485 SASM_GWOnBoardTester 1;
BA_ "GenSigStartValueInteger" SG_ 1485 SASM_GWOnBoardTester 255;
BA_ "U_P702_MY2021_Tx" SG_ 1485 SASM_GWNMProxy 1;
BA_ "GenSigStartValue" SG_ 1485 SASM_GWNMProxy 255;
BA_ "ContentDependant" SG_ 1485 SASM_GWNMProxy 1;
BA_ "GenSigStartValueInteger" SG_ 1485 SASM_GWNMProxy 255;
BA_ "U_P702_MY2021_Tx" SG_ 1485 SASM_AutoSarNMReserved4 1;
BA_ "GenSigStartValue" SG_ 1485 SASM_AutoSarNMReserved4 255;
BA_ "ContentDependant" SG_ 1485 SASM_AutoSarNMReserved4 1;
BA_ "GenSigStartValueInteger" SG_ 1485 SASM_AutoSarNMReserved4 255;
BA_ "U_P702_MY2021_Tx" SG_ 1485 SASM_AutoSarNMReserved3 1;
BA_ "GenSigStartValue" SG_ 1485 SASM_AutoSarNMReserved3 255;
BA_ "ContentDependant" SG_ 1485 SASM_AutoSarNMReserved3 1;
BA_ "GenSigStartValueInteger" SG_ 1485 SASM_AutoSarNMReserved3 255;
BA_ "U_P702_MY2021_Tx" SG_ 1485 SASM_AutoSarNMReserved2 1;
BA_ "GenSigStartValue" SG_ 1485 SASM_AutoSarNMReserved2 255;
BA_ "ContentDependant" SG_ 1485 SASM_AutoSarNMReserved2 1;
BA_ "GenSigStartValueInteger" SG_ 1485 SASM_AutoSarNMReserved2 255;
BA_ "U_P702_MY2021_Tx" SG_ 1485 SASM_AutoSarNMReserved1 1;
BA_ "GenSigStartValue" SG_ 1485 SASM_AutoSarNMReserved1 255;
BA_ "ContentDependant" SG_ 1485 SASM_AutoSarNMReserved1 1;
BA_ "GenSigStartValueInteger" SG_ 1485 SASM_AutoSarNMReserved1 255;
BA_ "U_P702_MY2021_Tx" SG_ 1485 SASM_AutoSarNMNodeId 1;
BA_ "GenSigStartValue" SG_ 1485 SASM_AutoSarNMNodeId 205;
BA_ "ContentDependant" SG_ 1485 SASM_AutoSarNMNodeId 1;
BA_ "GenSigStartValueInteger" SG_ 1485 SASM_AutoSarNMNodeId 205;
BA_ "U_P702_MY2021_Tx" SG_ 1485 SASM_AutoSarNMControl 1;
BA_ "ContentDependant" SG_ 1485 SASM_AutoSarNMControl 1;
BA_ "U_CD764_MY2022_Rx" SG_ 132 GlblClkYr_No_Actl 1;
BA_ "U_U55X_MY2022_Rx" SG_ 132 GlblClkYr_No_Actl 1;
BA_ "U_T6_MCA_MY2020_Rx" SG_ 132 GlblClkYr_No_Actl 1;
BA_ "U_CD764_MY2022_Rx" SG_ 132 GlblClkScnd_No_Actl 1;
BA_ "U_U55X_MY2022_Rx" SG_ 132 GlblClkScnd_No_Actl 1;
BA_ "U_T6_MCA_MY2020_Rx" SG_ 132 GlblClkScnd_No_Actl 1;
BA_ "U_CD764_MY2022_Rx" SG_ 132 GlblClkMnte_No_Actl 1;
BA_ "U_U55X_MY2022_Rx" SG_ 132 GlblClkMnte_No_Actl 1;
BA_ "U_T6_MCA_MY2020_Rx" SG_ 132 GlblClkMnte_No_Actl 1;
BA_ "U_CD764_MY2022_Rx" SG_ 132 GlblClkHr_No_Actl 1;
BA_ "U_U55X_MY2022_Rx" SG_ 132 GlblClkHr_No_Actl 1;
BA_ "U_T6_MCA_MY2020_Rx" SG_ 132 GlblClkHr_No_Actl 1;
BA_ "U_CD764_MY2022_Rx" SG_ 132 GlblClkDay_No_Actl 1;
BA_ "U_U55X_MY2022_Rx" SG_ 132 GlblClkDay_No_Actl 1;
BA_ "U_T6_MCA_MY2020_Rx" SG_ 132 GlblClkDay_No_Actl 1;
BA_ "GenSigStartValue" SG_ 133 SteWhlOSRelInit2An_Est 65533;
BA_ "ContentDependant" SG_ 133 SteWhlOSRelInit2An_Est 1;
BA_ "GenSigStartValueInteger" SG_ 133 SteWhlOSRelInit2An_Est 65534;
BA_ "MetaData" SG_ 133 SteWhlAn_No_Cs 1;
BA_ "ContentDependant" SG_ 133 SteWhlAn_No_Cs 1;
BA_ "MetaData" SG_ 133 SteWhlAn_No_Cnt 1;
BA_ "ContentDependant" SG_ 133 SteWhlAn_No_Cnt 1;
BA_ "U_P702_MY2021_Tx" SG_ 133 SteWhlRelCalib_An_Sns 1;
BA_ "U_CD764_MY2022_Rx" SG_ 133 SteWhlRelCalib_An_Sns 1;
BA_ "U_T6_MCA_MY2020_Rx" SG_ 133 SteWhlRelCalib_An_Sns 1;
BA_ "U_P702_MY2021_Rx" SG_ 133 SteWhlRelCalib_An_Sns 1;
BA_ "ContentDependant" SG_ 133 SteWhlRelCalib_An_Sns 1;
BA_ "GenSigStartValue" SG_ 133 SteWhlRelInit2_An_Sns 65535;
BA_ "ContentDependant" SG_ 133 SteWhlRelInit2_An_Sns 1;
BA_ "GenSigStartValueInteger" SG_ 133 SteWhlRelInit2_An_Sns 65535;
BA_ "U_P702_MY2021_Rx" SG_ 980 AdbBrdr1DistRigh_D_Stat 1;
BA_ "U_CX727_MY2021_Rx" SG_ 980 AdbBrdr1DistRigh_D_Stat 1;
BA_ "U_P702_MY2021_Rx" SG_ 980 AdbBrdr1DistLeft_D_Stat 1;
BA_ "U_CX727_MY2021_Rx" SG_ 980 AdbBrdr1DistLeft_D_Stat 1;
BA_ "U_P702_MY2021_Rx" SG_ 980 AdbMde1_D_Rq 1;
BA_ "U_CX727_MY2021_Rx" SG_ 980 AdbMde1_D_Rq 1;
BA_ "U_P702_MY2021_Rx" SG_ 980 AdbIntns1_D_Rq 1;
BA_ "U_CX727_MY2021_Rx" SG_ 980 AdbIntns1_D_Rq 1;
BA_ "U_P702_MY2021_Rx" SG_ 980 AdbBrdr1Up_An_Rq 1;
BA_ "U_CX727_MY2021_Rx" SG_ 980 AdbBrdr1Up_An_Rq 1;
BA_ "GenSigStartValue" SG_ 980 AdbBrdr1Up_An_Rq 509;
BA_ "GenSigStartValueInteger" SG_ 980 AdbBrdr1Up_An_Rq 510;
BA_ "U_P702_MY2021_Rx" SG_ 980 AdbBrdr1Right_An_Rq 1;
BA_ "U_CX727_MY2021_Rx" SG_ 980 AdbBrdr1Right_An_Rq 1;
BA_ "GenSigStartValue" SG_ 980 AdbBrdr1Right_An_Rq 2046;
BA_ "GenSigStartValueInteger" SG_ 980 AdbBrdr1Right_An_Rq 2046;
BA_ "U_P702_MY2021_Rx" SG_ 980 AdbBrdr1Low_An_Rq 1;
BA_ "U_CX727_MY2021_Rx" SG_ 980 AdbBrdr1Low_An_Rq 1;
BA_ "GenSigStartValue" SG_ 980 AdbBrdr1Low_An_Rq 509;
BA_ "GenSigStartValueInteger" SG_ 980 AdbBrdr1Low_An_Rq 510;
BA_ "U_P702_MY2021_Rx" SG_ 980 AdbBrdr1Left_An_Rq 1;
BA_ "U_CX727_MY2021_Rx" SG_ 980 AdbBrdr1Left_An_Rq 1;
BA_ "GenSigStartValue" SG_ 980 AdbBrdr1Left_An_Rq 2046;
BA_ "GenSigStartValueInteger" SG_ 980 AdbBrdr1Left_An_Rq 2046;
BA_ "U_P702_MY2021_Rx" SG_ 980 AdbBrdr1CritRigh_T_Stat 1;
BA_ "U_CX727_MY2021_Rx" SG_ 980 AdbBrdr1CritRigh_T_Stat 1;
BA_ "U_P702_MY2021_Rx" SG_ 980 AdbBrdr1CritLeft_T_Stat 1;
BA_ "U_CX727_MY2021_Rx" SG_ 980 AdbBrdr1CritLeft_T_Stat 1;
BA_ "GenSigStartValueInteger" SG_ 1200 HsaTrnAout_Tq_Rq 32768;
BA_ "GenSigStartValue" SG_ 1200 BrkBstrVac_P_Actl 127;
BA_ "GenSigStartValueInteger" SG_ 1200 BrkBstrVac_P_Actl 127;
BA_ "U_P702_MY2021_Rx" SG_ 1200 YawStabilityIndex 1;
BA_ "GenSigStartValueInteger" SG_ 1200 YawStabilityIndex 256;
BA_ "MetaData" SG_ 1200 BrkTotTqRqDrv_No_Cnt 1;
BA_ "MetaData" SG_ 1200 BrkTotTqRqDrv_No_Cs 1;
BA_ "U_CD764_MY2022_Tx" SG_ 1106 TrlrSnsId_No_Actl 1;
BA_ "U_T6_MCA_MY2020_Tx" SG_ 1106 TrlrSnsId_No_Actl 1;
BA_ "GenSigSendType" SG_ 1106 TrlrSnsId_No_Actl 3;
BA_ "WakeupSignal" SG_ 945 PrkLckCtlMsgTxt_D2_Rq 1;
BA_ "WakeupSignal" SG_ 945 PwLoApim_T_Actl 1;
BA_ "WakeupSignal" SG_ 945 KeyPadCodeDgt6_D_Dsply 1;
BA_ "WakeupSignal" SG_ 945 KeyPadCodeDgt5_D_Dsply 1;
BA_ "WakeupSignal" SG_ 945 KeyPadCodeDgt4_D_Dsply 1;
BA_ "WakeupSignal" SG_ 945 KeyPadCodeDgt3_D_Dsply 1;
BA_ "WakeupSignal" SG_ 945 KeyPadCodeDgt2_D_Dsply 1;
BA_ "WakeupSignal" SG_ 945 KeyPadCodeDgt1_D_Dsply 1;
BA_ "GenSigStartValueInteger" SG_ 1122 GPS_Longitude_Degrees 179;
BA_ "GenSigSendType" SG_ 1080 TrlrAidMde_D_Rq 3;
BA_ "GenSigSendType" SG_ 1080 Rba_D_Rq 3;
BA_ "GenSigSendType" SG_ 1080 TrailCtlSwtch_B_Stat 3;
BA_ "GenSigSendType" SG_ 1080 TrailCtlPt_B_Falt 3;
BA_ "GenSigSendType" SG_ 1080 AutoTowActv_B_Stat 3;
BA_ "U_T6_MCA_MY2020_Rx" SG_ 1080 DrLatchLckRr_B_Stat_UB 1;
BA_ "U_P702_MY2021_Rx" SG_ 1080 DrLatchLckRr_B_Stat_UB 1;
BA_ "U_CX727_MY2021_Rx" SG_ 1080 DrLatchLckRr_B_Stat_UB 1;
BA_ "U_T6_MCA_MY2020_Rx" SG_ 1080 DrLatchLckRl_B_Stat_UB 1;
BA_ "U_P702_MY2021_Rx" SG_ 1080 DrLatchLckRl_B_Stat_UB 1;
BA_ "U_CX727_MY2021_Rx" SG_ 1080 DrLatchLckRl_B_Stat_UB 1;
BA_ "U_CD764_MY2022_Rx" SG_ 1080 DrLatchLckFr_B_Stat_UB 1;
BA_ "U_U55X_MY2022_Rx" SG_ 1080 DrLatchLckFr_B_Stat_UB 1;
BA_ "U_CD542_MY2021_Rx" SG_ 1080 DrLatchLckFr_B_Stat_UB 1;
BA_ "U_T6_MCA_MY2020_Rx" SG_ 1080 DrLatchLckFr_B_Stat_UB 1;
BA_ "U_P702_MY2021_Rx" SG_ 1080 DrLatchLckFr_B_Stat_UB 1;
BA_ "U_CX727_MY2021_Rx" SG_ 1080 DrLatchLckFr_B_Stat_UB 1;
BA_ "U_CD764_MY2022_Rx" SG_ 1080 DrLatchLckFl_B_Stat_UB 1;
BA_ "U_U55X_MY2022_Rx" SG_ 1080 DrLatchLckFl_B_Stat_UB 1;
BA_ "U_CD542_MY2021_Rx" SG_ 1080 DrLatchLckFl_B_Stat_UB 1;
BA_ "U_T6_MCA_MY2020_Rx" SG_ 1080 DrLatchLckFl_B_Stat_UB 1;
BA_ "U_P702_MY2021_Rx" SG_ 1080 DrLatchLckFl_B_Stat_UB 1;
BA_ "U_CX727_MY2021_Rx" SG_ 1080 DrLatchLckFl_B_Stat_UB 1;
BA_ "U_T6_MCA_MY2020_Rx" SG_ 1080 DrLatchRr_B_Falt_UB 1;
BA_ "U_P702_MY2021_Rx" SG_ 1080 DrLatchRr_B_Falt_UB 1;
BA_ "U_CX727_MY2021_Rx" SG_ 1080 DrLatchRr_B_Falt_UB 1;
BA_ "U_T6_MCA_MY2020_Rx" SG_ 1080 DrLatchRl_B_Falt_UB 1;
BA_ "U_P702_MY2021_Rx" SG_ 1080 DrLatchRl_B_Falt_UB 1;
BA_ "U_CX727_MY2021_Rx" SG_ 1080 DrLatchRl_B_Falt_UB 1;
BA_ "U_CD764_MY2022_Rx" SG_ 1080 DrLatchFr_B_Falt_UB 1;
BA_ "U_U55X_MY2022_Rx" SG_ 1080 DrLatchFr_B_Falt_UB 1;
BA_ "U_CD542_MY2021_Rx" SG_ 1080 DrLatchFr_B_Falt_UB 1;
BA_ "U_T6_MCA_MY2020_Rx" SG_ 1080 DrLatchFr_B_Falt_UB 1;
BA_ "U_P702_MY2021_Rx" SG_ 1080 DrLatchFr_B_Falt_UB 1;
BA_ "U_CX727_MY2021_Rx" SG_ 1080 DrLatchFr_B_Falt_UB 1;
BA_ "U_CD764_MY2022_Rx" SG_ 1080 DrLatchFl_B_Falt_UB 1;
BA_ "U_U55X_MY2022_Rx" SG_ 1080 DrLatchFl_B_Falt_UB 1;
BA_ "U_CD542_MY2021_Rx" SG_ 1080 DrLatchFl_B_Falt_UB 1;
BA_ "U_T6_MCA_MY2020_Rx" SG_ 1080 DrLatchFl_B_Falt_UB 1;
BA_ "U_P702_MY2021_Rx" SG_ 1080 DrLatchFl_B_Falt_UB 1;
BA_ "U_CX727_MY2021_Rx" SG_ 1080 DrLatchFl_B_Falt_UB 1;
BA_ "U_T6_MCA_MY2020_Rx" SG_ 1080 DrLatchCntRr_No_Actl_UB 1;
BA_ "U_P702_MY2021_Rx" SG_ 1080 DrLatchCntRr_No_Actl_UB 1;
BA_ "U_CX727_MY2021_Rx" SG_ 1080 DrLatchCntRr_No_Actl_UB 1;
BA_ "U_T6_MCA_MY2020_Rx" SG_ 1080 DrLatchCntRl_No_Actl_UB 1;
BA_ "U_P702_MY2021_Rx" SG_ 1080 DrLatchCntRl_No_Actl_UB 1;
BA_ "U_CX727_MY2021_Rx" SG_ 1080 DrLatchCntRl_No_Actl_UB 1;
BA_ "U_CD764_MY2022_Rx" SG_ 1080 DrLatchCntFr_No_Actl_UB 1;
BA_ "U_U55X_MY2022_Rx" SG_ 1080 DrLatchCntFr_No_Actl_UB 1;
BA_ "U_CD542_MY2021_Rx" SG_ 1080 DrLatchCntFr_No_Actl_UB 1;
BA_ "U_T6_MCA_MY2020_Rx" SG_ 1080 DrLatchCntFr_No_Actl_UB 1;
BA_ "U_P702_MY2021_Rx" SG_ 1080 DrLatchCntFr_No_Actl_UB 1;
BA_ "U_CX727_MY2021_Rx" SG_ 1080 DrLatchCntFr_No_Actl_UB 1;
BA_ "U_CD764_MY2022_Rx" SG_ 1080 DrLatchCntFl_No_Actl_UB 1;
BA_ "U_U55X_MY2022_Rx" SG_ 1080 DrLatchCntFl_No_Actl_UB 1;
BA_ "U_CD542_MY2021_Rx" SG_ 1080 DrLatchCntFl_No_Actl_UB 1;
BA_ "U_T6_MCA_MY2020_Rx" SG_ 1080 DrLatchCntFl_No_Actl_UB 1;
BA_ "U_P702_MY2021_Rx" SG_ 1080 DrLatchCntFl_No_Actl_UB 1;
BA_ "U_CX727_MY2021_Rx" SG_ 1080 DrLatchCntFl_No_Actl_UB 1;
BA_ "U_T6_MCA_MY2020_Rx" SG_ 1080 DrLatchRr_B_Falt 1;
BA_ "U_P702_MY2021_Rx" SG_ 1080 DrLatchRr_B_Falt 1;
BA_ "U_CX727_MY2021_Rx" SG_ 1080 DrLatchRr_B_Falt 1;
BA_ "U_T6_MCA_MY2020_Rx" SG_ 1080 DrLatchRl_B_Falt 1;
BA_ "U_P702_MY2021_Rx" SG_ 1080 DrLatchRl_B_Falt 1;
BA_ "U_CX727_MY2021_Rx" SG_ 1080 DrLatchRl_B_Falt 1;
BA_ "U_T6_MCA_MY2020_Rx" SG_ 1080 DrLatchLckRr_B_Stat 1;
BA_ "U_P702_MY2021_Rx" SG_ 1080 DrLatchLckRr_B_Stat 1;
BA_ "U_CX727_MY2021_Rx" SG_ 1080 DrLatchLckRr_B_Stat 1;
BA_ "U_T6_MCA_MY2020_Rx" SG_ 1080 DrLatchLckRl_B_Stat 1;
BA_ "U_P702_MY2021_Rx" SG_ 1080 DrLatchLckRl_B_Stat 1;
BA_ "U_CX727_MY2021_Rx" SG_ 1080 DrLatchLckRl_B_Stat 1;
BA_ "U_CD764_MY2022_Rx" SG_ 1080 DrLatchLckFr_B_Stat 1;
BA_ "U_U55X_MY2022_Rx" SG_ 1080 DrLatchLckFr_B_Stat 1;
BA_ "U_CD542_MY2021_Rx" SG_ 1080 DrLatchLckFr_B_Stat 1;
BA_ "U_T6_MCA_MY2020_Rx" SG_ 1080 DrLatchLckFr_B_Stat 1;
BA_ "U_P702_MY2021_Rx" SG_ 1080 DrLatchLckFr_B_Stat 1;
BA_ "U_CX727_MY2021_Rx" SG_ 1080 DrLatchLckFr_B_Stat 1;
BA_ "U_CD764_MY2022_Rx" SG_ 1080 DrLatchLckFl_B_Stat 1;
BA_ "U_U55X_MY2022_Rx" SG_ 1080 DrLatchLckFl_B_Stat 1;
BA_ "U_CD542_MY2021_Rx" SG_ 1080 DrLatchLckFl_B_Stat 1;
BA_ "U_T6_MCA_MY2020_Rx" SG_ 1080 DrLatchLckFl_B_Stat 1;
BA_ "U_P702_MY2021_Rx" SG_ 1080 DrLatchLckFl_B_Stat 1;
BA_ "U_CX727_MY2021_Rx" SG_ 1080 DrLatchLckFl_B_Stat 1;
BA_ "U_CD764_MY2022_Rx" SG_ 1080 DrLatchFr_B_Falt 1;
BA_ "U_U55X_MY2022_Rx" SG_ 1080 DrLatchFr_B_Falt 1;
BA_ "U_CD542_MY2021_Rx" SG_ 1080 DrLatchFr_B_Falt 1;
BA_ "U_T6_MCA_MY2020_Rx" SG_ 1080 DrLatchFr_B_Falt 1;
BA_ "U_P702_MY2021_Rx" SG_ 1080 DrLatchFr_B_Falt 1;
BA_ "U_CX727_MY2021_Rx" SG_ 1080 DrLatchFr_B_Falt 1;
BA_ "U_CD764_MY2022_Rx" SG_ 1080 DrLatchFl_B_Falt 1;
BA_ "U_U55X_MY2022_Rx" SG_ 1080 DrLatchFl_B_Falt 1;
BA_ "U_CD542_MY2021_Rx" SG_ 1080 DrLatchFl_B_Falt 1;
BA_ "U_T6_MCA_MY2020_Rx" SG_ 1080 DrLatchFl_B_Falt 1;
BA_ "U_P702_MY2021_Rx" SG_ 1080 DrLatchFl_B_Falt 1;
BA_ "U_CX727_MY2021_Rx" SG_ 1080 DrLatchFl_B_Falt 1;
BA_ "U_T6_MCA_MY2020_Rx" SG_ 1080 DrLatchCntRr_No_Actl 1;
BA_ "U_P702_MY2021_Rx" SG_ 1080 DrLatchCntRr_No_Actl 1;
BA_ "U_CX727_MY2021_Rx" SG_ 1080 DrLatchCntRr_No_Actl 1;
BA_ "U_T6_MCA_MY2020_Rx" SG_ 1080 DrLatchCntRl_No_Actl 1;
BA_ "U_P702_MY2021_Rx" SG_ 1080 DrLatchCntRl_No_Actl 1;
BA_ "U_CX727_MY2021_Rx" SG_ 1080 DrLatchCntRl_No_Actl 1;
BA_ "U_CD764_MY2022_Rx" SG_ 1080 DrLatchCntFr_No_Actl 1;
BA_ "U_U55X_MY2022_Rx" SG_ 1080 DrLatchCntFr_No_Actl 1;
BA_ "U_CD542_MY2021_Rx" SG_ 1080 DrLatchCntFr_No_Actl 1;
BA_ "U_T6_MCA_MY2020_Rx" SG_ 1080 DrLatchCntFr_No_Actl 1;
BA_ "U_P702_MY2021_Rx" SG_ 1080 DrLatchCntFr_No_Actl 1;
BA_ "U_CX727_MY2021_Rx" SG_ 1080 DrLatchCntFr_No_Actl 1;
BA_ "U_CD764_MY2022_Rx" SG_ 1080 DrLatchCntFl_No_Actl 1;
BA_ "U_U55X_MY2022_Rx" SG_ 1080 DrLatchCntFl_No_Actl 1;
BA_ "U_CD542_MY2021_Rx" SG_ 1080 DrLatchCntFl_No_Actl 1;
BA_ "U_T6_MCA_MY2020_Rx" SG_ 1080 DrLatchCntFl_No_Actl 1;
BA_ "U_P702_MY2021_Rx" SG_ 1080 DrLatchCntFl_No_Actl 1;
BA_ "U_CX727_MY2021_Rx" SG_ 1080 DrLatchCntFl_No_Actl 1;
BA_ "U_U55X_MY2022_Rx" SG_ 1080 TurnLghtSwtch_D_Stat2_UB 1;
BA_ "U_U55X_MY2022_Rx" SG_ 1080 TurnLghtSwtch_D_Stat2 1;
BA_ "GenSigSendType" SG_ 1080 TurnLghtSwtch_D_Stat2 3;
BA_ "U_CD764_MY2022_Rx" SG_ 1080 CabnAmb_Te_Actl_UB 1;
BA_ "U_U55X_MY2022_Rx" SG_ 1080 CabnAmb_Te_Actl_UB 1;
BA_ "U_CD542_MY2021_Rx" SG_ 1080 CabnAmb_Te_Actl_UB 1;
BA_ "U_T6_MCA_MY2020_Rx" SG_ 1080 CabnAmb_Te_Actl_UB 1;
BA_ "U_CX727_MY2021_Rx" SG_ 1080 CabnAmb_Te_Actl_UB 1;
BA_ "U_CD764_MY2022_Rx" SG_ 1080 CabnAmb_Te_Actl 1;
BA_ "U_U55X_MY2022_Rx" SG_ 1080 CabnAmb_Te_Actl 1;
BA_ "U_CD542_MY2021_Rx" SG_ 1080 CabnAmb_Te_Actl 1;
BA_ "U_T6_MCA_MY2020_Rx" SG_ 1080 CabnAmb_Te_Actl 1;
BA_ "U_CX727_MY2021_Rx" SG_ 1080 CabnAmb_Te_Actl 1;
BA_ "GenSigStartValueInteger" SG_ 1080 CabnAmb_Te_Actl 114;
BA_ "U_CD764_MY2022_Rx" SG_ 1080 HeadLghtHiPrmsn_D_Stat_UB 1;
BA_ "U_U55X_MY2022_Rx" SG_ 1080 HeadLghtHiPrmsn_D_Stat_UB 1;
BA_ "U_CD542_MY2021_Rx" SG_ 1080 HeadLghtHiPrmsn_D_Stat_UB 1;
BA_ "U_T6_MCA_MY2020_Rx" SG_ 1080 HeadLghtHiPrmsn_D_Stat_UB 1;
BA_ "U_P702_MY2021_Rx" SG_ 1080 HeadLghtHiPrmsn_D_Stat_UB 1;
BA_ "U_CX727_MY2021_Rx" SG_ 1080 HeadLghtHiPrmsn_D_Stat_UB 1;
BA_ "U_CD764_MY2022_Rx" SG_ 1080 HeadLghtHiPrmsn_D_Stat 1;
BA_ "U_U55X_MY2022_Rx" SG_ 1080 HeadLghtHiPrmsn_D_Stat 1;
BA_ "U_CD542_MY2021_Rx" SG_ 1080 HeadLghtHiPrmsn_D_Stat 1;
BA_ "U_T6_MCA_MY2020_Rx" SG_ 1080 HeadLghtHiPrmsn_D_Stat 1;
BA_ "U_P702_MY2021_Rx" SG_ 1080 HeadLghtHiPrmsn_D_Stat 1;
BA_ "U_CX727_MY2021_Rx" SG_ 1080 HeadLghtHiPrmsn_D_Stat 1;
BA_ "GenSigSendType" SG_ 1080 HeadLghtHiPrmsn_D_Stat 3;
BA_ "GenSigStartValue" SG_ 1080 HeadLghtHiPrmsn_D_Stat 3;
BA_ "GenSigStartValueInteger" SG_ 1080 HeadLghtHiPrmsn_D_Stat 3;
BA_ "GenSigSendType" SG_ 1121 OffRdSwtch_D_RqMnu 3;
BA_ "GenSigStartValue" SG_ 1121 OffRdSwtch_D_RqMnu 2;
BA_ "U_U55X_MY2022_Tx" SG_ 1121 SelDrvMdeSwtchOk_D_Stat 1;
BA_ "GenSigSendType" SG_ 1121 SelDrvMdeSwtchOk_D_Stat 3;
BA_ "U_U55X_MY2022_Tx" SG_ 1121 AutoHoldSwtch_D_Stat2 1;
BA_ "U_T6_MCA_MY2020_Tx" SG_ 1121 AutoHoldSwtch_D_Stat2 1;
BA_ "GenSigSendType" SG_ 1121 AutoHoldSwtch_D_Stat2 3;
BA_ "U_U55X_MY2022_Tx" SG_ 1121 PrkAidSwtch_D_RqDrv3 1;
BA_ "U_T6_MCA_MY2020_Tx" SG_ 1121 PrkAidSwtch_D_RqDrv3 1;
BA_ "GenSigSendType" SG_ 1121 PrkAidSwtch_D_RqDrv3 3;
BA_ "U_U55X_MY2022_Tx" SG_ 1121 ApaSwtch_D_RqDrv3 1;
BA_ "U_T6_MCA_MY2020_Tx" SG_ 1121 ApaSwtch_D_RqDrv3 1;
BA_ "GenSigSendType" SG_ 1121 ApaSwtch_D_RqDrv3 3;
BA_ "U_U55X_MY2022_Tx" SG_ 1121 StopStrtDrvMde_B_RqBtn2 1;
BA_ "U_T6_MCA_MY2020_Tx" SG_ 1121 StopStrtDrvMde_B_RqBtn2 1;
BA_ "GenSigSendType" SG_ 1121 StopStrtDrvMde_B_RqBtn2 3;
BA_ "U_U55X_MY2022_Tx" SG_ 1121 SelDrvMdeSwtch_No_Actl 1;
BA_ "U_T6_MCA_MY2020_Tx" SG_ 1121 SelDrvMdeSwtch_No_Actl 1;
BA_ "U_P702_MY2021_Tx" SG_ 1121 SelDrvMdeSwtch_No_Actl 1;
BA_ "GenSigSendType" SG_ 1121 SelDrvMdeSwtch_No_Actl 3;
BA_ "U_U55X_MY2022_Tx" SG_ 1121 SelDrvMdeSwtch_D_Stat 1;
BA_ "U_T6_MCA_MY2020_Tx" SG_ 1121 SelDrvMdeSwtch_D_Stat 1;
BA_ "U_P702_MY2021_Tx" SG_ 1121 SelDrvMdeSwtch_D_Stat 1;
BA_ "GenSigSendType" SG_ 1121 SelDrvMdeSwtch_D_Stat 3;
BA_ "U_U55X_MY2022_Tx" SG_ 1121 SelDrvMdeCnt_D_Stat 1;
BA_ "U_T6_MCA_MY2020_Tx" SG_ 1121 SelDrvMdeCnt_D_Stat 1;
BA_ "U_P702_MY2021_Tx" SG_ 1121 SelDrvMdeCnt_D_Stat 1;
BA_ "GenSigSendType" SG_ 1121 SelDrvMdeCnt_D_Stat 3;
BA_ "U_CD764_MY2022_Tx" SG_ 673 ICI_Coding_BtnID_D 1;
BA_ "U_U55X_MY2022_Tx" SG_ 673 ICI_Coding_BtnID_D 1;
BA_ "U_CD542_MY2021_Tx" SG_ 673 ICI_Coding_BtnID_D 1;
BA_ "U_T6_MCA_MY2020_Tx" SG_ 673 ICI_Coding_BtnID_D 1;
BA_ "U_P702_MY2021_Tx" SG_ 673 ICI_Coding_BtnID_D 1;
BA_ "U_CX727_MY2021_Tx" SG_ 673 ICI_Coding_BtnID_D 1;
BA_ "GenSigSendType" SG_ 673 ICI_Coding_BtnID_D 3;
BA_ "U_CD764_MY2022_Tx" SG_ 673 ICI_Coding_BtnID_C 1;
BA_ "U_U55X_MY2022_Tx" SG_ 673 ICI_Coding_BtnID_C 1;
BA_ "U_CD542_MY2021_Tx" SG_ 673 ICI_Coding_BtnID_C 1;
BA_ "U_T6_MCA_MY2020_Tx" SG_ 673 ICI_Coding_BtnID_C 1;
BA_ "U_P702_MY2021_Tx" SG_ 673 ICI_Coding_BtnID_C 1;
BA_ "U_CX727_MY2021_Tx" SG_ 673 ICI_Coding_BtnID_C 1;
BA_ "GenSigSendType" SG_ 673 ICI_Coding_BtnID_C 3;
BA_ "U_CD764_MY2022_Tx" SG_ 673 ICI_Coding_BtnID_B 1;
BA_ "U_U55X_MY2022_Tx" SG_ 673 ICI_Coding_BtnID_B 1;
BA_ "U_CD542_MY2021_Tx" SG_ 673 ICI_Coding_BtnID_B 1;
BA_ "U_T6_MCA_MY2020_Tx" SG_ 673 ICI_Coding_BtnID_B 1;
BA_ "U_P702_MY2021_Tx" SG_ 673 ICI_Coding_BtnID_B 1;
BA_ "U_CX727_MY2021_Tx" SG_ 673 ICI_Coding_BtnID_B 1;
BA_ "GenSigSendType" SG_ 673 ICI_Coding_BtnID_B 3;
BA_ "U_CD764_MY2022_Tx" SG_ 673 ICI_Coding_BtnID_A 1;
BA_ "U_U55X_MY2022_Tx" SG_ 673 ICI_Coding_BtnID_A 1;
BA_ "U_CD542_MY2021_Tx" SG_ 673 ICI_Coding_BtnID_A 1;
BA_ "U_T6_MCA_MY2020_Tx" SG_ 673 ICI_Coding_BtnID_A 1;
BA_ "U_P702_MY2021_Tx" SG_ 673 ICI_Coding_BtnID_A 1;
BA_ "U_CX727_MY2021_Tx" SG_ 673 ICI_Coding_BtnID_A 1;
BA_ "GenSigSendType" SG_ 673 ICI_Coding_BtnID_A 3;
BA_ "U_CD764_MY2022_Tx" SG_ 673 ICI_BtnID_D 1;
BA_ "U_U55X_MY2022_Tx" SG_ 673 ICI_BtnID_D 1;
BA_ "U_CD542_MY2021_Tx" SG_ 673 ICI_BtnID_D 1;
BA_ "U_T6_MCA_MY2020_Tx" SG_ 673 ICI_BtnID_D 1;
BA_ "U_P702_MY2021_Tx" SG_ 673 ICI_BtnID_D 1;
BA_ "U_CX727_MY2021_Tx" SG_ 673 ICI_BtnID_D 1;
BA_ "GenSigSendType" SG_ 673 ICI_BtnID_D 3;
BA_ "GenSigStartValue" SG_ 673 ICI_BtnID_D 255;
BA_ "GenSigStartValueInteger" SG_ 673 ICI_BtnID_D 255;
BA_ "U_CD764_MY2022_Tx" SG_ 673 ICI_BtnID_C 1;
BA_ "U_U55X_MY2022_Tx" SG_ 673 ICI_BtnID_C 1;
BA_ "U_CD542_MY2021_Tx" SG_ 673 ICI_BtnID_C 1;
BA_ "U_T6_MCA_MY2020_Tx" SG_ 673 ICI_BtnID_C 1;
BA_ "U_P702_MY2021_Tx" SG_ 673 ICI_BtnID_C 1;
BA_ "U_CX727_MY2021_Tx" SG_ 673 ICI_BtnID_C 1;
BA_ "GenSigSendType" SG_ 673 ICI_BtnID_C 3;
BA_ "GenSigStartValue" SG_ 673 ICI_BtnID_C 255;
BA_ "GenSigStartValueInteger" SG_ 673 ICI_BtnID_C 255;
BA_ "U_CD764_MY2022_Tx" SG_ 673 ICI_BtnID_B 1;
BA_ "U_U55X_MY2022_Tx" SG_ 673 ICI_BtnID_B 1;
BA_ "U_CD542_MY2021_Tx" SG_ 673 ICI_BtnID_B 1;
BA_ "U_T6_MCA_MY2020_Tx" SG_ 673 ICI_BtnID_B 1;
BA_ "U_P702_MY2021_Tx" SG_ 673 ICI_BtnID_B 1;
BA_ "U_CX727_MY2021_Tx" SG_ 673 ICI_BtnID_B 1;
BA_ "GenSigSendType" SG_ 673 ICI_BtnID_B 3;
BA_ "GenSigStartValue" SG_ 673 ICI_BtnID_B 255;
BA_ "GenSigStartValueInteger" SG_ 673 ICI_BtnID_B 255;
BA_ "U_CD764_MY2022_Tx" SG_ 673 ICI_BtnID_A 1;
BA_ "U_U55X_MY2022_Tx" SG_ 673 ICI_BtnID_A 1;
BA_ "U_CD542_MY2021_Tx" SG_ 673 ICI_BtnID_A 1;
BA_ "U_T6_MCA_MY2020_Tx" SG_ 673 ICI_BtnID_A 1;
BA_ "U_P702_MY2021_Tx" SG_ 673 ICI_BtnID_A 1;
BA_ "U_CX727_MY2021_Tx" SG_ 673 ICI_BtnID_A 1;
BA_ "GenSigSendType" SG_ 673 ICI_BtnID_A 3;
BA_ "GenSigStartValue" SG_ 673 ICI_BtnID_A 255;
BA_ "GenSigStartValueInteger" SG_ 673 ICI_BtnID_A 255;
BA_ "U_U55X_MY2022_Rx" SG_ 845 SeatMasgPsngr_D_Stat 1;
BA_ "U_U55X_MY2022_Rx" SG_ 845 SeatIntnsPsngr_D_Stat 1;
BA_ "U_U55X_MY2022_Rx" SG_ 845 StmsLmbrPsgr_D_Stat 1;
BA_ "U_P702_MY2021_Rx" SG_ 845 StmsLmbrPsgr_D_Stat 1;
BA_ "U_U55X_MY2022_Rx" SG_ 845 StmsCshnPsgr_D_Stat 1;
BA_ "U_P702_MY2021_Rx" SG_ 845 StmsCshnPsgr_D_Stat 1;
BA_ "U_U55X_MY2022_Rx" SG_ 845 SeatSwtchPsgr_B_Stat 1;
BA_ "U_P702_MY2021_Rx" SG_ 845 SeatSwtchPsgr_B_Stat 1;
BA_ "U_U55X_MY2022_Rx" SG_ 845 SeatPPsgr_B_Stat 1;
BA_ "U_P702_MY2021_Rx" SG_ 845 SeatPPsgr_B_Stat 1;
BA_ "U_U55X_MY2022_Rx" SG_ 845 SeatFnPsgr_D_Stat 1;
BA_ "U_P702_MY2021_Rx" SG_ 845 SeatFnPsgr_D_Stat 1;
BA_ "U_U55X_MY2022_Rx" SG_ 850 SeatCshnPsgrRR_Pc_Actl 1;
BA_ "U_P702_MY2021_Rx" SG_ 850 SeatCshnPsgrRR_Pc_Actl 1;
BA_ "GenSigStartValue" SG_ 850 SeatCshnPsgrRR_Pc_Actl 127;
BA_ "GenSigStartValueInteger" SG_ 850 SeatCshnPsgrRR_Pc_Actl 127;
BA_ "U_U55X_MY2022_Rx" SG_ 850 SeatCshnPsgrRL_Pc_Actl 1;
BA_ "U_P702_MY2021_Rx" SG_ 850 SeatCshnPsgrRL_Pc_Actl 1;
BA_ "GenSigStartValue" SG_ 850 SeatCshnPsgrRL_Pc_Actl 127;
BA_ "GenSigStartValueInteger" SG_ 850 SeatCshnPsgrRL_Pc_Actl 127;
BA_ "U_U55X_MY2022_Rx" SG_ 850 SeatCshnPsgrFR_Pc_Actl 1;
BA_ "U_P702_MY2021_Rx" SG_ 850 SeatCshnPsgrFR_Pc_Actl 1;
BA_ "GenSigStartValue" SG_ 850 SeatCshnPsgrFR_Pc_Actl 127;
BA_ "GenSigStartValueInteger" SG_ 850 SeatCshnPsgrFR_Pc_Actl 127;
BA_ "U_U55X_MY2022_Rx" SG_ 850 SeatCshnPsgrFL_Pc_Actl 1;
BA_ "U_P702_MY2021_Rx" SG_ 850 SeatCshnPsgrFL_Pc_Actl 1;
BA_ "GenSigStartValue" SG_ 850 SeatCshnPsgrFL_Pc_Actl 127;
BA_ "GenSigStartValueInteger" SG_ 850 SeatCshnPsgrFL_Pc_Actl 127;
BA_ "U_U55X_MY2022_Rx" SG_ 850 SeatBlLoPsgr_Pc_Actl2 1;
BA_ "U_P702_MY2021_Rx" SG_ 850 SeatBlLoPsgr_Pc_Actl2 1;
BA_ "GenSigStartValue" SG_ 850 SeatBlLoPsgr_Pc_Actl2 127;
BA_ "GenSigStartValueInteger" SG_ 850 SeatBlLoPsgr_Pc_Actl2 127;
BA_ "GenSigSendType" SG_ 820 TurnLampFrOut_B_Stat 3;
BA_ "GenSigSendType" SG_ 820 TurnLampFlOut_B_Stat 3;
BA_ "U_CD542_MY2021_Tx" SG_ 820 AhbStatGfhbFdbk_D_Actl 1;
BA_ "U_T6_MCA_MY2020_Tx" SG_ 820 AhbStatGfhbFdbk_D_Actl 1;
BA_ "U_P702_MY2021_Tx" SG_ 820 AhbStatGfhbFdbk_D_Actl 1;
BA_ "U_CX727_MY2021_Tx" SG_ 820 AhbStatGfhbFdbk_D_Actl 1;
BA_ "U_CD764_MY2022_Rx" SG_ 820 AhbStatGfhbFdbk_D_Actl 1;
BA_ "U_U55X_MY2022_Rx" SG_ 820 AhbStatGfhbFdbk_D_Actl 1;
BA_ "U_CD542_MY2021_Rx" SG_ 820 AhbStatGfhbFdbk_D_Actl 1;
BA_ "U_T6_MCA_MY2020_Rx" SG_ 820 AhbStatGfhbFdbk_D_Actl 1;
BA_ "U_P702_MY2021_Rx" SG_ 820 AhbStatGfhbFdbk_D_Actl 1;
BA_ "U_CX727_MY2021_Rx" SG_ 820 AhbStatGfhbFdbk_D_Actl 1;
BA_ "GenSigSendType" SG_ 820 AhbStatGfhbFdbk_D_Actl 3;
BA_ "U_CD542_MY2021_Tx" SG_ 820 HeadLghtDrvSide_B_Stat 1;
BA_ "U_T6_MCA_MY2020_Tx" SG_ 820 HeadLghtDrvSide_B_Stat 1;
BA_ "U_P702_MY2021_Tx" SG_ 820 HeadLghtDrvSide_B_Stat 1;
BA_ "U_CX727_MY2021_Tx" SG_ 820 HeadLghtDrvSide_B_Stat 1;
BA_ "GenSigSendType" SG_ 820 HeadLghtDrvSide_B_Stat 3;
BA_ "U_CD542_MY2021_Tx" SG_ 820 HeadLghtHiOn_B_StatHcm 1;
BA_ "U_T6_MCA_MY2020_Tx" SG_ 820 HeadLghtHiOn_B_StatHcm 1;
BA_ "U_P702_MY2021_Tx" SG_ 820 HeadLghtHiOn_B_StatHcm 1;
BA_ "U_CX727_MY2021_Tx" SG_ 820 HeadLghtHiOn_B_StatHcm 1;
BA_ "GenSigSendType" SG_ 820 HeadLghtHiOn_B_StatHcm 3;
BA_ "U_CD542_MY2021_Tx" SG_ 820 Adaptive_Hdlmp_Fault 1;
BA_ "U_T6_MCA_MY2020_Tx" SG_ 820 Adaptive_Hdlmp_Fault 1;
BA_ "U_P702_MY2021_Tx" SG_ 820 Adaptive_Hdlmp_Fault 1;
BA_ "U_CX727_MY2021_Tx" SG_ 820 Adaptive_Hdlmp_Fault 1;
BA_ "GenSigSendType" SG_ 820 Adaptive_Hdlmp_Fault 3;
BA_ "GenSigStartValue" SG_ 935 Side_Detect_R_Illum 100;
BA_ "GenSigStartValueInteger" SG_ 935 Side_Detect_R_Illum 100;
BA_ "GenSigStartValue" SG_ 935 SodRight_D_Stat 2;
BA_ "GenSigStartValueInteger" SG_ 935 SodRight_D_Stat 2;
BA_ "GenSigStartValue" SG_ 935 SodWarnRight_Prd_Rq 14;
BA_ "GenSigStartValueInteger" SG_ 935 SodWarnRight_Prd_Rq 14;
BA_ "GenSigStartValue" SG_ 934 Side_Detect_L_Illum 100;
BA_ "GenSigStartValueInteger" SG_ 934 Side_Detect_L_Illum 100;
BA_ "GenSigStartValue" SG_ 934 SodLeft_D_Stat 2;
BA_ "GenSigStartValueInteger" SG_ 934 SodLeft_D_Stat 2;
BA_ "GenSigStartValue" SG_ 934 SodWarnLeft_Prd_Rq 14;
BA_ "GenSigStartValueInteger" SG_ 934 SodWarnLeft_Prd_Rq 14;
BA_ "GenSigSendType" SG_ 1073 CamraFrntBttn_D_Stat 3;
BA_ "GenSigSendType" SG_ 1073 BrkDrvMde_D_Rq 3;
BA_ "GenSigSendType" SG_ 1073 SteEffort_D_Rq 3;
BA_ "GenSigSendType" SG_ 1073 AutoHoldSwtch_D_Stat 3;
BA_ "U_CD764_MY2022_Rx" SG_ 1073 HMI_HMIMode_St_UB 1;
BA_ "U_U55X_MY2022_Rx" SG_ 1073 HMI_HMIMode_St_UB 1;
BA_ "U_CD542_MY2021_Rx" SG_ 1073 HMI_HMIMode_St_UB 1;
BA_ "U_T6_MCA_MY2020_Rx" SG_ 1073 HMI_HMIMode_St_UB 1;
BA_ "U_P702_MY2021_Rx" SG_ 1073 HMI_HMIMode_St_UB 1;
BA_ "U_CX727_MY2021_Rx" SG_ 1073 HMI_HMIMode_St_UB 1;
BA_ "U_CD764_MY2022_Rx" SG_ 1073 HMI_HMIMode_St 1;
BA_ "U_U55X_MY2022_Rx" SG_ 1073 HMI_HMIMode_St 1;
BA_ "U_CD542_MY2021_Rx" SG_ 1073 HMI_HMIMode_St 1;
BA_ "U_T6_MCA_MY2020_Rx" SG_ 1073 HMI_HMIMode_St 1;
BA_ "U_P702_MY2021_Rx" SG_ 1073 HMI_HMIMode_St 1;
BA_ "U_CX727_MY2021_Rx" SG_ 1073 HMI_HMIMode_St 1;
BA_ "GenSigSendType" SG_ 1073 HMI_HMIMode_St 3;
BA_ "WakeupSignal" SG_ 1073 HMI_HMIMode_St 1;
BA_ "U_CD764_MY2022_Rx" SG_ 1073 Veh_Lock_Requestor_UB 1;
BA_ "U_U55X_MY2022_Rx" SG_ 1073 Veh_Lock_Requestor_UB 1;
BA_ "U_CD542_MY2021_Rx" SG_ 1073 Veh_Lock_Requestor_UB 1;
BA_ "U_T6_MCA_MY2020_Rx" SG_ 1073 Veh_Lock_Requestor_UB 1;
BA_ "U_P702_MY2021_Rx" SG_ 1073 Veh_Lock_Requestor_UB 1;
BA_ "U_CX727_MY2021_Rx" SG_ 1073 Veh_Lock_Requestor_UB 1;
BA_ "U_CD764_MY2022_Rx" SG_ 1073 Veh_Lock_EvNum_UB 1;
BA_ "U_U55X_MY2022_Rx" SG_ 1073 Veh_Lock_EvNum_UB 1;
BA_ "U_CD542_MY2021_Rx" SG_ 1073 Veh_Lock_EvNum_UB 1;
BA_ "U_T6_MCA_MY2020_Rx" SG_ 1073 Veh_Lock_EvNum_UB 1;
BA_ "U_P702_MY2021_Rx" SG_ 1073 Veh_Lock_EvNum_UB 1;
BA_ "U_CX727_MY2021_Rx" SG_ 1073 Veh_Lock_EvNum_UB 1;
BA_ "U_CD764_MY2022_Rx" SG_ 1073 Veh_Lock_Status_UB 1;
BA_ "U_U55X_MY2022_Rx" SG_ 1073 Veh_Lock_Status_UB 1;
BA_ "U_CD542_MY2021_Rx" SG_ 1073 Veh_Lock_Status_UB 1;
BA_ "U_T6_MCA_MY2020_Rx" SG_ 1073 Veh_Lock_Status_UB 1;
BA_ "U_P702_MY2021_Rx" SG_ 1073 Veh_Lock_Status_UB 1;
BA_ "U_CX727_MY2021_Rx" SG_ 1073 Veh_Lock_Status_UB 1;
BA_ "GenSigSendType" SG_ 1073 Veh_Lock_Sub_Id 3;
BA_ "U_CD764_MY2022_Rx" SG_ 1073 Veh_Lock_Status 1;
BA_ "U_U55X_MY2022_Rx" SG_ 1073 Veh_Lock_Status 1;
BA_ "U_CD542_MY2021_Rx" SG_ 1073 Veh_Lock_Status 1;
BA_ "U_T6_MCA_MY2020_Rx" SG_ 1073 Veh_Lock_Status 1;
BA_ "U_P702_MY2021_Rx" SG_ 1073 Veh_Lock_Status 1;
BA_ "U_CX727_MY2021_Rx" SG_ 1073 Veh_Lock_Status 1;
BA_ "GenSigSendType" SG_ 1073 Veh_Lock_Status 3;
BA_ "GenSigStartValue" SG_ 1073 Veh_Lock_Status 1;
BA_ "GenSigStartValueInteger" SG_ 1073 Veh_Lock_Status 1;
BA_ "WakeupSignal" SG_ 1073 Veh_Lock_Status 1;
BA_ "U_CD764_MY2022_Rx" SG_ 1073 Veh_Lock_Requestor 1;
BA_ "U_U55X_MY2022_Rx" SG_ 1073 Veh_Lock_Requestor 1;
BA_ "U_CD542_MY2021_Rx" SG_ 1073 Veh_Lock_Requestor 1;
BA_ "U_T6_MCA_MY2020_Rx" SG_ 1073 Veh_Lock_Requestor 1;
BA_ "U_P702_MY2021_Rx" SG_ 1073 Veh_Lock_Requestor 1;
BA_ "U_CX727_MY2021_Rx" SG_ 1073 Veh_Lock_Requestor 1;
BA_ "GenSigSendType" SG_ 1073 Veh_Lock_Requestor 3;
BA_ "WakeupSignal" SG_ 1073 Veh_Lock_Requestor 1;
BA_ "U_CD764_MY2022_Rx" SG_ 1073 Veh_Lock_EvNum 1;
BA_ "U_U55X_MY2022_Rx" SG_ 1073 Veh_Lock_EvNum 1;
BA_ "U_CD542_MY2021_Rx" SG_ 1073 Veh_Lock_EvNum 1;
BA_ "U_T6_MCA_MY2020_Rx" SG_ 1073 Veh_Lock_EvNum 1;
BA_ "U_P702_MY2021_Rx" SG_ 1073 Veh_Lock_EvNum 1;
BA_ "U_CX727_MY2021_Rx" SG_ 1073 Veh_Lock_EvNum 1;
BA_ "GenSigSendType" SG_ 1073 Veh_Lock_EvNum 3;
BA_ "WakeupSignal" SG_ 1073 Veh_Lock_EvNum 1;
BA_ "GenSigSendType" SG_ 1073 Tire_Press_System_Stat 3;
BA_ "GenSigSendType" SG_ 1073 DISPLAY_SPEED_OFFSET 3;
BA_ "GenSigSendType" SG_ 1073 DISPLAY_SPEED_SCALING 3;
BA_ "U_CD764_MY2022_Rx" SG_ 1073 Foh_D_Stat 1;
BA_ "U_U55X_MY2022_Rx" SG_ 1073 Foh_D_Stat 1;
BA_ "U_CD542_MY2021_Rx" SG_ 1073 Foh_D_Stat 1;
BA_ "U_T6_MCA_MY2020_Rx" SG_ 1073 Foh_D_Stat 1;
BA_ "U_P702_MY2021_Rx" SG_ 1073 Foh_D_Stat 1;
BA_ "GenSigSendType" SG_ 1073 Foh_D_Stat 3;
BA_ "ContentDependant" SG_ 1073 Foh_D_Stat 1;
BA_ "WakeupSignal" SG_ 1073 Foh_D_Stat 1;
BA_ "U_CD764_MY2022_Rx" SG_ 1073 Foh_D_Stat_UB 1;
BA_ "U_U55X_MY2022_Rx" SG_ 1073 Foh_D_Stat_UB 1;
BA_ "U_CD542_MY2021_Rx" SG_ 1073 Foh_D_Stat_UB 1;
BA_ "U_T6_MCA_MY2020_Rx" SG_ 1073 Foh_D_Stat_UB 1;
BA_ "U_P702_MY2021_Rx" SG_ 1073 Foh_D_Stat_UB 1;
BA_ "U_CD764_MY2022_Rx" SG_ 1073 SteWhlHeat_D_Rq_UB 1;
BA_ "U_U55X_MY2022_Rx" SG_ 1073 SteWhlHeat_D_Rq_UB 1;
BA_ "U_CD542_MY2021_Rx" SG_ 1073 SteWhlHeat_D_Rq_UB 1;
BA_ "U_T6_MCA_MY2020_Rx" SG_ 1073 SteWhlHeat_D_Rq_UB 1;
BA_ "U_CX727_MY2021_Rx" SG_ 1073 SteWhlHeat_D_Rq_UB 1;
BA_ "U_P702_MY2021_Rx" SG_ 1073 SteWhlHeat_D_Rq_UB 1;
BA_ "U_CD764_MY2022_Rx" SG_ 1073 SteWhlHeat_D_Rq 1;
BA_ "U_U55X_MY2022_Rx" SG_ 1073 SteWhlHeat_D_Rq 1;
BA_ "U_CD542_MY2021_Rx" SG_ 1073 SteWhlHeat_D_Rq 1;
BA_ "U_T6_MCA_MY2020_Rx" SG_ 1073 SteWhlHeat_D_Rq 1;
BA_ "U_CX727_MY2021_Rx" SG_ 1073 SteWhlHeat_D_Rq 1;
BA_ "U_P702_MY2021_Rx" SG_ 1073 SteWhlHeat_D_Rq 1;
BA_ "GenSigSendType" SG_ 1073 SteWhlHeat_D_Rq 3;
BA_ "GenSigSendType" SG_ 1876 TesterPhysicalReqTCU 3;
BA_ "GenSigSendType" SG_ 973 PersCtaSplitView_D_Stat 3;
BA_ "GenSigSendType" SG_ 973 LaSysOffStat_D_Dsply 3;
BA_ "GenSigSendType" SG_ 973 TsrVl2PrmntMsgTxt_D_Rq 3;
BA_ "GenSigSendType" SG_ 973 TsrVl1PrmntMsgTxt_D_Rq 3;
BA_ "GenSigSendType" SG_ 973 TsrVl2RstrcMsgTxt2_D_Rq 3;
BA_ "GenSigStartValue" SG_ 973 TsrVl2RstrcMsgTxt2_D_Rq 1;
BA_ "GenSigStartValueInteger" SG_ 973 TsrVl2RstrcMsgTxt2_D_Rq 1;
BA_ "GenSigSendType" SG_ 973 TsrVl1RstrcMsgTxt2_D_Rq 3;
BA_ "GenSigStartValue" SG_ 973 TsrVl1RstrcMsgTxt2_D_Rq 1;
BA_ "GenSigStartValueInteger" SG_ 973 TsrVl1RstrcMsgTxt2_D_Rq 1;
BA_ "GenSigSendType" SG_ 973 TsrOvtkMsgTxt2_D_Rq 3;
BA_ "GenSigSendType" SG_ 973 WwaWarn_B_Rq 3;
BA_ "GenSigSendType" SG_ 973 TsrVlUnitMsgTxt_D_Rq 3;
BA_ "GenSigStartValue" SG_ 973 TsrVlUnitMsgTxt_D_Rq 2;
BA_ "GenSigStartValueInteger" SG_ 973 TsrVlUnitMsgTxt_D_Rq 2;
BA_ "GenSigSendType" SG_ 973 TsrVLim2MsgTxt_D_Rq 3;
BA_ "GenSigStartValue" SG_ 973 TsrVLim2MsgTxt_D_Rq 255;
BA_ "GenSigStartValueInteger" SG_ 973 TsrVLim2MsgTxt_D_Rq 255;
BA_ "GenSigSendType" SG_ 973 TsrVLim1MsgTxt_D_Rq 3;
BA_ "GenSigStartValue" SG_ 973 TsrVLim1MsgTxt_D_Rq 255;
BA_ "GenSigStartValueInteger" SG_ 973 TsrVLim1MsgTxt_D_Rq 255;
BA_ "GenSigSendType" SG_ 973 TsrVl2StatMsgTxt_D_Rq 3;
BA_ "GenSigSendType" SG_ 973 TsrVl2RstrcMsgTxt_D_Rq 3;
BA_ "GenSigSendType" SG_ 973 TsrVl1StatMsgTxt_D_Rq 3;
BA_ "GenSigSendType" SG_ 973 TsrVl1RstrcMsgTxt_D_Rq 3;
BA_ "GenSigSendType" SG_ 973 TsrStatMsgTxt_D_Rq 3;
BA_ "GenSigSendType" SG_ 973 TsrOvtkStatMsgTxt_D_Rq 3;
BA_ "GenSigSendType" SG_ 973 TsrOvtkMsgTxt_D_Rq 3;
BA_ "GenSigStartValue" SG_ 973 TsrOvtkMsgTxt_D_Rq 1;
BA_ "GenSigStartValueInteger" SG_ 973 TsrOvtkMsgTxt_D_Rq 1;
BA_ "GenSigSendType" SG_ 973 TsrOswWarnMsgTxt_D_Rq 3;
BA_ "GenSigStartValue" SG_ 973 TsrOswWarnMsgTxt_D_Rq 1;
BA_ "GenSigStartValueInteger" SG_ 973 TsrOswWarnMsgTxt_D_Rq 1;
BA_ "GenSigSendType" SG_ 973 TsrMsgTxt_D_Rq 3;
BA_ "GenSigStartValue" SG_ 973 TsrMsgTxt_D_Rq 1;
BA_ "GenSigStartValueInteger" SG_ 973 TsrMsgTxt_D_Rq 1;
BA_ "MetaData" SG_ 837 SuspVLimBRq_No_Cs 1;
BA_ "MetaData" SG_ 837 SuspVLimBRq_No_Cnt 1;
BA_ "GenSigSendType" SG_ 837 VdmSustnActv_B_Rq 3;
BA_ "GenSigStartValue" SG_ 837 VehCurb_M_Actl 1022;
BA_ "GenSigSendType" SG_ 837 Ccd_B_Falt 3;
BA_ "GenSigSendType" SG_ 837 SuspVLim_B_Rq 3;
BA_ "GenSigSendType" SG_ 837 SelDrvMdeSusp_D_Stat 3;
BA_ "GenSigSendType" SG_ 837 AdptDrvMdePt_D_Rq 3;
BA_ "GenSigSendType" SG_ 837 AdptDrvMdeChassis_D_Rq 3;
BA_ "GenSigSendType" SG_ 837 AirSprngRateRr_D_Rq 3;
BA_ "GenSigSendType" SG_ 837 AirSprngRateRl_D_Rq 3;
BA_ "GenSigSendType" SG_ 837 SuspType_B_Stat 3;
BA_ "GenSigSendType" SG_ 837 AirSprngRateFr_D_Rq 3;
BA_ "GenSigSendType" SG_ 837 AirSprngRateFl_D_Rq 3;
BA_ "GenSigStartValue" SG_ 837 VehGvwr_M_Actl 1022;
BA_ "GenSigSendType" SG_ 837 AirSusp_D_Stat 3;
BA_ "GenSigSendType" SG_ 837 AirSuspMsgTxt_D_Rq 3;
BA_ "GenSigSendType" SG_ 837 SuspDrvMde_D_Stat 3;
BA_ "GenSigSendType" SG_ 837 CcdMsgTxt_D_RqDsply 3;
VAL_ 1114 TrlBrkInitOut_D_Rq 3 "Heavy" 2 "Medium" 1 "Light" 0 "Null" ;
VAL_ 1114 TrailCtlSwtch_B_Stat2 1 "Pressed" 0 "Not_Pressed" ;
VAL_ 939 PrkAidSnsRlSide_D_Stat 15 "Zone_15" 14 "Zone_14" 13 "Zone_13" 12 "Zone_12" 11 "Zone_11" 10 "Zone_10" 9 "Zone_9" 8 "Zone_8" 7 "Zone_7" 6 "Zone_6" 5 "Zone_5" 4 "Zone_4" 3 "Zone_3" 2 "Zone_2" 1 "Zone_1" 0 "Off" ;
VAL_ 939 ApaBrk_D_Rq 3 "NotUsed" 2 "LowDecel" 1 "HighDecel" 0 "NoRequest" ;
VAL_ 939 SidePrkSnsR4_D_Stat 15 "NotUsed" 14 "NotFullyScannedYet" 13 "NoObjectInSector" 12 "Zone12" 11 "Zone11" 10 "Zone10" 9 "Zone9" 8 "Zone8" 7 "Zone7" 6 "Zone6" 5 "Zone5" 4 "Zone4" 3 "Zone3" 2 "Zone2" 1 "Zone1" 0 "Off" ;
VAL_ 939 SidePrkSnsR3_D_Stat 15 "NotUsed" 14 "NotFullyScannedYet" 13 "NoObjectInSector" 12 "Zone12" 11 "Zone11" 10 "Zone10" 9 "Zone9" 8 "Zone8" 7 "Zone7" 6 "Zone6" 5 "Zone5" 4 "Zone4" 3 "Zone3" 2 "Zone2" 1 "Zone1" 0 "Off" ;
VAL_ 939 SidePrkSnsL4_D_Stat 15 "NotUsed" 14 "NotFullyScannedYet" 13 "NoObjectInSector" 12 "Zone12" 11 "Zone11" 10 "Zone10" 9 "Zone9" 8 "Zone8" 7 "Zone7" 6 "Zone6" 5 "Zone5" 4 "Zone4" 3 "Zone3" 2 "Zone2" 1 "Zone1" 0 "Off" ;
VAL_ 939 SidePrkSnsL3_D_Stat 15 "NotUsed" 14 "NotFullyScannedYet" 13 "NoObjectInSector" 12 "Zone12" 11 "Zone11" 10 "Zone10" 9 "Zone9" 8 "Zone8" 7 "Zone7" 6 "Zone6" 5 "Zone5" 4 "Zone4" 3 "Zone3" 2 "Zone2" 1 "Zone1" 0 "Off" ;
VAL_ 939 PrkAidChime_D_Stat 3 "Fault" 2 "No_Data_Exists" 1 "On" 0 "Off" ;
VAL_ 939 PrkAidSnsRlCntr_D_Stat 15 "Zone_15" 14 "Zone_14" 13 "Zone_13" 12 "Zone_12" 11 "Zone_11" 10 "Zone_10" 9 "Zone_9" 8 "Zone_8" 7 "Zone_7" 6 "Zone_6" 5 "Zone_5" 4 "Zone_4" 3 "Zone_3" 2 "Zone_2" 1 "Zone_1" 0 "Off" ;
VAL_ 939 PrkAidSnsRrCrnr_D_Stat 15 "Zone_15" 14 "Zone_14" 13 "Zone_13" 12 "Zone_12" 11 "Zone_11" 10 "Zone_10" 9 "Zone_9" 8 "Zone_8" 7 "Zone_7" 6 "Zone_6" 5 "Zone_5" 4 "Zone_4" 3 "Zone_3" 2 "Zone_2" 1 "Zone_1" 0 "Off" ;
VAL_ 939 PrkAidSnsRrCntr_D_Stat 15 "Zone_15" 14 "Zone_14" 13 "Zone_13" 12 "Zone_12" 11 "Zone_11" 10 "Zone_10" 9 "Zone_9" 8 "Zone_8" 7 "Zone_7" 6 "Zone_6" 5 "Zone_5" 4 "Zone_4" 3 "Zone_3" 2 "Zone_2" 1 "Zone_1" 0 "Off" ;
VAL_ 939 PrkAidSnsRlCrnr_D_Stat 15 "Zone_15" 14 "Zone_14" 13 "Zone_13" 12 "Zone_12" 11 "Zone_11" 10 "Zone_10" 9 "Zone_9" 8 "Zone_8" 7 "Zone_7" 6 "Zone_6" 5 "Zone_5" 4 "Zone_4" 3 "Zone_3" 2 "Zone_2" 1 "Zone_1" 0 "Off" ;
VAL_ 939 PrkAidRear_D_Stat 3 "Faulted" 2 "Unused" 1 "Enabled" 0 "Disabled" ;
VAL_ 939 PrkAidFront_D_Stat 3 "Faulted" 2 "Unused" 1 "Enabled" 0 "Disabled" ;
VAL_ 939 PrkAid_D_Falt 7 "NotUsed2" 6 "NotUsed1" 5 "Failure_Front_PSM_Sensors" 4 "No_Data_Exists" 3 "Failure_Rear_Sensors" 2 "Speaker_Fault" 1 "ECU_Fault" 0 "No_Fault" ;
VAL_ 939 PrkAidSnsRrSide_D_Stat 15 "Zone_15" 14 "Zone_14" 13 "Zone_13" 12 "Zone_12" 11 "Zone_11" 10 "Zone_10" 9 "Zone_9" 8 "Zone_8" 7 "Zone_7" 6 "Zone_6" 5 "Zone_5" 4 "Zone_4" 3 "Zone_3" 2 "Zone_2" 1 "Zone_1" 0 "Off" ;
VAL_ 939 PrkAidLamp_D_Rq 3 "Not_Used" 2 "Flash" 1 "On" 0 "Off" ;
VAL_ 939 ApaLongCtrlEnbl_D_Rq 1 "Enable" 0 "Disable" ;
VAL_ 938 SidePrkSnsR2_D_Stat 15 "NotUsed" 14 "NotFullyScannedYet" 13 "NoObjectInSector" 12 "Zone12" 11 "Zone11" 10 "Zone10" 9 "Zone9" 8 "Zone8" 7 "Zone7" 6 "Zone6" 5 "Zone5" 4 "Zone4" 3 "Zone3" 2 "Zone2" 1 "Zone1" 0 "Off" ;
VAL_ 938 SidePrkSnsR1_D_Stat 15 "NotUsed" 14 "NotFullyScannedYet" 13 "NoObjectInSector" 12 "Zone12" 11 "Zone11" 10 "Zone10" 9 "Zone9" 8 "Zone8" 7 "Zone7" 6 "Zone6" 5 "Zone5" 4 "Zone4" 3 "Zone3" 2 "Zone2" 1 "Zone1" 0 "Off" ;
VAL_ 938 SidePrkSnsL2_D_Stat 15 "NotUsed" 14 "NotFullyScannedYet" 13 "NoObjectInSector" 12 "Zone12" 11 "Zone11" 10 "Zone10" 9 "Zone9" 8 "Zone8" 7 "Zone7" 6 "Zone6" 5 "Zone5" 4 "Zone4" 3 "Zone3" 2 "Zone2" 1 "Zone1" 0 "Off" ;
VAL_ 938 SidePrkSnsL1_D_Stat 15 "NotUsed" 14 "NotFullyScannedYet" 13 "NoObjectInSector" 12 "Zone12" 11 "Zone11" 10 "Zone10" 9 "Zone9" 8 "Zone8" 7 "Zone7" 6 "Zone6" 5 "Zone5" 4 "Zone4" 3 "Zone3" 2 "Zone2" 1 "Zone1" 0 "Off" ;
VAL_ 938 ApaMde_D_Stat 7 "NotUsed" 6 "RePA" 5 "ParkIn" 4 "POA" 3 "PPA" 2 "SAPP" 1 "Off" 0 "Null" ;
VAL_ 938 ApaActvSd_D_Actl 3 "Dirver_Side" 2 "Passenger_Side" 1 "No_Side" 0 "Null" ;
VAL_ 938 PrkAidSwtch_B_Stat 1 "Pressed" 0 "Not_Pressed" ;
VAL_ 938 ApaMde_D_Avail 15 "NotUsed7" 14 "NotUsed6" 13 "NotUsed5" 12 "NotUsed4" 11 "NotUsed3" 10 "NotUsed2" 9 "NotUsed1" 8 "PPA_POA" 7 "SAPP_POA" 6 "POA" 5 "PPA" 4 "SAPP" 3 "SAPP_PPA_POA" 2 "SAPP_PPA" 1 "None" 0 "Null" ;
VAL_ 938 PrkAidSnsFrSide_D_Stat 15 "Zone_15" 14 "Zone_14" 13 "Zone_13" 12 "Zone_12" 11 "Zone_11" 10 "Zone_10" 9 "Zone_9" 8 "Zone_8" 7 "Zone_7" 6 "Zone_6" 5 "Zone_5" 4 "Zone_4" 3 "Zone_3" 2 "Zone_2" 1 "Zone_1" 0 "Off" ;
VAL_ 938 PrkAidSnsFrCrnr_D_Stat 15 "Zone_15" 14 "Zone_14" 13 "Zone_13" 12 "Zone_12" 11 "Zone_11" 10 "Zone_10" 9 "Zone_9" 8 "Zone_8" 7 "Zone_7" 6 "Zone_6" 5 "Zone_5" 4 "Zone_4" 3 "Zone_3" 2 "Zone_2" 1 "Zone_1" 0 "Off" ;
VAL_ 938 PrkAidSnsFrCntr_D_Stat 15 "Zone_15" 14 "Zone_14" 13 "Zone_13" 12 "Zone_12" 11 "Zone_11" 10 "Zone_10" 9 "Zone_9" 8 "Zone_8" 7 "Zone_7" 6 "Zone_6" 5 "Zone_5" 4 "Zone_4" 3 "Zone_3" 2 "Zone_2" 1 "Zone_1" 0 "Off" ;
VAL_ 938 PrkAidSnsFlSide_D_Stat 15 "Zone_15" 14 "Zone_14" 13 "Zone_13" 12 "Zone_12" 11 "Zone_11" 10 "Zone_10" 9 "Zone_9" 8 "Zone_8" 7 "Zone_7" 6 "Zone_6" 5 "Zone_5" 4 "Zone_4" 3 "Zone_3" 2 "Zone_2" 1 "Zone_1" 0 "Off" ;
VAL_ 938 PrkAidSnsFlCrnr_D_Stat 15 "Zone_15" 14 "Zone_14" 13 "Zone_13" 12 "Zone_12" 11 "Zone_11" 10 "Zone_10" 9 "Zone_9" 8 "Zone_8" 7 "Zone_7" 6 "Zone_6" 5 "Zone_5" 4 "Zone_4" 3 "Zone_3" 2 "Zone_2" 1 "Zone_1" 0 "Off" ;
VAL_ 938 PrkAidSnsFlCntr_D_Stat 15 "Zone_15" 14 "Zone_14" 13 "Zone_13" 12 "Zone_12" 11 "Zone_11" 10 "Zone_10" 9 "Zone_9" 8 "Zone_8" 7 "Zone_7" 6 "Zone_6" 5 "Zone_5" 4 "Zone_4" 3 "Zone_3" 2 "Zone_2" 1 "Zone_1" 0 "Off" ;
VAL_ 938 RpaChime_D_Rq 15 "Zone15_Chime" 14 "Zone14_Chime" 13 "Zone13_Chime" 12 "Zone12_Chime" 11 "Zone11_Chime" 10 "Zone10_Chime" 9 "Zone9_Chime" 8 "Zone8_Chime" 7 "Zone7_Chime" 6 "Zone6_Chime" 5 "Zone5_Chime" 4 "Zone4_Chime" 3 "Zone3_Chime" 2 "Zone2_Chime" 1 "Zone1_Chime" 0 "No_Chime" ;
VAL_ 938 FpaChime_D_Rq 15 "Zone15_Chime" 14 "Zone14_Chime" 13 "Zone13_Chime" 12 "Zone12_Chime" 11 "Zone11_Chime" 10 "Zone10_Chime" 9 "Zone9_Chime" 8 "Zone8_Chime" 7 "Zone7_Chime" 6 "Zone6_Chime" 5 "Zone5_Chime" 4 "Zone4_Chime" 3 "Zone3_Chime" 2 "Zone2_Chime" 1 "Zone1_Chime" 0 "No_Chime" ;
VAL_ 938 PrkAidMsgTxt_D_Rq 15 "All_Sns_Blk" 14 "R_Sns_ON_F_Sns_Blk" 13 "R_Sns_Blk_F_Sns_ON" 12 "R_Sns_Inactive_Trlr_atch" 11 "Not_Avail_Trlr_attchd" 10 "Fail_Mode_no_Chime" 9 "Fail_Mode_with_Chime" 8 "R_Sns_Trlr_F_Sns_Blk" 7 "NotUsed3" 6 "Park_Sys_Alternate_Mode" 5 "R_Snsrs_On_F_Snsrs_On" 4 "NotUsed2" 3 "Reset_Message_Warn" 2 "R_Snsrs_Off_F_Snsrs_On" 1 "R_Snsrs_On_F_Snsrs_Off" 0 "All_Park_Sensors_Off" ;
VAL_ 938 PrkAidAudioMute_B_Rq 1 "Enable" 0 "Disable" ;
VAL_ 938 PrkBrkEl_B_RqFap 1 "Yes" 0 "No" ;
VAL_ 863 SteWhlHeat_D_Stat 15 "NotUsed6" 14 "NotUsed5" 13 "NotUsed4" 12 "NotUsed3" 11 "NotUsed2" 10 "NotUsed1" 9 "Reserved_3" 8 "Reserved_2" 7 "Reserved_1" 6 "Level_3_Heating" 5 "Level_3_Heating_LS" 4 "Level_2_Heating" 3 "Level_2_Heating_LS" 2 "Level_1_Heating" 1 "Level_1_Heating_LS" 0 "Off" ;
VAL_ 981 AdbBrdrTop_An_Rq 255 "Faulty" 254 "NoDataExists" ;
VAL_ 981 AdbBrdrRight_L_Stat 511 "Faulty" 510 "NoDataExists" ;
VAL_ 981 AdbBrdrRight_An_Rq 1023 "Faulty" 1022 "NoDataExists" ;
VAL_ 981 AdbBrdrLeft_L_Stat 511 "Faulty" 510 "NoDataExists" ;
VAL_ 981 AdbBrdrLeft_An_Rq 1023 "Faulty" 1022 "NoDataExists" ;
VAL_ 981 AdbBrdrBottom_An_Rq 63 "Faulty" 62 "NoDataExists" ;
VAL_ 981 AdbBeam_D_Rq 7 "NotUsed_3" 6 "NotUsed_2" 5 "NotUsed_1" 4 "FullHighBeam" 3 "Spot_BothSide" 2 "Spot_OnlyRightSide" 1 "Spot_OnlyLeftSide" 0 "NoHighBeam" ;
VAL_ 1124 GPS_Vdop 31 "Invalid" 30 "Unknown" ;
VAL_ 1124 GPS_Speed 255 "Invalid" 254 "Unknown" ;
VAL_ 1124 GPS_Sat_num_in_view 31 "Invalid" 30 "Unknown" ;
VAL_ 1124 GPS_MSL_altitude 4095 "Fault" 4094 "Unknown" ;
VAL_ 1124 GPS_Heading 65535 "Fault" 65534 "Unknown" ;
VAL_ 1124 GPS_Hdop 31 "Invalid" 30 "Unknown" ;
VAL_ 1124 GPS_dimension 2 "_3D" 1 "_2D" 0 "No_Fix" ;
VAL_ 1105 TrlrRvrseEnbl_D2_Stat 7 "NotUsed" 6 "TbaActiveExpertActive" 5 "TbaActiveExpertAvail" 4 "TbaOffTrgActive" 3 "TbaOffTrgSetup" 2 "TbaSetup" 1 "TbaActive" 0 "Inactive" ;
VAL_ 1105 TrlrRvrseMsgTxt_D2_Rq 31 "Message31" 30 "Message30" 29 "Message29" 28 "Message28" 27 "Message27" 26 "Message26" 25 "Message25" 24 "Message24" 23 "Message23" 22 "Message22" 21 "Message21" 20 "Message20" 19 "Message19" 18 "Message18" 17 "Message17" 16 "Message16" 15 "Message15" 14 "Message14" 13 "Message13" 12 "Message12" 11 "Message11" 10 "Message10" 9 "Message9" 8 "Message8" 7 "Message7" 6 "Message6" 5 "Message5" 4 "Message4" 3 "Message3" 2 "Message2" 1 "Message1" 0 "NoMessage" 63 "Message63" 47 "Message47" ;
VAL_ 1105 RbaMsg_D_Rq 3 "Faulty" 2 "Unavailable" 1 "Off" 0 "Null" ;
VAL_ 1105 BrkDecel_B_RqRba 1 "Enable" 0 "Disable" ;
VAL_ 1105 BrkEnbl_B_RqRba 1 "Enable" 0 "Disable" ;
VAL_ 1105 Rba_D_Stat 3 "NotUsed" 2 "Disabled" 1 "On" 0 "Off" ;
VAL_ 1105 RbaAlrt_D_Dsply 3 "Both" 2 "Text" 1 "Graphic" 0 "Off" ;
VAL_ 1105 RbaMnu_D_Rq 3 "NotUsed" 2 "Active" 1 "Inactive" 0 "None" ;
VAL_ 1105 RbaSys_D_Stat 3 "Faulty" 2 "Available" 1 "Suspended" 0 "Disabled" ;
VAL_ 1105 CamraFrntStat_D_Stat 3 "No_Data_Present" 2 "NotUsed" 1 "On" 0 "Off" ;
VAL_ 1105 TrlrHitchLamp_D_Rq2 1 "On" 0 "Off" ;
VAL_ 1105 ClrExitAsstMsgTxt2_D_Rq 15 "NotUsed_7" 14 "NotUsed_6" 13 "NotUsed_5" 12 "NotUsed_4" 11 "NotUsed_3" 10 "NotUsed_2" 9 "NotUsed_1" 8 "FrontLeftRearRight" 7 "RearLeftFrontRight" 6 "FrontLeftFrontRight" 5 "RearLeftRearRight" 4 "FrontRight" 3 "FrontLeft" 2 "RearRight" 1 "RearLeft" 0 "NoMessage" ;
VAL_ 1105 ClrExitAsstActv_B_Rq 1 "Active" 0 "Inactive" ;
VAL_ 1105 CamraFrntOffRd_B_Stat 1 "Active" 0 "Inactive" ;
VAL_ 1105 TrlrAidSwtchLamp_B_Rq 1 "On" 0 "Off" ;
VAL_ 1105 TrlrAidEnbl_D_RqAdas 7 "NotUsed_4" 6 "NotUsed_3" 5 "NotUsed_2" 4 "NotUsed_1" 3 "Deactivate" 2 "NotAvailable" 1 "ActiveTba" 0 "Inactive" ;
VAL_ 1105 TrlrHitchMsgTxt_D_Rq 31 "Message31" 30 "Message30" 29 "Message29" 28 "Message28" 27 "Message27" 26 "Message26" 25 "Message25" 24 "Message24" 23 "Message23" 22 "Message22" 21 "Message21" 20 "Message20" 19 "Message19" 18 "Message18" 17 "Message17" 16 "Message16" 15 "Message15" 14 "Message14" 13 "Message13" 12 "Message12" 11 "Message11" 10 "Message10" 9 "Message9" 8 "Message8" 7 "Message7" 6 "Message6" 5 "Message5" 4 "Message4" 3 "Message3" 2 "Message2" 1 "Message1" 0 "NoMessage" 63 "Message63" 47 "Message47" ;
VAL_ 1105 TrlrHitchIcon_D_Rq 15 "Icon15" 14 "Icon14" 13 "Icon13" 12 "Icon12" 11 "Icon11" 10 "Icon10" 9 "Icon9" 8 "Icon8" 7 "Icon7" 6 "Icon6" 5 "Icon5" 4 "Icon4" 3 "Icon3" 2 "Icon2" 1 "Icon1" 0 "NoIcon" ;
VAL_ 1105 TrlrHitchChime_D_Rq 7 "NotUsed_1" 6 "NotUsed_1" 5 "WarningChime" 4 "NonCriticalAlertChime" 3 "StopNowChime" 2 "ManeuveringReadyChime" 1 "TrailerFoundChime" 0 "NoChime" ;
VAL_ 1056 SelDrvMdePos12_B_Avail 1 "Available" 0 "NotAvailable" ;
VAL_ 1056 SelDrvMdePos11_B_Avail 1 "Available" 0 "NotAvailable" ;
VAL_ 1056 SelDrvMdePos10_B_Avail 1 "Available" 0 "NotAvailable" ;
VAL_ 1056 SelDrvMdePos09_B_Avail 1 "Available" 0 "NotAvailable" ;
VAL_ 1056 SelDrvMdePos08_B_Avail 1 "Available" 0 "NotAvailable" ;
VAL_ 1056 SelDrvMdePos07_B_Avail 1 "Available" 0 "NotAvailable" ;
VAL_ 1056 SelDrvMdePos06_B_Avail 1 "Available" 0 "NotAvailable" ;
VAL_ 1056 SelDrvMdePos05_B_Avail 1 "Available" 0 "NotAvailable" ;
VAL_ 1056 SelDrvMdePos04_B_Avail 1 "Available" 0 "NotAvailable" ;
VAL_ 1056 SelDrvMdePos03_B_Avail 1 "Available" 0 "NotAvailable" ;
VAL_ 1056 SelDrvMdePos02_B_Avail 1 "Available" 0 "NotAvailable" ;
VAL_ 1056 SelDrvMdePos01_B_Avail 1 "Available" 0 "NotAvailable" ;
VAL_ 1056 ActvDrvMde_D2_Stat 31 "Faulty" 30 "SelDrvMde31" 29 "SelDrvMde30" 28 "SelDrvMde29" 27 "SelDrvMde28" 26 "SelDrvMde27" 25 "SelDrvMde26" 24 "SelDrvMde25" 23 "SelDrvMde24" 22 "SelDrvMde23" 21 "SelDrvMde22" 20 "SelDrvMde21" 19 "SelDrvMde20" 18 "SelDrvMde19" 17 "SelDrvMde18" 16 "SelDrvMde17" 15 "SelDrvMde16" 14 "SelDrvMde15" 13 "SelDrvMde14" 12 "SelDrvMde13" 11 "SelDrvMde12" 10 "SelDrvMde11" 9 "SelDrvMde10" 8 "SelDrvMde09" 7 "SelDrvMde08" 6 "SelDrvMde07" 5 "SelDrvMde06" 4 "SelDrvMde05" 3 "SelDrvMde04" 2 "SelDrvMde03" 1 "SelDrvMde02" 0 "SelDrvMde01" ;
VAL_ 1056 SelDrvMde_D2_Rq 31 "Faulty" 30 "SelDrvMde31" 29 "SelDrvMde30" 28 "SelDrvMde29" 27 "SelDrvMde28" 26 "SelDrvMde27" 25 "SelDrvMde26" 24 "SelDrvMde25" 23 "SelDrvMde24" 22 "SelDrvMde23" 21 "SelDrvMde22" 20 "SelDrvMde21" 19 "SelDrvMde20" 18 "SelDrvMde19" 17 "SelDrvMde18" 16 "SelDrvMde17" 15 "SelDrvMde16" 14 "SelDrvMde15" 13 "SelDrvMde14" 12 "SelDrvMde13" 11 "SelDrvMde12" 10 "SelDrvMde11" 9 "SelDrvMde10" 8 "SelDrvMde09" 7 "SelDrvMde08" 6 "SelDrvMde07" 5 "SelDrvMde06" 4 "SelDrvMde05" 3 "SelDrvMde04" 2 "SelDrvMde03" 1 "SelDrvMde02" 0 "SelDrvMde01" ;
VAL_ 1056 AwdMde_D_RqBrk 7 "Faulty" 6 "NotUsed2" 5 "NoRequest" 4 "Neutral" 3 "FourByFourLow" 2 "FourByFourHigh" 1 "FourByFourAuto" 0 "FourByTwo" ;
VAL_ 1056 SelDrvMdePt_D_Rq 31 "Faulty" 30 "NotUsed15" 29 "NotUsed14" 28 "NotUsed13" 27 "NotUsed12" 26 "NotUsed11" 25 "NotUsed10" 24 "NotUsed9" 23 "NotUsed8" 22 "NotUsed7" 21 "CustomMode" 20 "TrackMode" 19 "OnePedalDrive" 18 "EvLaterChargerMode" 17 "EvNowMode" 16 "DragMode" 15 "HighSpeedDesertMode_Baja" 14 "SportAdaptiveMode" 13 "NotAvailable_13" 12 "NotAvailable_12" 11 "NotAvailable_11" 10 "NotAvailable_10" 9 "RockCrawlMode" 8 "MudRutsMode" 7 "SandMode" 6 "EconomyMode" 5 "GrassGravelSnow" 4 "NotAvailable_04" 3 "TowHaulMode" 2 "NotAvailable_02" 1 "SportMode" 0 "NormalMode" ;
VAL_ 1056 SelDrvMdeMsgTxt_D_Rq 15 "Message15" 14 "Message14" 13 "Message13" 12 "Message12" 11 "Message11" 10 "Message10" 9 "Message9" 8 "Message8" 7 "Message7" 6 "Message6" 5 "Message5" 4 "Message4" 3 "Message3" 2 "Message2" 1 "Message1" 0 "NoMessage" ;
VAL_ 1056 SelDrvMde_D_Stat 3 "NotUsed" 2 "DriveModeChangeRequest" 1 "DriveModeChangeSelection" 0 "NoDriveModeChangeRequest" ;
VAL_ 1056 AutoEpbButtnOn_B_Stat 1 "On" 0 "Off" ;
VAL_ 1056 AutoEpbMsgTxt_D_Rq 7 "Message7" 6 "Message6" 5 "Message5" 4 "Message4" 3 "Message3" 2 "Message2" 1 "Message1" 0 "NoMessage" ;
VAL_ 1056 AutoEpbDsply_D_Stat 3 "NotUsed" 2 "GreyedOut" 1 "Available" 0 "NotAvailable" ;
VAL_ 1056 SelDrvMdeHmi03_D_Rq 31 "Faulty" 30 "SelDrvMde31" 29 "SelDrvMde30" 28 "SelDrvMde29" 27 "SelDrvMde28" 26 "SelDrvMde27" 25 "SelDrvMde26" 24 "SelDrvMde25" 23 "SelDrvMde24" 22 "SelDrvMde23" 21 "SelDrvMde22" 20 "SelDrvMde21" 19 "SelDrvMde20" 18 "SelDrvMde19" 17 "SelDrvMde18" 16 "SelDrvMde17" 15 "SelDrvMde16" 14 "SelDrvMde15" 13 "SelDrvMde14" 12 "SelDrvMde13" 11 "SelDrvMde12" 10 "SelDrvMde11" 9 "SelDrvMde10" 8 "SelDrvMde09" 7 "SelDrvMde08" 6 "SelDrvMde07" 5 "SelDrvMde06" 4 "SelDrvMde05" 3 "SelDrvMde04" 2 "SelDrvMde03" 1 "SelDrvMde02" 0 "SelDrvMde01" ;
VAL_ 1056 SelDrvMdeMsgTxt2_D_Rq 15 "Message15" 14 "Message14" 13 "Message13" 12 "Message12" 11 "Message11" 10 "Message10" 9 "Message9" 8 "Message8" 7 "Message7" 6 "Message6" 5 "Message5" 4 "Message4" 3 "Message3" 2 "Message2" 1 "Message1" 0 "NoMessage" ;
VAL_ 1047 TrlrAidSetup_D2_Stat 7 "NotUsed_2" 6 "NotUsed_1" 5 "SetupAcquisitionSuccess" 4 "TbaTadMonitor" 3 "SetupStartAcquisition" 2 "SetupPrepForAcquisition" 1 "TbaActive" 0 "Null" ;
VAL_ 1047 TrlrAidEnbl_D2_Stat 7 "NotUsed_1" 6 "TbaActiveExpertActive" 5 "TbaActiveExpertAvail" 4 "TbaOffTrgActive" 3 "TbaOffTrgSetup" 2 "TbaSetup" 1 "TbaActive" 0 "Inactive" ;
VAL_ 1047 TrlrAidMsgTxt_D2_Rq 63 "Message63" 62 "Message62" 61 "Message61" 60 "Message60" 55 "Message55" 50 "Message50" 45 "Message45" 40 "Message40" 35 "Message35" 31 "Message31" 30 "Message30" 29 "Message29" 28 "Message28" 27 "Message27" 26 "Message26" 25 "Message25" 24 "Message24" 23 "Message23" 22 "Message22" 21 "Message21" 20 "Message20" 19 "Message19" 18 "Message18" 17 "Message17" 16 "Message16" 15 "Message15" 14 "Message14" 13 "Message13" 12 "Message12" 11 "Message11" 10 "Message10" 9 "Message9" 8 "Message8" 7 "Message7" 6 "Message6" 5 "Message5" 4 "Message4" 3 "Message3" 2 "Message2" 1 "Message1" 0 "NoMessage" ;
VAL_ 1047 EsaOn_B_Stat 1 "On" 0 "Off" ;
VAL_ 1047 SelDrvMdeSte_D_Stat 0 "NotAvailable" 1 "Available" 2 "TemporarilyNotAvailable" 3 "Faulty" ;
VAL_ 997 PersIndexCcm_D_Actl 7 "Unused_3" 6 "Unused_2" 5 "Unused_1" 4 "Vehicle" 3 "PERS_4" 2 "PERS_3" 1 "PERS_2" 0 "PERS_1" ;
VAL_ 997 PersTurnSglView_D_Stat 3 "NotConfigured" 2 "Enabled" 1 "Disabled" 0 "Null" ;
VAL_ 962 AdbBrdr3DistRigh_D_Stat 15 "DistGreater800m" 14 "Dist700mTo800m" 13 "Dist600mTo700m" 12 "Dist500mTo600m" 11 "Dist400mTo500m" 10 "Dist300mTo400m" 9 "Dist200mTo300m" 8 "Dist175mTo200m" 7 "Dist150mTo175m" 6 "Dist125mTo150m" 5 "Dist100mTo125m" 4 "Dist75mTo100m" 3 "Dist50mTo75m" 2 "Dist25mTo50m" 1 "Dist15mTo25m" 0 "Dist0mTo15m" ;
VAL_ 962 AdbBrdr3DistLeft_D_Stat 15 "DistGreater800m" 14 "Dist700mTo800m" 13 "Dist600mTo700m" 12 "Dist500mTo600m" 11 "Dist400mTo500m" 10 "Dist300mTo400m" 9 "Dist200mTo300m" 8 "Dist175mTo200m" 7 "Dist150mTo175m" 6 "Dist125mTo150m" 5 "Dist100mTo125m" 4 "Dist75mTo100m" 3 "Dist50mTo75m" 2 "Dist25mTo50m" 1 "Dist15mTo25m" 0 "Dist0mTo15m" ;
VAL_ 962 AdbMde3_D_Rq 3 "MarkerLightFlashing" 2 "MarkerLightConstant" 1 "Spot" 0 "None" ;
VAL_ 962 AdbIntns3_D_Rq 3 "Maximum" 2 "Medium" 1 "Low" 0 "Off" ;
VAL_ 962 AdbBrdr3Up_An_Rq 511 "Faulty" 510 "NoDataExists" ;
VAL_ 962 AdbBrdr3Right_An_Rq 2047 "Faulty" 2046 "NoDataExists" ;
VAL_ 962 AdbBrdr3Low_An_Rq 511 "Faulty" 510 "NoDataExists" ;
VAL_ 962 AdbBrdr3Left_An_Rq 2047 "Faulty" 2046 "NoDataExists" ;
VAL_ 961 AdbBrdr2DistRigh_D_Stat 15 "DistGreater800m" 14 "Dist700mTo800m" 13 "Dist600mTo700m" 12 "Dist500mTo600m" 11 "Dist400mTo500m" 10 "Dist300mTo400m" 9 "Dist200mTo300m" 8 "Dist175mTo200m" 7 "Dist150mTo175m" 6 "Dist125mTo150m" 5 "Dist100mTo125m" 4 "Dist75mTo100m" 3 "Dist50mTo75m" 2 "Dist25mTo50m" 1 "Dist15mTo25m" 0 "Dist0mTo15m" ;
VAL_ 961 AdbBrdr2DistLeft_D_Stat 15 "DistGreater800m" 14 "Dist700mTo800m" 13 "Dist600mTo700m" 12 "Dist500mTo600m" 11 "Dist400mTo500m" 10 "Dist300mTo400m" 9 "Dist200mTo300m" 8 "Dist175mTo200m" 7 "Dist150mTo175m" 6 "Dist125mTo150m" 5 "Dist100mTo125m" 4 "Dist75mTo100m" 3 "Dist50mTo75m" 2 "Dist25mTo50m" 1 "Dist15mTo25m" 0 "Dist0mTo15m" ;
VAL_ 961 AdbMde2_D_Rq 3 "MarkerLightFlashing" 2 "MarkerLightConstant" 1 "Spot" 0 "None" ;
VAL_ 961 AdbIntns2_D_Rq 3 "Maximum" 2 "Medium" 1 "Low" 0 "Off" ;
VAL_ 961 AdbBrdr2Up_An_Rq 511 "Faulty" 510 "NoDataExists" ;
VAL_ 961 AdbBrdr2Right_An_Rq 2047 "Faulty" 2046 "NoDataExists" ;
VAL_ 961 AdbBrdr2Low_An_Rq 511 "Faulty" 510 "NoDataExists" ;
VAL_ 961 AdbBrdr2Left_An_Rq 2047 "Faulty" 2046 "NoDataExists" ;
VAL_ 394 AccTrgDist2_D_Dsply 15 "DIST_ACTIVE_13_Farthest" 14 "DIST_ACTIVE_12" 13 "DIST_ACTIVE_11" 12 "DIST_ACTIVE_10" 11 "DIST_ACTIVE_9" 10 "DIST_ACTIVE_8" 9 "DIST_ACTIVE_7" 8 "DIST_ACTIVE_6" 7 "DIST_ACTIVE_5" 6 "DIST_ACTIVE_4" 5 "DIST_ACTIVE_3" 4 "DIST_ACTIVE_2" 3 "DIST_ACTIVE_1_Closest" 2 "DIST_ACTIVE_No_Target" 1 "DIST_STANDBY" 0 "DIST_OFF" ;
VAL_ 394 AccStopRes_B_Dsply 1 "Yes" 0 "No" ;
VAL_ 394 TjaWarn_D_Rq 7 "HardTakeOverEyesOff" 6 "SoftTakeOverEyesOff" 5 "HaLaneDeptWarningLeft" 4 "HaLaneDeptWarningRight" 3 "HardTakeOverLevel2" 2 "HardTakeOverLevel1" 1 "TrafficJamAssistCancel" 0 "NoWarning" ;
VAL_ 394 Tja_D_Stat 7 "ExtendedActive" 6 "ActiveWarningRight" 5 "ActiveWarningLeft" 4 "ActiveInterventionRight" 3 "ActiveInterventionLeft" 2 "Active" 1 "Standby" 0 "Off" ;
VAL_ 394 IaccLamp_D_Rq 3 "NotUsed_2" 2 "NotUsed_1" 1 "DisplayIaccIcon" 0 "DoNotDisplayIaccIcon" ;
VAL_ 394 AccMsgTxt_D2_Rq 15 "Brakes_Warm" 14 "NCC_Enabled_Warning" 13 "IACC_TJA_Selected" 12 "ACC_TJA_Selected" 11 "IACC_Selected" 10 "Press_Brake_To_Hold" 9 "Only_Following_In_Low_Spd" 8 "TJA_Unavailable" 7 "Shift_Down" 6 "IACC_Unavailable" 5 "ACC_Selected" 4 "ACC_Overridden" 3 "Brake_Capacity_Warning" 2 "ACC_Cancelled" 1 "ACC_Unavailable" 0 "No_Text" ;
VAL_ 394 TjaMsgTxt_D_Dsply 7 "Disclaimer" 6 "SmartOffering" 5 "HaSelected" 4 "HaUnavailable" 3 "TurnOnAdaptCruiseControl" 2 "TrafficJamAssistSelected" 1 "TrafficJamAssistUnavailabl" 0 "NoMessage" ;
VAL_ 394 FcwDeny_B_Dsply 1 "Yes" 0 "No" ;
VAL_ 394 FcwMemStat_B_Actl 1 "On" 0 "Off" ;
VAL_ 394 AccTGap_B_Dsply 1 "Yes" 0 "No" ;
VAL_ 394 CadsAlignIncplt_B_Actl 1 "Yes" 0 "No" ;
VAL_ 394 AccFllwMde_B_Dsply 1 "Yes" 0 "No" ;
VAL_ 394 CadsRadrBlck_B_Actl 1 "Yes" 0 "No" ;
VAL_ 394 CmbbPostEvnt_B_Dsply 1 "Yes" 0 "No" ;
VAL_ 394 AccStopMde_B_Dsply 1 "Yes" 0 "No" ;
VAL_ 394 FcwMemSens_D_Actl 3 "FCW_Sensitivity_3" 2 "FCW_Sensitivity_2" 1 "FCW_Sensitivity_1" 0 "Not_Used" ;
VAL_ 394 FcwMsgTxt_D_Rq 7 "Undefined_3" 6 "Undefined_2" 5 "Low_Visibility" 4 "Unavailable_DueTo_LowSpeed" 3 "Available" 2 "Unavailable" 1 "Off" 0 "No_Text" ;
VAL_ 394 AccTGap_D_Dsply 7 "Undefined_2" 6 "Undefined_1" 5 "Time_Gap_5" 4 "Time_Gap_4" 3 "Time_Gap_3" 2 "Time_Gap_2" 1 "Time_Gap_1" 0 "Not_Used" ;
VAL_ 394 AccMemEnbl_B_RqDrv 1 "Adaptive_Cruise" 0 "Normal_Cruise" ;
VAL_ 394 AccWarn_D_Dsply 3 "BrakeReleaseWarn_In_StopMd" 2 "Brake_Capacity_Warning" 1 "Cancel_Warning" 0 "No_Warning" ;
VAL_ 394 FcwVisblWarn_B_Rq 1 "On" 0 "Off" ;
VAL_ 394 FcwAudioWarn_B_Rq 1 "On" 0 "Off" ;
VAL_ 394 AccStopStat_D_Dsply 3 "PressResume" 2 "Stopped" 1 "ResumeReady" 0 "NoDisplay" ;
VAL_ 671 LaneTypeRight_D_Est 7 "NotUsed" 6 "DoubleLaneMarking" 5 "SolidOrDashedOrBotts" 4 "BottsDots" 3 "Dashed" 2 "Solid" 1 "NoClassOrDetection" 0 "None" ;
VAL_ 671 LaneTypeLeft_D_Est 7 "NotUsed" 6 "DoubleLaneMarking" 5 "SolidOrDashedOrBotts" 4 "BottsDots" 3 "Dashed" 2 "Solid" 1 "NoClassOrDetection" 0 "None" ;
VAL_ 671 LanePlynmlValdRght_L_Mx 1 "True" 0 "False" ;
VAL_ 671 LanePlynmlValdLeft_L_Mx 1 "True" 0 "False" ;
VAL_ 671 LaneCurvRight_K_Est 4095 "Fault" ;
VAL_ 671 LaneCurvLeft_K_Est 4095 "Fault" ;
VAL_ 671 LaneConfdncRght_D_Stat 3 "Confidence_3" 2 "Confidence_2" 1 "Confidence_1" 0 "Confidence_0" ;
VAL_ 671 LaneConfdncLeft_D_Stat 3 "Confidence_3" 2 "Confidence_2" 1 "Confidence_1" 0 "Confidence_0" ;
VAL_ 671 LaneAmbigRight_B_Est 1 "True" 0 "False" ;
VAL_ 671 LaneAmbigLeft_B_Est 1 "True" 0 "False" ;
VAL_ 942 PrkBrkElRleas_B_RqApa 1 "Yes" 0 "No" ;
VAL_ 942 PrkAidAcsyRear_D_Stat 3 "NotUsed" 2 "On" 1 "Off" 0 "Null" ;
VAL_ 942 PrkAidAcsyFront_D_Stat 3 "NotUsed" 2 "On" 1 "Off" 0 "Null" ;
VAL_ 942 ApaSys_D2_Stat 15 "NotUsed_5" 14 "NotUsed_4" 13 "NotUsed_3" 12 "NotUsed_2" 11 "NotUsed_1" 10 "NoSideSelectable" 9 "RightSideSelectable" 8 "LeftSideSelectable" 7 "BothSidesSelectable" 6 "Faulty" 5 "Finished" 4 "Cancelled" 3 "NotAvailable" 2 "Overspeed" 1 "Pause" 0 "NormalOperation" ;
VAL_ 942 ApaSlotTrgt_D_Stat 15 "NotUsed_7" 14 "NotUsed_6" 13 "NotUsed_5" 12 "NotUsed_4" 11 "NotUsed_3" 10 "NotUsed_2" 9 "NotUsed_1" 8 "Front" 7 "Rear" 6 "Right3" 5 "Right2" 4 "Right1" 3 "Left3" 2 "Left2" 1 "Left1" 0 "None" ;
VAL_ 942 ApaSlotOption_B_Avail 1 "Available" 0 "NotAvailable" ;
VAL_ 942 ApaSlotAlrtSet_B_Stat 1 "Enable" 0 "Disable" ;
VAL_ 942 ApaSlotAlrt_B_Rq 1 "True" 0 "False" ;
VAL_ 942 ApaRmtFeatSel_B_Avail 1 "Available" 0 "NotAvailable" ;
VAL_ 942 ApaParkOutSel_B_Avail 1 "Available" 0 "NotAvailable" ;
VAL_ 942 ApaParkInSel_B_Avail 1 "Available" 0 "NotAvailable" ;
VAL_ 942 ApaMsgTxt_D2_Stat 15 "ReducedFunction" 14 "TrailerFeatureNotAvailable" 13 "AcceleratorPedalInactive" 12 "SensorsBlocked" 11 "TrailerAttached" 10 "TcsDeactivated" 9 "WheelSlip" 8 "HighInclination" 7 "DoorOpen" 6 "SteeringInteraction" 5 "WrongDirection" 4 "SpeedLimitExceeded" 3 "BrakeEvent" 2 "ObstacleInPath" 1 "WaitForSteering" 0 "None" ;
VAL_ 942 ApaDynmcSlot_B_Stat 1 "On" 0 "Off" ;
VAL_ 942 ApaDisplayMode_D_Stat 3 "NotUsed" 2 "FullScreen" 1 "Menu" 0 "Off" ;
VAL_ 942 ApaControlMode_D_Stat 1 "Active" 0 "Inactive" ;
VAL_ 942 PrkAidDrvDir_D_Stat 7 "NotUsed_2" 6 "NotUsed_1" 5 "BackwardNegative" 4 "ForwardNegative" 3 "BackwardPositive" 2 "ForwardPositive" 1 "NoMotion" 0 "DirectionNotKnown" ;
VAL_ 1049 PersTurnSglView_D_RqMnu 3 "NotUsed" 2 "Enable" 1 "Disable" 0 "Null" ;
VAL_ 1049 FrontDiffLck_D_RqDrv3 3 "Faulty" 2 "NoRequest" 1 "On" 0 "Off" ;
VAL_ 1049 RearDiffLck_D_RqDrv3 3 "Faulty" 2 "NoRequest" 1 "On" 0 "Off" ;
VAL_ 1049 TrailCtlSwtch_B_Stat4 1 "Pressed" 0 "Not_Pressed" ;
VAL_ 1049 CamraFrnt_B_RqMnu 1 "On" 0 "Off" ;
VAL_ 1049 StabBarCnncButtn_D_Sta3 3 "Faulty" 2 "NotUsed" 1 "Pressed" 0 "Not_Pressed" ;
VAL_ 1049 TurnAsstSwtch_D_Stat 3 "Faulty" 2 "NotUsed" 1 "Pressed" 0 "Not_Pressed" ;
VAL_ 1049 SelDrvMdeTxtRst_B_Rq2 1 "Yes" 0 "No" ;
VAL_ 1049 SelDrvMdePage_B_Stat 1 "Active" 0 "Inactive" ;
VAL_ 1049 SelDrvMdeCnfm_D_Stat2 3 "NotUsed" 2 "Accepted" 1 "NotAccepted" 0 "Null" ;
VAL_ 1049 SelDrvMde_D_RqDrv 31 "Faulty" 30 "SelDrvMde31" 29 "SelDrvMde30" 28 "SelDrvMde29" 27 "SelDrvMde28" 26 "SelDrvMde27" 25 "SelDrvMde26" 24 "SelDrvMde25" 23 "SelDrvMde24" 22 "SelDrvMde23" 21 "SelDrvMde22" 20 "SelDrvMde21" 19 "SelDrvMde20" 18 "SelDrvMde19" 17 "SelDrvMde18" 16 "SelDrvMde17" 15 "SelDrvMde16" 14 "SelDrvMde15" 13 "SelDrvMde14" 12 "SelDrvMde13" 11 "SelDrvMde12" 10 "SelDrvMde11" 9 "SelDrvMde10" 8 "SelDrvMde09" 7 "SelDrvMde08" 6 "SelDrvMde07" 5 "SelDrvMde06" 4 "SelDrvMde05" 3 "SelDrvMde04" 2 "SelDrvMde03" 1 "SelDrvMde02" 0 "SelDrvMde01" ;
VAL_ 1120 StabBarCnncButtn_D_Stat 3 "Faulty" 2 "NotUsed" 1 "Pressed" 0 "Not_Pressed" ;
VAL_ 1120 DrvSlipCtlMde_B_Rq3 1 "Pressed" 0 "Not_Pressed" ;
VAL_ 1120 HybMdeSwtch_B_Rq 1 "Pressed" 0 "Not_Pressed" ;
VAL_ 1120 FrontDiffLck_D_RqDrv 3 "Faulty" 2 "NoRequest" 1 "On" 0 "Off" ;
VAL_ 1120 AwdLck_D_RqDrv 3 "Faulty" 2 "NoRequest" 1 "On" 0 "Off" ;
VAL_ 1120 TrailCtlSwtch_B_Stat3 1 "Pressed" 0 "Not_Pressed" ;
VAL_ 1120 RearDiffLck_D_RqDrv 3 "Faulty" 2 "NoRequest" 1 "On" 0 "Off" ;
VAL_ 1120 AwdMde_D_RqDrv 7 "Faulty" 6 "NotUsed2" 5 "NoRequest" 4 "Neutral" 3 "FourByFourLow" 2 "FourByFourHigh" 1 "FourByFourAuto" 0 "FourByTwo" ;
VAL_ 1120 HdcSwtchPos_B_Actl 1 "Pressed" 0 "Not_Pressed" ;
VAL_ 1052 AwdDcnntSlipTrgt_B_Rq 1 "Request" 0 "NoRequest" ;
VAL_ 1052 AwdCnnct_D_Stat 3 "Connecting" 2 "Disconnecting" 1 "Connected" 0 "Disconnected" ;
VAL_ 1052 AwdRight_Tq_Rq 4095 "Fault" 4094 "Unknown" ;
VAL_ 1052 AwdRight_Tq_Est 4095 "Fault" 4094 "Unknown" ;
VAL_ 1052 AwdLeft_Tq_Rq 4095 "Fault" 4094 "Unknown" ;
VAL_ 1052 AwdLeft_Tq_Est 4095 "Fault" 4094 "Unknown" ;
VAL_ 1052 AwdLck_Tq_Actl 4095 "Fault" 4094 "Unknown" ;
VAL_ 1052 AwdLckTqNeg_B_Actl 1 "Active" 0 "Inactive" ;
VAL_ 139 AccButtnGpTogglePress2 1 "Pressed" 0 "Not_Pressed" ;
VAL_ 139 TjaButtnOnOffPress2 1 "Pressed" 0 "Not_Pressed" ;
VAL_ 139 ActvFrontSteMsgTxt_D_Rq 7 "Message7" 6 "Message6" 5 "Message5" 4 "Message4" 3 "Message3" 2 "Message2" 1 "Message1" 0 "NoMessage" ;
VAL_ 139 ActvFrontSteLck_D_Stat 3 "Test_passed" 2 "Test_failed" 1 "Test_cannot_run" 0 "Test_incomplete" ;
VAL_ 139 SelDrvMdeAdptSte_D_Stat 3 "Faulty" 2 "TemporarilyNotAvailable" 1 "Available" 0 "NotAvailable" ;
VAL_ 139 AslButtnOnOffPress2 1 "Button_Pressed" 0 "Button_Not_Pressed" ;
VAL_ 139 AslButtnOnOffCnclPres2 1 "Button_Pressed" 0 "Button_Not_Pressed" ;
VAL_ 139 CcButtnOnPress2 1 "Button_Pressed" 0 "Button_Not_Pressed" ;
VAL_ 139 CcButtnOnOffPress2 1 "Button_Pressed" 0 "Button_Not_Pressed" ;
VAL_ 139 CcButtnOnOffCnclPress2 1 "Button_Pressed" 0 "Button_Not_Pressed" ;
VAL_ 139 CcButtnOffPress2 1 "Button_Pressed" 0 "Button_Not_Pressed" ;
VAL_ 139 CcAsllButtnResPress2 1 "Button_Pressed" 0 "Button_Not_Pressed" ;
VAL_ 139 CcAslButtnSetPress2 1 "Button_Pressed" 0 "Button_Not_Pressed" ;
VAL_ 139 CcAslButtnSetIncPress2 1 "Button_Pressed" 0 "Button_Not_Pressed" ;
VAL_ 139 CcAslButtnSetDecPress2 1 "Button_Pressed" 0 "Button_Not_Pressed" ;
VAL_ 139 CcAslButtnResIncPress2 1 "Button_Pressed" 0 "Button_Not_Pressed" ;
VAL_ 139 CcAslButtnResDecPress2 1 "Button_Pressed" 0 "Button_Not_Pressed" ;
VAL_ 139 CcAslButtnOnPress2 1 "Button_Pressed" 0 "Button_Not_Pressed" ;
VAL_ 139 CcAslButtnOnOffCncl2 1 "Button_Pressed" 0 "Button_Not_Pressed" ;
VAL_ 139 CcAslButtnOffCnclPres2 1 "Button_Pressed" 0 "Button_Not_Pressed" ;
VAL_ 139 CcAslButtnIndxIncPres2 1 "Button_Pressed" 0 "Button_Not_Pressed" ;
VAL_ 139 CcAslButtnIndxDecPres2 1 "Button_Pressed" 0 "Button_Not_Pressed" ;
VAL_ 139 CcAslButtnDeny_B_Actl2 1 "Yes" 0 "No" ;
VAL_ 139 CcAslButtnCnclResPres2 1 "Button_Pressed" 0 "Button_Not_Pressed" ;
VAL_ 139 CcAslButtnCnclPress2 1 "Button_Pressed" 0 "Button_Not_Pressed" ;
VAL_ 139 AccButtnGapIncPress2 1 "Button_Pressed" 0 "Button_Not_Pressed" ;
VAL_ 139 AccButtnGapDecPress2 1 "Button_Pressed" 0 "Button_Not_Pressed" ;
VAL_ 139 AfsPw_B_Rq 1 "Yes" 0 "No" ;
VAL_ 1186 AwdDrvMde_D2_Stat 15 "Faulty" 14 "NotUsed_7" 13 "NotUsed_6" 12 "NotUsed_5" 11 "NotUsed_4" 10 "NotUsed_3" 9 "NotUsed_2" 8 "NotUsed_1" 7 "NotAvailable" 6 "TowHaul" 5 "RockCrawl" 4 "Baja" 3 "MudAndSand" 2 "Weather" 1 "Sport" 0 "Normal" ;
VAL_ 1186 FrontDiffLckLamp_D_Rq 3 "Triggered" 2 "Flash" 1 "On" 0 "Off" ;
VAL_ 1186 FrontDiffLckMsg_D_Rq 7 "LockerDisabled" 6 "LockerEnabled" 5 "LockerAccelPedal" 4 "Speed4" 3 "Speed3" 2 "Speed2" 1 "Speed1" 0 "NormalNoMessage" ;
VAL_ 1186 AwdStat2_D_RqDsply 31 "NotUsed_29" 30 "NotUsed_28" 29 "NotUsed_27" 28 "NotUsed_26" 27 "NotUsed_25" 26 "NotUsed_24" 25 "NotUsed_23" 24 "NotUsed_22" 23 "NotUsed_21" 22 "NotUsed_20" 21 "NotUsed_19" 20 "NotUsed_18" 19 "NotUsed_17" 18 "NotUsed_16" 17 "NotUsed_15" 16 "NotUsed_14" 15 "NotUsed_13" 14 "NotUsed_12" 13 "NotUsed_11" 12 "NotUsed_10" 11 "NotUsed_9" 10 "NotUsed_8" 9 "NotUsed_7" 8 "NotUsed_6" 7 "NotUsed_5" 6 "NotUsed_4" 5 "Unavailable4x4Mode" 4 "UnavailableDriveMode" 3 "HillHoldFail" 2 "TCaseOilChanged" 1 "ChangeTCaseOil" 0 "Normal" ;
VAL_ 1186 FrontDiffFalt_D_Stat 3 "Diff_Failed_Closed" 2 "Diff_Failed_Open" 1 "Fault_Non_Specific" 0 "No_Fault" ;
VAL_ 1186 FrontDiffLck_Tq_Actl 16383 "Faulty" 16382 "NoDataExists" ;
VAL_ 1186 SelDrvMdeAwd2_D_Stat 31 "Faulty" 30 "NotUsed_17" 29 "NotUsed_16" 28 "NotUsed_15" 27 "NotUsed_14" 26 "NotUsed_13" 25 "NotUsed_12" 24 "NotUsed_11" 23 "NotUsed_10" 22 "NotUsed_9" 21 "NotUsed_8" 20 "CustomMode" 19 "OnePedalDrive" 18 "DragMode" 17 "EvLaterChargeMode" 16 "EvNowMode" 15 "TrackMode" 14 "RoughRoadMode" 13 "NotAvailable" 12 "HighSpeedDesertMode_Baja" 11 "SportAdaptiveMode" 10 "RockCrawlMode" 9 "MudRutsMode" 8 "SandMode" 7 "EconomyMode" 6 "GrassGravelSnow" 5 "TowHaulMode" 4 "SportMode" 3 "Normal_4L" 2 "Normal_4A" 1 "Normal_2H" 0 "NormalMode" ;
VAL_ 1186 RearDiffLckMsg_D_Rq 7 "Locker_Disabled" 6 "Locker_Enabled" 5 "Locker_Accel_Pedal" 4 "Speed4" 3 "Speed3" 2 "Spee2" 1 "Speed1" 0 "Normal__No_Message " ;
VAL_ 1186 RearDiffLckLamp_D_Rq 3 "Not_Used" 2 "Flash" 1 "On" 0 "Off" ;
VAL_ 1186 RearDiffLck_Tq_Actl 4095 "Fault" 4094 "Unknown" ;
VAL_ 1186 RearDiffFalt_D_Stat 3 "Diff_Failed_Closed" 2 "Diff_Failed_Open" 1 "Fault_Non_Specific" 0 "No_Fault" ;
VAL_ 1186 LsdSrvcRqd_B_Rq 1 "On" 0 "Off" ;
VAL_ 1042 VehRol_An_Dsply 127 "Faulty" 126 "NoDataExists" ;
VAL_ 1042 RearDiffLck_Tq_RqMn 4095 "Faulty" ;
VAL_ 1042 VehPtch_An_Dsply 127 "Faulty" 126 "NoDataExists" ;
VAL_ 138 SteWhlRelCalib_An_Sns 32767 "Fault" 32766 "NoDataExists" ;
VAL_ 133 SteWhlOSRelInit2An_Est 65535 "Fault" 65534 "Unknown" ;
VAL_ 133 SteWhlRelCalib_An_Sns 32767 "Fault" 32766 "NoDataExists" ;
VAL_ 133 StePw_B_Rq 1 "Yes" 0 "No" ;
VAL_ 133 SteWhlRelInit2_An_Sns 65535 "Faulty" 65534 "NoDataExists" ;
VAL_ 980 AdbBrdr1DistRigh_D_Stat 15 "DistGreater800m" 14 "Dist700mTo800m" 13 "Dist600mTo700m" 12 "Dist500mTo600m" 11 "Dist400mTo500m" 10 "Dist300mTo400m" 9 "Dist200mTo300m" 8 "Dist175mTo200m" 7 "Dist150mTo175m" 6 "Dist125mTo150m" 5 "Dist100mTo125m" 4 "Dist75mTo100m" 3 "Dist50mTo75m" 2 "Dist25mTo50m" 1 "Dist15mTo25m" 0 "Dist0mTo15m" ;
VAL_ 980 AdbBrdr1DistLeft_D_Stat 15 "DistGreater800m" 14 "Dist700mTo800m" 13 "Dist600mTo700m" 12 "Dist500mTo600m" 11 "Dist400mTo500m" 10 "Dist300mTo400m" 9 "Dist200mTo300m" 8 "Dist175mTo200m" 7 "Dist150mTo175m" 6 "Dist125mTo150m" 5 "Dist100mTo125m" 4 "Dist75mTo100m" 3 "Dist50mTo75m" 2 "Dist25mTo50m" 1 "Dist15mTo25m" 0 "Dist0mTo15m" ;
VAL_ 980 AdbMde1_D_Rq 3 "MarkerLightFlashing" 2 "MarkerLightConstant" 1 "Spot" 0 "None" ;
VAL_ 980 AdbIntns1_D_Rq 3 "Maximum" 2 "Medium" 1 "Low" 0 "Off" ;
VAL_ 980 AdbBrdr1Up_An_Rq 511 "Faulty" 510 "NoDataExists" ;
VAL_ 980 AdbBrdr1Right_An_Rq 2047 "Faulty" 2046 "NoDataExists" ;
VAL_ 980 AdbBrdr1Low_An_Rq 511 "Faulty" 510 "NoDataExists" ;
VAL_ 980 AdbBrdr1Left_An_Rq 2047 "Faulty" 2046 "NoDataExists" ;
VAL_ 1200 BrkRearPCorrltn_B_Stat 1 "Yes" 0 "No" ;
VAL_ 1200 HsaTrnAout_Tq_Rq 65535 "Fault" 65534 "Unknown" ;
VAL_ 1200 BrkBstrVac_P_Actl 127 "Invalid" ;
VAL_ 1200 YawStabilityIndex 511 "Fault" 510 "NoDataExists" ;
VAL_ 1200 BrkTot_Tq_RqDrv 8191 "Fault" ;
VAL_ 1200 BrkHold_D_Stat 7 "NotUsed_3" 6 "NotUsed_2" 5 "NotUsed_1" 4 "HeldSecondary" 3 "HeldSecure" 2 "Held" 1 "Inactive" 0 "Off" ;
VAL_ 1200 HsaStat_D_Dsply 7 "NotUsed3" 6 "NotUsed2" 5 "NotUsed1" 4 "NotAvailable" 3 "SlowReleaseWithChime" 2 "SlowReleaseWithoutChime" 1 "Active" 0 "Inactive" ;
VAL_ 1106 TrlrSnsId_No_Actl -1 "Faulty_FFFFFFFFFFFF" -2 "NoDataExists_FFFFFFFFFFFE" ;
VAL_ 945 PrkLckCtlMsgTxt_D2_Rq 7 "Message7" 6 "Message6" 5 "Message5" 4 "Message4" 3 "Message3" 2 "Message2" 1 "Message1" 0 "NoMessage" ;
VAL_ 945 KeyPadCodeDgt7_D_Dsply 15 "NotUsed_4" 14 "NotUsed_3" 13 "NotUsed_2" 12 "NotUsed_1" 11 "Button7_8and9_0" 10 "Button0" 9 "Button9_0or9" 8 "Button8" 7 "Button7_8or7" 6 "Button6" 5 "Button5_6or5" 4 "Button4" 3 "Button3_4or3" 2 "Button2" 1 "Button1_2or1" 0 "EndofString" ;
VAL_ 945 KeyPadCodeDgt6_D_Dsply 15 "NotUsed_4" 14 "NotUsed_3" 13 "NotUsed_2" 12 "NotUsed_1" 11 "Button7_8and9_0" 10 "Button0" 9 "Button9_0or9" 8 "Button8" 7 "Button7_8or7" 6 "Button6" 5 "Button5_6or5" 4 "Button4" 3 "Button3_4or3" 2 "Button2" 1 "Button1_2or1" 0 "EndofString" ;
VAL_ 945 KeyPadCodeDgt5_D_Dsply 15 "NotUsed_4" 14 "NotUsed_3" 13 "NotUsed_2" 12 "NotUsed_1" 11 "Button7_8and9_0" 10 "Button0" 9 "Button9_0or9" 8 "Button8" 7 "Button7_8or7" 6 "Button6" 5 "Button5_6or5" 4 "Button4" 3 "Button3_4or3" 2 "Button2" 1 "Button1_2or1" 0 "EndofString" ;
VAL_ 945 KeyPadCodeDgt4_D_Dsply 15 "NotUsed_4" 14 "NotUsed_3" 13 "NotUsed_2" 12 "NotUsed_1" 11 "Button7_8and9_0" 10 "Button0" 9 "Button9_0or9" 8 "Button8" 7 "Button7_8or7" 6 "Button6" 5 "Button5_6or5" 4 "Button4" 3 "Button3_4or3" 2 "Button2" 1 "Button1_2or1" 0 "EndofString" ;
VAL_ 945 KeyPadCodeDgt3_D_Dsply 15 "NotUsed_4" 14 "NotUsed_3" 13 "NotUsed_2" 12 "NotUsed_1" 11 "Button7_8and9_0" 10 "Button0" 9 "Button9_0or9" 8 "Button8" 7 "Button7_8or7" 6 "Button6" 5 "Button5_6or5" 4 "Button4" 3 "Button3_4or3" 2 "Button2" 1 "Button1_2or1" 0 "EndofString" ;
VAL_ 945 KeyPadCodeDgt2_D_Dsply 15 "NotUsed_4" 14 "NotUsed_3" 13 "NotUsed_2" 12 "NotUsed_1" 11 "Button7_8and9_0" 10 "Button0" 9 "Button9_0or9" 8 "Button8" 7 "Button7_8or7" 6 "Button6" 5 "Button5_6or5" 4 "Button4" 3 "Button3_4or3" 2 "Button2" 1 "Button1_2or1" 0 "EndofString" ;
VAL_ 945 KeyPadCodeDgt1_D_Dsply 15 "NotUsed_4" 14 "NotUsed_3" 13 "NotUsed_2" 12 "NotUsed_1" 11 "Button7_8and9_0" 10 "Button0" 9 "Button9_0or9" 8 "Button8" 7 "Button7_8or7" 6 "Button6" 5 "Button5_6or5" 4 "Button4" 3 "Button3_4or3" 2 "Button2" 1 "Button1_2or1" 0 "EndofString" ;
VAL_ 945 KeyOffMde_D_Actl 15 "NotUsed_11" 14 "NotUsed_10" 13 "NotUsed_9" 12 "NotUsed_8" 11 "NotUsed_7" 10 "NotUsed_6" 9 "NotUsed_5" 8 "NotUsed_4" 7 "NotUsed_3" 6 "NotUsed_2" 5 "NotUsed_1" 4 "CriticalBattery" 3 "Hibernate" 2 "Transport" 1 "Factory" 0 "Normal" ;
VAL_ 945 PrkLckCtlLatch_B_Rq 1 "On" 0 "Off" ;
VAL_ 1122 GpsHsphLongEast_D_Actl 0 "Invalid" 1 "Eastern" 2 "Western" 3 "Fault" ;
VAL_ 1122 GpsHsphLattSth_D_Actl 3 "Fault" 2 "Northern" 1 "Southern" 0 "Invalid" ;
VAL_ 1122 GPS_Longitude_Minutes 63 "Fault" 62 "Unknown" ;
VAL_ 1122 GPS_Longitude_Min_dec 16383 "Invalid" 16382 "Unknown" ;
VAL_ 1122 GPS_Longitude_Degrees 511 "Fault" 510 "Unknown" ;
VAL_ 1122 GPS_Latitude_Minutes 63 "Fault" 62 "Unknown" ;
VAL_ 1122 GPS_Latitude_Min_dec 16383 "Invalid" 16382 "Unknown" ;
VAL_ 1122 GPS_Latitude_Degrees 255 "Invalid" 254 "Unknown" ;
VAL_ 1080 TrlrAidMde_D_Rq_UB 1 "Fresh_data" 0 "Unchanged_data" ;
VAL_ 1080 TrlrAidMde_D_Rq 3 "Mode_3" 2 "Mode_2" 1 "Mode_1" 0 "NoRequest" ;
VAL_ 1080 Rba_D_Rq_UB 1 "Fresh_data" 0 "Unchanged_data" ;
VAL_ 1080 Rba_D_Rq 3 "NotUsed" 2 "On" 1 "Off" 0 "Null" ;
VAL_ 1080 TrailCtlSwtch_B_Stat_UB 1 "Fresh_data" 0 "Unchanged_data" ;
VAL_ 1080 TrailCtlSwtch_B_Stat 1 "Pressed" 0 "Not_Pressed" ;
VAL_ 1080 TrailCtlPt_B_Falt_UB 1 "Fresh_data" 0 "Unchanged_data" ;
VAL_ 1080 TrailCtlPt_B_Falt 1 "Fault" 0 "No_Fault" ;
VAL_ 1080 AutoTowActv_B_Stat_UB 1 "Fresh_data" 0 "Unchanged_data" ;
VAL_ 1080 AutoTowActv_B_Stat 1 "Yes" 0 "No" ;
VAL_ 1080 DrLatchLckRr_B_Stat_UB 1 "Fresh_data" 0 "Unchanged_data" ;
VAL_ 1080 DrLatchLckRl_B_Stat_UB 1 "Fresh_data" 0 "Unchanged_data" ;
VAL_ 1080 DrLatchLckFr_B_Stat_UB 1 "Fresh_data" 0 "Unchanged_data" ;
VAL_ 1080 DrLatchLckFl_B_Stat_UB 1 "Fresh_data" 0 "Unchanged_data" ;
VAL_ 1080 DrLatchRr_B_Falt_UB 1 "Fresh_data" 0 "Unchanged_data" ;
VAL_ 1080 DrLatchRl_B_Falt_UB 1 "Fresh_data" 0 "Unchanged_data" ;
VAL_ 1080 DrLatchFr_B_Falt_UB 1 "Fresh_data" 0 "Unchanged_data" ;
VAL_ 1080 DrLatchFl_B_Falt_UB 1 "Fresh_data" 0 "Unchanged_data" ;
VAL_ 1080 DrLatchCntRr_No_Actl_UB 1 "Fresh_data" 0 "Unchanged_data" ;
VAL_ 1080 DrLatchCntRl_No_Actl_UB 1 "Fresh_data" 0 "Unchanged_data" ;
VAL_ 1080 DrLatchCntFr_No_Actl_UB 1 "Fresh_data" 0 "Unchanged_data" ;
VAL_ 1080 DrLatchCntFl_No_Actl_UB 1 "Fresh_data" 0 "Unchanged_data" ;
VAL_ 1080 DrLatchRr_B_Falt 1 "Yes" 0 "No" ;
VAL_ 1080 DrLatchRl_B_Falt 1 "Yes" 0 "No" ;
VAL_ 1080 DrLatchLckRr_B_Stat 1 "Locked" 0 "Unlock" ;
VAL_ 1080 DrLatchLckRl_B_Stat 1 "Locked" 0 "Unlock" ;
VAL_ 1080 DrLatchLckFr_B_Stat 1 "Locked" 0 "Unlock" ;
VAL_ 1080 DrLatchLckFl_B_Stat 1 "Locked" 0 "Unlock" ;
VAL_ 1080 DrLatchFr_B_Falt 1 "Yes" 0 "No" ;
VAL_ 1080 DrLatchFl_B_Falt 1 "Yes" 0 "No" ;
VAL_ 1080 TurnLghtSwtch_D_Stat2_UB 1 "Fresh_data" 0 "Unchanged_data" ;
VAL_ 1080 TurnLghtSwtch_D_Stat2 3 "NotUsed" 2 "Right" 1 "Left" 0 "Off" ;
VAL_ 1080 CabnAmb_Te_Actl_UB 1 "Fresh_data" 0 "Unchanged_data" ;
VAL_ 1080 CabnAmb_Te_Actl 255 "Fault" ;
VAL_ 1080 HeadLghtHiPrmsn_D_Stat_UB 1 "Fresh_data" 0 "Unchanged_data" ;
VAL_ 1080 HeadLghtHiPrmsn_D_Stat 3 "CancelAndSuppress" 2 "Cancel" 1 "Hold" 0 "AllowChange" ;
VAL_ 1121 OffRdSwtch_D_RqMnu 3 "Faulty" 2 "NoRequest" 1 "On" 0 "Off" ;
VAL_ 1121 SelDrvMdeSwtchOk_D_Stat 3 "Faulty" 2 "Pressed" 1 "NotPressed" 0 "Null" ;
VAL_ 1121 AutoHoldSwtch_D_Stat2 3 "Faulty" 2 "NotUsed" 1 "Pressed" 0 "Not_Pressed" ;
VAL_ 1121 PrkAidSwtch_D_RqDrv3 1 "Pressed" 0 "Not_Pressed" ;
VAL_ 1121 ApaSwtch_D_RqDrv3 3 "NotUsed2" 2 "NotUsed1" 1 "Pressed" 0 "Not_Pressed" ;
VAL_ 1121 StopStrtDrvMde_B_RqBtn2 1 "Pressed" 0 "Not_Pressed" ;
VAL_ 1121 SelDrvMdeSwtch_D_Stat 3 "Faulty" 2 "SwitchState2" 1 "SwitchState1" 0 "NotPressed" ;
VAL_ 1121 SelDrvMdeCnt_D_Stat 4 "FourCounts" 3 "ThreeCounts" 2 "TwoCounts" 1 "OneCount" 0 "ZeroCounts" 7 "SevenOrMoreCounts" 6 "SixCounts" 5 "FiveCounts" ;
VAL_ 517 FapLc_B_Err 1 "Yes" 0 "No" ;
VAL_ 673 ICI_Coding_BtnID_D 15 "Idle" 5 "Stuck" 4 "LongEvent" 3 "ShortElapsed" 2 "ShortEvent" 1 "Active" 0 "Inactive" ;
VAL_ 673 ICI_Coding_BtnID_C 15 "Idle" 5 "Stuck" 4 "LongEvent" 3 "ShortElapsed" 2 "ShortEvent" 1 "Active" 0 "Inactive" ;
VAL_ 673 ICI_Coding_BtnID_B 15 "Idle" 5 "Stuck" 4 "LongEvent" 3 "ShortElapsed" 2 "ShortEvent" 1 "Active" 0 "Inactive" ;
VAL_ 673 ICI_Coding_BtnID_A 15 "Idle" 5 "Stuck" 4 "LongEvent" 3 "ShortElapsed" 2 "ShortEvent" 1 "Active" 0 "Inactive" ;
VAL_ 845 SeatMasgPsngr_D_Stat 15 "NotUsed_10" 14 "NotUsed_9" 13 "NotUsed_8" 12 "NotUsed_7" 11 "NotUsed_6" 10 "Pattern10" 9 "Pattern9" 8 "Pattern8" 7 "Pattern7" 6 "Pattern6" 5 "Pattern5" 4 "Pattern4" 3 "Pattern3" 2 "Pattern2" 1 "Pattern1" 0 "Null" ;
VAL_ 845 SeatIntnsPsngr_D_Stat 7 "NotUsed_3" 6 "NotUsed_2" 5 "NotUsed_1" 4 "High" 3 "Medium" 2 "Low" 1 "Off" 0 "Null" ;
VAL_ 845 StmsLmbrPsgr_D_Stat 3 "High" 2 "Low" 1 "Off" 0 "Null" ;
VAL_ 845 StmsCshnPsgr_D_Stat 3 "High" 2 "Low" 1 "Off" 0 "Null" ;
VAL_ 845 SeatSwtchPsgr_B_Stat 1 "On" 0 "Off" ;
VAL_ 845 SeatPPsgr_B_Stat 1 "Updating" 0 "NotUpdating" ;
VAL_ 845 SeatFnPsgr_D_Stat 7 "CushionMassage" 6 "LumbarMassage" 5 "UpperBolster" 4 "LowerBolster" 3 "UpperLumbar" 2 "MiddleLumbar" 1 "LowerLumbar" 0 "Null" ;
VAL_ 845 PsgrMemFeedback_Rsp 8 "Recall_4" 7 "Recall_3" 6 "Recall_2" 5 "Recall_1" 4 "Store_4" 3 "Store_3" 2 "Store_2" 1 "Store_1" 0 "Inactive" ;
VAL_ 850 SeatCshnPsgrRR_Pc_Actl 127 "Null" ;
VAL_ 850 SeatCshnPsgrRL_Pc_Actl 127 "Null" ;
VAL_ 850 SeatCshnPsgrFR_Pc_Actl 127 "Null" ;
VAL_ 850 SeatCshnPsgrFL_Pc_Actl 127 "Null" ;
VAL_ 850 SeatBlLoPsgr_Pc_Actl2 127 "Null" ;
VAL_ 820 TurnLampFrOut_B_Stat 1 "Out" 0 "Null" ;
VAL_ 820 TurnLampFlOut_B_Stat 1 "Out" 0 "Null" ;
VAL_ 820 AhbStatGfhbFdbk_D_Actl 3 "GfhbHighBeamFullyOn" 2 "GfhbHighBeamPartlyOn" 1 "GfhbHighBeamOff" 0 "GfhbUnavailable" ;
VAL_ 820 HeadLghtDrvSide_B_Stat 1 "Left_Hand_Traffic" 0 "Right_Hand_Traffic" ;
VAL_ 820 HeadLghtHiOn_B_StatHcm 1 "On" 0 "Off" ;
VAL_ 820 Adaptive_Hdlmp_Fault 1 "Yes" 0 "No" ;
VAL_ 935 SodInnrRight_D_Stat 3 "Reporting" 2 "Not_Reporting" 1 "System_Standby" 0 "Initialization" ;
VAL_ 935 RbaCtaRight_D_Stat 7 "Faulty" 6 "NotUsed_2" 5 "NotUsed_1" 4 "Invalid" 3 "Disabled" 2 "On" 1 "Trailer_Tow_Off" 0 "Off" ;
VAL_ 935 LcwaRight_D_Stat 7 "Faulty" 6 "NotUsed_3" 5 "NotUsed_2" 4 "NotUsed_1" 3 "Disabled" 2 "TemporaryUnavailable" 1 "SensorBlocked" 0 "Available" ;
VAL_ 935 LcwaDetctRight2_B_Stat 1 "Yes" 0 "No" ;
VAL_ 935 LcwaDetctRight1_B_Stat 1 "Yes" 0 "No" ;
VAL_ 935 CtaInnrRight_D_Stat 3 "Reporting" 2 "Not_Reporting" 1 "System_Standby" 0 "Initialization" ;
VAL_ 935 CtaAlrtRight2_D_Stat 7 "NotUsed3" 6 "NotUsed2" 5 "NotUsed1" 4 "AlertZone4" 3 "AlertZone3" 2 "AlertZone2" 1 "AlertZone1" 0 "Off" ;
VAL_ 935 BttRight_D_Stat 7 "NotUsed" 6 "Disabled" 5 "Off" 4 "OffTemp" 3 "NotConnected" 2 "Pending" 1 "Connected" 0 "NotDetermined" ;
VAL_ 935 BttRight_D_RqDrv 3 "NotUsed" 2 "Request" 1 "NoRequest" 0 "Null" ;
VAL_ 935 CtaBrkRightMsgTxt_B_Rq 1 "Enable" 0 "Disable" ;
VAL_ 935 CtaRightBrkEnbl_B_Rq 1 "Enable" 0 "Disable" ;
VAL_ 935 CtaSnsRight_D_Stat 3 "Invalid" 2 "System_Failure" 1 "Blocked" 0 "Clear" ;
VAL_ 935 CtaAlrtRight_D_Stat 1 "On" 0 "Off" ;
VAL_ 935 CtaRight_D_Stat 7 "NotUsed_3" 6 "NotUsed_2" 5 "NotUsed_1" 4 "Invalid" 3 "Disabled" 2 "On" 1 "Trailer_Tow_Off" 0 "Off" ;
VAL_ 935 SodRight_D_Stat 7 "NotUsed_3" 6 "NotUsed_2" 5 "NotUsed_1" 4 "Invalid" 3 "Disabled" 2 "On" 1 "Trailer_Tow_Off" 0 "Off" ;
VAL_ 935 SodSnsRight_D_Stat 3 "Second_Warning_Audio" 2 "System_Failure" 1 "Blocked" 0 "Clear" ;
VAL_ 935 SodAlrtRight_D_Stat 3 "Bulb_Proveout" 2 "Flash" 1 "On" 0 "Off" ;
VAL_ 935 SodDetctRight_D_Stat 4 "Sensor_Blocked" 3 "Sensor_Fault" 2 "Flash_On" 1 "Alert_On" 0 "AlertOff_FlashOff_SensrClr" ;
VAL_ 935 CtaRightBrkDecel_B_Rq 1 "Enable" 0 "Disable" ;
VAL_ 934 SodInnrLeft_D_Stat 3 "Reporting" 2 "Not_Reporting" 1 "System_Standby" 0 "Initialization" ;
VAL_ 934 RbaCtaLeft_D_Stat 7 "Faulty" 6 "NotUsed_2" 5 "NotUsed_1" 4 "Invalid" 3 "Disabled" 2 "On" 1 "Trailer_Tow_Off" 0 "Off" ;
VAL_ 934 LcwaLeft_D_Stat 7 "Faulty" 6 "NotUsed_3" 5 "NotUsed_2" 4 "NotUsed_1" 3 "Disabled" 2 "TemporaryUnavailable" 1 "SensorBlocked" 0 "Available" ;
VAL_ 934 LcwaDetctLeft2_B_Stat 1 "Yes" 0 "No" ;
VAL_ 934 LcwaDetctLeft1_B_Stat 1 "Yes" 0 "No" ;
VAL_ 934 CtaInnrLeft_D_Stat 3 "Reporting" 2 "Not_Reporting" 1 "System_Standby" 0 "Initialization" ;
VAL_ 934 CtaAlrtLeft2_D_Stat 7 "NotUsed3" 6 "NotUsed2" 5 "NotUsed1" 4 "AlertZone4" 3 "AlertZone3" 2 "AlertZone2" 1 "AlertZone1" 0 "Off" ;
VAL_ 934 BttLeft_D_Stat 7 "NotUsed" 6 "Disabled" 5 "Off" 4 "OffTemp" 3 "NotConnected" 2 "Pending" 1 "Connected" 0 "NotDetermined" ;
VAL_ 934 BttLeft_D_RqDrv 3 "NotUsed" 2 "Request" 1 "NoRequest" 0 "Null" ;
VAL_ 934 CtaBrkLeftMsgTxt_B_Rq 1 "Enable" 0 "Disable" ;
VAL_ 934 CtaLeftBrkDecel_B_Rq 1 "Enable" 0 "Disable" ;
VAL_ 934 CtaLeftBrkEnbl_B_Rq 1 "Enable" 0 "Disable" ;
VAL_ 934 CtaSnsLeft_D_Stat 3 "Invalid" 2 "System_Failure" 1 "Blocked" 0 "Clear" ;
VAL_ 934 SodDetctLeft_D_Stat 4 "Sensor_Blocked" 3 "Sensor_Fault" 2 "Flash_On" 1 "Alert_On" 0 "AlertOff_FlashOff_SensrClr" ;
VAL_ 934 CtaLeft_D_Stat 7 "NotUsed_3" 6 "NotUsed_2" 5 "NotUsed_1" 4 "Invalid" 3 "Disabled" 2 "On" 1 "Trailer_Tow_Off" 0 "Off" ;
VAL_ 934 CtaAlrtLeft_D_Stat 1 "On" 0 "Off" ;
VAL_ 934 SodLeft_D_Stat 7 "NotUsed_3" 6 "NotUsed_2" 5 "NotUsed_1" 4 "Invalid" 3 "Disabled" 2 "On" 1 "Trailer_Tow_Off" 0 "Off" ;
VAL_ 934 SodSnsLeft_D_Stat 3 "Second_Warning_Audio" 2 "System_Failure" 1 "Blocked" 0 "Clear" ;
VAL_ 934 SodAlrtLeft_D_Stat 3 "Bulb_Proveout" 2 "Flash" 1 "On" 0 "Off" ;
VAL_ 1073 CamraFrntBttn_D_Stat 1 "Pressed" 0 "Not_Pressed" ;
VAL_ 1073 CamraFrntBttn_D_Stat_UB 1 "Fresh_data" 0 "Unchanged_data" ;
VAL_ 1073 BrkDrvMde_D_Rq_UB 1 "Fresh_data" 0 "Unchanged_data" ;
VAL_ 1073 BrkDrvMde_D_Rq 7 "Faulty" 6 "RockCrawl" 5 "Baja" 4 "DragOrMudAndSand" 3 "Track" 2 "Snow_Wet" 1 "Sport" 0 "Normal" ;
VAL_ 1073 SteEffort_D_Rq 7 "NotUsed_3" 6 "NotUsed_2" 5 "NotUsed_1" 4 "SpecialMode_2" 3 "SpecialMode_1" 2 "Comfort" 1 "Sport" 0 "Normal" ;
VAL_ 1073 SteEffort_D_Rq_UB 1 "Fresh_data" 0 "Unchanged_data" ;
VAL_ 1073 AutoHoldSwtch_D_Stat_UB 1 "Fresh_data" 0 "Unchanged_data" ;
VAL_ 1073 AutoHoldSwtch_D_Stat 3 "Faulty" 2 "NotUsed" 1 "Pressed" 0 "Not_Pressed" ;
VAL_ 1073 HMI_HMIMode_St_UB 1 "Fresh_data" 0 "Unchanged_data" ;
VAL_ 1073 HMI_HMIMode_St 7 "NotUsed2" 6 "NotUsed1" 5 "Load_Shed_Active" 0 "Invalid" 1 "OffMode" 2 "On" 3 "Phone" 4 "Climate" ;
VAL_ 1073 Veh_Lock_Requestor_UB 1 "Fresh_data" 0 "Unchanged_data" ;
VAL_ 1073 Veh_Lock_EvNum_UB 1 "Fresh_data" 0 "Unchanged_data" ;
VAL_ 1073 Veh_Lock_Sub_Id_UB 1 "Fresh_data" 0 "Unchanged_data" ;
VAL_ 1073 Tire_Press_System_Stat_UB 1 "Fresh_data" 0 "Unchanged_data" ;
VAL_ 1073 Veh_Lock_Status_UB 1 "Fresh_data" 0 "Unchanged_data" ;
VAL_ 1073 Veh_Lock_Sub_Id 15 "Unused7" 14 "Unused6" 13 "Unused5" 12 "Unused4" 11 "Unused3" 10 "Unused2" 9 "Unused1" 8 "Customer_8" 7 "Customer_7" 6 "Customer_6" 5 "Customer_5" 4 "Customer_4" 3 "Customer_3" 2 "Customer_2" 1 "Customer_1" 0 "Null" ;
VAL_ 1073 Veh_Lock_Status 3 "UNLOCK_DRV" 2 "UNLOCK_ALL" 1 "LOCK_ALL" 0 "LOCK_DBL" ;
VAL_ 1073 Veh_Lock_Requestor 31 "Walk_Away_Locking" 30 "Remote_Park_Assist" 29 "DoorsOffToOn_Smart_Unlock" 28 "Rgtm_Shutlock_Switch" 27 "Boundary_Alert" 26 "Transit_Vehicle_Relock" 25 "Transit_Cargo_Relock" 24 "Transit_Ajar_Lock" 23 "Diagnostics" 22 "Console_Lock" 21 "Child_Lock" 20 "Double_Lock" 19 "Passive_Pasenger" 18 "Passive_Driver" 17 "Slam_Lock_Protect" 16 "SYNC" 15 "Passport" 14 "Passive_Smart_Unlock" 13 "Autorelock" 12 "RemoteStart" 0 "Null" 1 "Autolock" 11 "Smart_Unlock" 10 "Sliding_Door" 9 "Passive" 8 "Remote" 7 "Programming" 6 "Powerslide" 5 "Keypad" 4 "Key_Cylinder" 3 "Interior" 2 "Auto_Unlock" ;
VAL_ 1073 Tire_Press_System_Stat 13 "Training_Complete" 12 "Train_InsideLeftRear_tire" 11 "Train_OutsideLeftRear_tire" 10 "Train_LeftRear_tire" 9 "Train_InsideRtRear_tire" 8 "Train_OutsideRtRear_tire" 7 "Train_RightRear_tire" 14 "Tires_not_trained" 6 "Train_RightFront_tire" 5 "Train_LeftFront_tire" 4 "Systm_Activ_Composite_Stat" 3 "Low_Composite_Stat" 2 "Sensr_Fault_Composite_Stat" 1 "Systm_Fault_Composite_Stat" 0 "Unknown_Composite_Stat" ;
VAL_ 1073 DISPLAY_SPEED_OFFSET_UB 1 "Fresh_data" 0 "Unchanged_data" ;
VAL_ 1073 DISPLAY_SPEED_SCALING_UB 1 "Fresh_data" 0 "Unchanged_data" ;
VAL_ 1073 Foh_D_Stat 7 "Unused3" 6 "Unused2" 5 "Unused1" 4 "Stopping" 3 "Running" 2 "Starting" 1 "Prestart" 0 "Off" ;
VAL_ 1073 Foh_D_Stat_UB 1 "Fresh_data" 0 "Unchanged_data" ;
VAL_ 1073 SteWhlHeat_D_Rq_UB 1 "Fresh_data" 0 "Unchanged_data" ;
VAL_ 1073 SteWhlHeat_D_Rq 15 "NotUsed6" 14 "NotUsed5" 13 "NotUsed4" 12 "NotUsed3" 11 "NotUsed2" 10 "NotUsed1" 9 "Reserved_3" 8 "Reserved_2" 7 "Reserved_1" 6 "Level_3_Heating" 5 "Level_3_Heating_LS" 4 "Level_2_Heating" 3 "Level_2_Heating_LS" 2 "Level_1_Heating" 1 "Level_1_Heating_LS" 0 "Off" ;
VAL_ 71 immoTarget1Status 7 "Unused4" 6 "Unused3" 5 "Unused2" 4 "ENABLED_LIMITEDMOTIVE_STAR" 3 "DISABLED_RESET   " 2 "ENABLED_NONMOTIVE_START" 1 "ENABLED_MOTIVE_START" 0 "DISABLED" ;
VAL_ 71 immoTarget1Cmd 7 "Unused4" 6 "Unused3" 5 "Unused2" 4 "Unused1" 3 "TARGET1_IDBLOCK2" 2 "TARGET1_IDBLOCK1" 1 "CHALLENGE" 0 "IDLE" ;
VAL_ 973 PersCtaSplitView_D_Stat 3 "EnabledFull" 2 "Enabled_180SwitchOnly" 1 "Disabled" 0 "Null" ;
VAL_ 973 LaSysOffStat_D_Dsply 3 "Level_3" 2 "Level_2" 1 "Level_1" 0 "Level_0" ;
VAL_ 973 TsrVl2PrmntMsgTxt_D_Rq 3 "NotUsed" 2 "ShowPermanentlyWithSupp" 1 "ShowPermanentlyWithoutSupp" 0 "DoNotShowSignPermanent" ;
VAL_ 973 TsrVl1PrmntMsgTxt_D_Rq 3 "NotUsed" 2 "ShowPermanentlyWithSupp" 1 "ShowPermanentlyWithoutSupp" 0 "DoNotShowSignPermanent" ;
VAL_ 973 TsrVl2RstrcMsgTxt2_D_Rq 7 "NotUsed" 6 "Time" 5 "Trailer" 4 "Snow" 3 "RainWet" 2 "NoRecognizableRestrictn" 1 "NoSpeedLimitRestrictn" 0 "Null" ;
VAL_ 973 TsrVl1RstrcMsgTxt2_D_Rq 7 "NotUsed" 6 "Time" 5 "Trailer" 4 "Snow" 3 "RainWet" 2 "NoRecognizableRestrictn" 1 "NoSpeedLimitRestrictn" 0 "Null" ;
VAL_ 973 TsrOvtkMsgTxt2_D_Rq 15 "NotUsed5" 14 "NotUsed4" 13 "NotUsed3" 12 "NotUsed2" 11 "NotUsed1" 10 "LimForTrucksCancelled" 9 "LimForTrucksWoQlfdRstrc" 8 "LimForTrucksWithoutRstrc" 7 "LimAllCancelled" 6 "LimAllWithRstrcTime" 5 "LimAllWithRstrcTrailer" 4 "LimAllWithRstrcSnow" 3 "LimAllWithRstrcRain" 2 "LimAllWithoutQlfdRstrc" 1 "LimAllWithoutRestriction" 0 "OvertakingAllowed" ;
VAL_ 973 WwaWarn_B_Rq 1 "On" 0 "Off" ;
VAL_ 973 TsrVlUnitMsgTxt_D_Rq 3 "NoDataExists" 2 "Mph" 1 "Kph" 0 "Null" ;
VAL_ 973 TsrVLim2MsgTxt_D_Rq 255 "NoLimit" 254 "NotUsed2" 253 "NotUsed1" 252 "NotToBeDisplayed" 251 "LimitCancelled" 31 "1F_FA_Message31_250" 30 "Message30" 29 "Message29" 28 "Message28" 27 "Message27" 26 "Message26" 25 "Message25" 24 "Message24" 23 "Message23" 22 "Message22" 21 "Message21" 20 "Message20" 19 "Message19" 18 "Message18" 17 "Message17" 16 "Message16" 15 "Message15" 14 "Message14" 13 "Message13" 12 "Message12" 11 "Message11" 10 "Message10" 9 "Message9" 8 "Message8" 7 "Message7" 6 "Message6" 5 "Message5" 4 "Message4" 3 "Message3" 2 "Message2" 1 "Message1" 0 "Null" ;
VAL_ 973 TsrVLim1MsgTxt_D_Rq 255 "NoLimit" 254 "NotUsed2" 253 "NotUsed1" 252 "NotToBeDisplayed" 251 "LimitCancelled" 31 "1F_FA_Message31_250" 30 "Message30" 29 "Message29" 28 "Message28" 27 "Message27" 26 "Message26" 25 "Message25" 24 "Message24" 23 "Message23" 22 "Message22" 21 "Message21" 20 "Message20" 19 "Message19" 18 "Message18" 17 "Message17" 16 "Message16" 15 "Message15" 14 "Message14" 13 "Message13" 12 "Message12" 11 "Message11" 10 "Message10" 9 "Message9" 8 "Message8" 7 "Message7" 6 "Message6" 5 "Message5" 4 "Message4" 3 "Message3" 2 "Message2" 1 "Message1" 0 "Null" ;
VAL_ 973 TsrVl2StatMsgTxt_D_Rq 3 "LimitOutdated" 2 "LimitReiable" 1 "LimitChanged" 0 "Null" ;
VAL_ 973 TsrVl2RstrcMsgTxt_D_Rq 3 "NotUsed" 2 "NoRecognizableRestriction" 1 "NoSpeedLimitRestriction" 0 "Null" ;
VAL_ 973 TsrVl1StatMsgTxt_D_Rq 3 "LimitOutdated" 2 "LimitReiable" 1 "LimitChanged" 0 "Null" ;
VAL_ 973 TsrVl1RstrcMsgTxt_D_Rq 3 "NotUsed" 2 "NoRecognizableRestriction" 1 "NoSpeedLimitRestriction" 0 "Null" ;
VAL_ 973 TsrStatMsgTxt_D_Rq 7 "NotUsed" 6 "NoDataExists" 5 "TSR_Error" 4 "Available_NavigationOnly" 3 "Available_CameraOnly" 2 "Available_FusionMode" 1 "TSR_Off" 0 "Null" ;
VAL_ 973 TsrOvtkStatMsgTxt_D_Rq 3 "LimitOutdated" 2 "LimitReiable" 1 "LimitChanged" 0 "Null" ;
VAL_ 973 TsrOvtkMsgTxt_D_Rq 7 "LimForTrucksCancelled" 6 "LimForTrucksWoQlfdRstrc" 5 "LimForTrucksWithoutRstrc" 4 "LimAllCancelled" 3 "LimAllWithoutQlfdRstrc" 2 "LimAllWithoutRestriction" 1 "OvertakingAllowed" 0 "Null" ;
VAL_ 973 TsrOswWarnMsgTxt_D_Rq 3 "NotUsed" 2 "True" 1 "False" 0 "Null" ;
VAL_ 973 TsrMsgTxt_D_Rq 15 "NotUsed6" 14 "NotUsed5" 13 "NotUsed4" 12 "NotUsed3" 11 "NotUsed2" 10 "NotUsed1" 9 "RecgnzdSignNotUsblForDsply" 8 "LimitedSystemPerformance" 7 "OffRoad" 6 "RegionNotSupported" 5 "CountryNotSupported" 4 "WrngNavDatIncompDatCarrier" 3 "NoNavDataAvailable" 2 "NoNavAvailableSwitchedOff" 1 "NoInformationAllOK" 0 "Null" ;
VAL_ 837 VdmSustnActv_B_Rq 1 "Active" 0 "Inactive" ;
VAL_ 837 VehCurb_M_Actl 1023 "Faulty" 1022 "NoDataExists" ;
VAL_ 837 Ccd_B_Falt 1 "Yes" 0 "No" ;
VAL_ 837 SuspVLim_B_Rq 1 "True" 0 "False" ;
VAL_ 837 SelDrvMdeSusp_D_Stat 3 "Faulty" 2 "TemporarilyNotAvailable" 1 "Available" 0 "NotAvailable" ;
VAL_ 837 AdptDrvMdePt_D_Rq 7 "Faulty" 6 "NotUsed3" 5 "NotUsed2" 4 "NotUsed1" 3 "Powertrain2Sport" 2 "Powertrain2Normal" 1 "Powertrain2Comfort" 0 "AdaptiveNotActive" ;
VAL_ 837 AdptDrvMdeChassis_D_Rq 7 "Faulty" 6 "NotUsed3" 5 "NotUsed2" 4 "NotUsed1" 3 "Chassis2Sport" 2 "Chassis2Normal" 1 "Chassis2Comfort" 0 "AdaptiveNotActive" ;
VAL_ 837 AirSprngRateRr_D_Rq 3 "NoRequest" 2 "Firm" 1 "Medium" 0 "Soft" ;
VAL_ 837 AirSprngRateRl_D_Rq 3 "NoRequest" 2 "Firm" 1 "Medium" 0 "Soft" ;
VAL_ 837 SuspType_B_Stat 1 "Magnetic" 0 "NonMagnetic" ;
VAL_ 837 AirSprngRateFr_D_Rq 3 "NoRequest" 2 "Firm" 1 "Medium" 0 "Soft" ;
VAL_ 837 AirSprngRateFl_D_Rq 3 "NoRequest" 2 "Firm" 1 "Medium" 0 "Soft" ;
VAL_ 837 VehGvwr_M_Actl 1023 "Faulty" 1022 "NoDataExists" ;
VAL_ 837 AirSusp_D_Stat 3 "NotUsed" 2 "On" 1 "Off" 0 "Null" ;
VAL_ 837 AirSuspMsgTxt_D_Rq 3 "NotUsed" 2 "Faulty" 1 "Override" 0 "NoMessage" ;
VAL_ 837 SuspDrvMde_D_Stat 7 "Faulty" 6 "NotUsed2" 5 "NotUsed1" 4 "Drag" 3 "Track" 2 "Snow_Wet" 1 "Sport" 0 "Normal" ;
VAL_ 837 CcdMsgTxt_D_RqDsply 15 "Unused8" 14 "Unused7" 13 "Unused6" 12 "Unused5" 11 "Unused4" 10 "Unused3" 9 "Unused2" 8 "StationaryMode" 7 "Mode_Change_Unavailable" 6 "CCD_Temporarily_Off" 5 "CCD_Service_Required" 4 "Faulty" 3 "Sport" 2 "Normal" 1 "Comfort" 0 "No_Mode_Selected" ;
